VERSION ""

NS_ :

BS_ :

BU_: NMTMaster

BO_ 1919 HBGuard_127: 1 Vector__XXX
 SG_ Toggle : 7|1@1+ (1,0) [0|0] "" Vector__XXX
 SG_ State : 0|7@1+ (1,0) [0|0] "" Vector__XXX

BO_ 1918 HBGuard_126: 1 Vector__XXX
 SG_ Toggle : 7|1@1+ (1,0) [0|0] "" Vector__XXX
 SG_ State : 0|7@1+ (1,0) [0|0] "" Vector__XXX

BO_ 1917 HBGuard_125: 1 Vector__XXX
 SG_ Toggle : 7|1@1+ (1,0) [0|0] "" Vector__XXX
 SG_ State : 0|7@1+ (1,0) [0|0] "" Vector__XXX

BO_ 1916 HBGuard_124: 1 Vector__XXX
 SG_ Toggle : 7|1@1+ (1,0) [0|0] "" Vector__XXX
 SG_ State : 0|7@1+ (1,0) [0|0] "" Vector__XXX

BO_ 1915 HBGuard_123: 1 Vector__XXX
 SG_ Toggle : 7|1@1+ (1,0) [0|0] "" Vector__XXX
 SG_ State : 0|7@1+ (1,0) [0|0] "" Vector__XXX

BO_ 1914 HBGuard_122: 1 Vector__XXX
 SG_ Toggle : 7|1@1+ (1,0) [0|0] "" Vector__XXX
 SG_ State : 0|7@1+ (1,0) [0|0] "" Vector__XXX

BO_ 1913 HBGuard_121: 1 Vector__XXX
 SG_ Toggle : 7|1@1+ (1,0) [0|0] "" Vector__XXX
 SG_ State : 0|7@1+ (1,0) [0|0] "" Vector__XXX

BO_ 1912 HBGuard_120: 1 Vector__XXX
 SG_ Toggle : 7|1@1+ (1,0) [0|0] "" Vector__XXX
 SG_ State : 0|7@1+ (1,0) [0|0] "" Vector__XXX

BO_ 1911 HBGuard_119: 1 Vector__XXX
 SG_ Toggle : 7|1@1+ (1,0) [0|0] "" Vector__XXX
 SG_ State : 0|7@1+ (1,0) [0|0] "" Vector__XXX

BO_ 1910 HBGuard_118: 1 Vector__XXX
 SG_ Toggle : 7|1@1+ (1,0) [0|0] "" Vector__XXX
 SG_ State : 0|7@1+ (1,0) [0|0] "" Vector__XXX

BO_ 1909 HBGuard_117: 1 Vector__XXX
 SG_ Toggle : 7|1@1+ (1,0) [0|0] "" Vector__XXX
 SG_ State : 0|7@1+ (1,0) [0|0] "" Vector__XXX

BO_ 1908 HBGuard_116: 1 Vector__XXX
 SG_ Toggle : 7|1@1+ (1,0) [0|0] "" Vector__XXX
 SG_ State : 0|7@1+ (1,0) [0|0] "" Vector__XXX

BO_ 1907 HBGuard_115: 1 Vector__XXX
 SG_ Toggle : 7|1@1+ (1,0) [0|0] "" Vector__XXX
 SG_ State : 0|7@1+ (1,0) [0|0] "" Vector__XXX

BO_ 1906 HBGuard_114: 1 Vector__XXX
 SG_ Toggle : 7|1@1+ (1,0) [0|0] "" Vector__XXX
 SG_ State : 0|7@1+ (1,0) [0|0] "" Vector__XXX

BO_ 1905 HBGuard_113: 1 Vector__XXX
 SG_ Toggle : 7|1@1+ (1,0) [0|0] "" Vector__XXX
 SG_ State : 0|7@1+ (1,0) [0|0] "" Vector__XXX

BO_ 1904 HBGuard_112: 1 Vector__XXX
 SG_ Toggle : 7|1@1+ (1,0) [0|0] "" Vector__XXX
 SG_ State : 0|7@1+ (1,0) [0|0] "" Vector__XXX

BO_ 1903 HBGuard_111: 1 Vector__XXX
 SG_ Toggle : 7|1@1+ (1,0) [0|0] "" Vector__XXX
 SG_ State : 0|7@1+ (1,0) [0|0] "" Vector__XXX

BO_ 1902 HBGuard_110: 1 Vector__XXX
 SG_ Toggle : 7|1@1+ (1,0) [0|0] "" Vector__XXX
 SG_ State : 0|7@1+ (1,0) [0|0] "" Vector__XXX

BO_ 1901 HBGuard_109: 1 Vector__XXX
 SG_ Toggle : 7|1@1+ (1,0) [0|0] "" Vector__XXX
 SG_ State : 0|7@1+ (1,0) [0|0] "" Vector__XXX

BO_ 1900 HBGuard_108: 1 Vector__XXX
 SG_ Toggle : 7|1@1+ (1,0) [0|0] "" Vector__XXX
 SG_ State : 0|7@1+ (1,0) [0|0] "" Vector__XXX

BO_ 1899 HBGuard_107: 1 Vector__XXX
 SG_ Toggle : 7|1@1+ (1,0) [0|0] "" Vector__XXX
 SG_ State : 0|7@1+ (1,0) [0|0] "" Vector__XXX

BO_ 1898 HBGuard_106: 1 Vector__XXX
 SG_ Toggle : 7|1@1+ (1,0) [0|0] "" Vector__XXX
 SG_ State : 0|7@1+ (1,0) [0|0] "" Vector__XXX

BO_ 1897 HBGuard_105: 1 Vector__XXX
 SG_ Toggle : 7|1@1+ (1,0) [0|0] "" Vector__XXX
 SG_ State : 0|7@1+ (1,0) [0|0] "" Vector__XXX

BO_ 1896 HBGuard_104: 1 Vector__XXX
 SG_ Toggle : 7|1@1+ (1,0) [0|0] "" Vector__XXX
 SG_ State : 0|7@1+ (1,0) [0|0] "" Vector__XXX

BO_ 1895 HBGuard_103: 1 Vector__XXX
 SG_ Toggle : 7|1@1+ (1,0) [0|0] "" Vector__XXX
 SG_ State : 0|7@1+ (1,0) [0|0] "" Vector__XXX

BO_ 1894 HBGuard_102: 1 Vector__XXX
 SG_ Toggle : 7|1@1+ (1,0) [0|0] "" Vector__XXX
 SG_ State : 0|7@1+ (1,0) [0|0] "" Vector__XXX

BO_ 1893 HBGuard_101: 1 Vector__XXX
 SG_ Toggle : 7|1@1+ (1,0) [0|0] "" Vector__XXX
 SG_ State : 0|7@1+ (1,0) [0|0] "" Vector__XXX

BO_ 1892 HBGuard_100: 1 Vector__XXX
 SG_ Toggle : 7|1@1+ (1,0) [0|0] "" Vector__XXX
 SG_ State : 0|7@1+ (1,0) [0|0] "" Vector__XXX

BO_ 1891 HBGuard_099: 1 Vector__XXX
 SG_ Toggle : 7|1@1+ (1,0) [0|0] "" Vector__XXX
 SG_ State : 0|7@1+ (1,0) [0|0] "" Vector__XXX

BO_ 1890 HBGuard_098: 1 Vector__XXX
 SG_ Toggle : 7|1@1+ (1,0) [0|0] "" Vector__XXX
 SG_ State : 0|7@1+ (1,0) [0|0] "" Vector__XXX

BO_ 1889 HBGuard_097: 1 Vector__XXX
 SG_ Toggle : 7|1@1+ (1,0) [0|0] "" Vector__XXX
 SG_ State : 0|7@1+ (1,0) [0|0] "" Vector__XXX

BO_ 1888 HBGuard_096: 1 Vector__XXX
 SG_ Toggle : 7|1@1+ (1,0) [0|0] "" Vector__XXX
 SG_ State : 0|7@1+ (1,0) [0|0] "" Vector__XXX

BO_ 1887 HBGuard_095: 1 Vector__XXX
 SG_ Toggle : 7|1@1+ (1,0) [0|0] "" Vector__XXX
 SG_ State : 0|7@1+ (1,0) [0|0] "" Vector__XXX

BO_ 1886 HBGuard_094: 1 Vector__XXX
 SG_ Toggle : 7|1@1+ (1,0) [0|0] "" Vector__XXX
 SG_ State : 0|7@1+ (1,0) [0|0] "" Vector__XXX

BO_ 1885 HBGuard_093: 1 Vector__XXX
 SG_ Toggle : 7|1@1+ (1,0) [0|0] "" Vector__XXX
 SG_ State : 0|7@1+ (1,0) [0|0] "" Vector__XXX

BO_ 1884 HBGuard_092: 1 Vector__XXX
 SG_ Toggle : 7|1@1+ (1,0) [0|0] "" Vector__XXX
 SG_ State : 0|7@1+ (1,0) [0|0] "" Vector__XXX

BO_ 1883 HBGuard_091: 1 Vector__XXX
 SG_ Toggle : 7|1@1+ (1,0) [0|0] "" Vector__XXX
 SG_ State : 0|7@1+ (1,0) [0|0] "" Vector__XXX

BO_ 1882 HBGuard_090: 1 Vector__XXX
 SG_ Toggle : 7|1@1+ (1,0) [0|0] "" Vector__XXX
 SG_ State : 0|7@1+ (1,0) [0|0] "" Vector__XXX

BO_ 1881 HBGuard_089: 1 Vector__XXX
 SG_ Toggle : 7|1@1+ (1,0) [0|0] "" Vector__XXX
 SG_ State : 0|7@1+ (1,0) [0|0] "" Vector__XXX

BO_ 1880 HBGuard_088: 1 Vector__XXX
 SG_ Toggle : 7|1@1+ (1,0) [0|0] "" Vector__XXX
 SG_ State : 0|7@1+ (1,0) [0|0] "" Vector__XXX

BO_ 1879 HBGuard_087: 1 Vector__XXX
 SG_ Toggle : 7|1@1+ (1,0) [0|0] "" Vector__XXX
 SG_ State : 0|7@1+ (1,0) [0|0] "" Vector__XXX

BO_ 1878 HBGuard_086: 1 Vector__XXX
 SG_ Toggle : 7|1@1+ (1,0) [0|0] "" Vector__XXX
 SG_ State : 0|7@1+ (1,0) [0|0] "" Vector__XXX

BO_ 1877 HBGuard_085: 1 Vector__XXX
 SG_ Toggle : 7|1@1+ (1,0) [0|0] "" Vector__XXX
 SG_ State : 0|7@1+ (1,0) [0|0] "" Vector__XXX

BO_ 1876 HBGuard_084: 1 Vector__XXX
 SG_ Toggle : 7|1@1+ (1,0) [0|0] "" Vector__XXX
 SG_ State : 0|7@1+ (1,0) [0|0] "" Vector__XXX

BO_ 1875 HBGuard_083: 1 Vector__XXX
 SG_ Toggle : 7|1@1+ (1,0) [0|0] "" Vector__XXX
 SG_ State : 0|7@1+ (1,0) [0|0] "" Vector__XXX

BO_ 1874 HBGuard_082: 1 Vector__XXX
 SG_ Toggle : 7|1@1+ (1,0) [0|0] "" Vector__XXX
 SG_ State : 0|7@1+ (1,0) [0|0] "" Vector__XXX

BO_ 1873 HBGuard_081: 1 Vector__XXX
 SG_ Toggle : 7|1@1+ (1,0) [0|0] "" Vector__XXX
 SG_ State : 0|7@1+ (1,0) [0|0] "" Vector__XXX

BO_ 1872 HBGuard_080: 1 Vector__XXX
 SG_ Toggle : 7|1@1+ (1,0) [0|0] "" Vector__XXX
 SG_ State : 0|7@1+ (1,0) [0|0] "" Vector__XXX

BO_ 1871 HBGuard_079: 1 Vector__XXX
 SG_ Toggle : 7|1@1+ (1,0) [0|0] "" Vector__XXX
 SG_ State : 0|7@1+ (1,0) [0|0] "" Vector__XXX

BO_ 1870 HBGuard_078: 1 Vector__XXX
 SG_ Toggle : 7|1@1+ (1,0) [0|0] "" Vector__XXX
 SG_ State : 0|7@1+ (1,0) [0|0] "" Vector__XXX

BO_ 1869 HBGuard_077: 1 Vector__XXX
 SG_ Toggle : 7|1@1+ (1,0) [0|0] "" Vector__XXX
 SG_ State : 0|7@1+ (1,0) [0|0] "" Vector__XXX

BO_ 1868 HBGuard_076: 1 Vector__XXX
 SG_ Toggle : 7|1@1+ (1,0) [0|0] "" Vector__XXX
 SG_ State : 0|7@1+ (1,0) [0|0] "" Vector__XXX

BO_ 1867 HBGuard_075: 1 Vector__XXX
 SG_ Toggle : 7|1@1+ (1,0) [0|0] "" Vector__XXX
 SG_ State : 0|7@1+ (1,0) [0|0] "" Vector__XXX

BO_ 1866 HBGuard_074: 1 Vector__XXX
 SG_ Toggle : 7|1@1+ (1,0) [0|0] "" Vector__XXX
 SG_ State : 0|7@1+ (1,0) [0|0] "" Vector__XXX

BO_ 1865 HBGuard_073: 1 Vector__XXX
 SG_ Toggle : 7|1@1+ (1,0) [0|0] "" Vector__XXX
 SG_ State : 0|7@1+ (1,0) [0|0] "" Vector__XXX

BO_ 1864 HBGuard_072: 1 Vector__XXX
 SG_ Toggle : 7|1@1+ (1,0) [0|0] "" Vector__XXX
 SG_ State : 0|7@1+ (1,0) [0|0] "" Vector__XXX

BO_ 1863 HBGuard_071: 1 Vector__XXX
 SG_ Toggle : 7|1@1+ (1,0) [0|0] "" Vector__XXX
 SG_ State : 0|7@1+ (1,0) [0|0] "" Vector__XXX

BO_ 1862 HBGuard_070: 1 Vector__XXX
 SG_ Toggle : 7|1@1+ (1,0) [0|0] "" Vector__XXX
 SG_ State : 0|7@1+ (1,0) [0|0] "" Vector__XXX

BO_ 1861 HBGuard_069: 1 Vector__XXX
 SG_ Toggle : 7|1@1+ (1,0) [0|0] "" Vector__XXX
 SG_ State : 0|7@1+ (1,0) [0|0] "" Vector__XXX

BO_ 1860 HBGuard_068: 1 Vector__XXX
 SG_ Toggle : 7|1@1+ (1,0) [0|0] "" Vector__XXX
 SG_ State : 0|7@1+ (1,0) [0|0] "" Vector__XXX

BO_ 1859 HBGuard_067: 1 Vector__XXX
 SG_ Toggle : 7|1@1+ (1,0) [0|0] "" Vector__XXX
 SG_ State : 0|7@1+ (1,0) [0|0] "" Vector__XXX

BO_ 1858 HBGuard_066: 1 Vector__XXX
 SG_ Toggle : 7|1@1+ (1,0) [0|0] "" Vector__XXX
 SG_ State : 0|7@1+ (1,0) [0|0] "" Vector__XXX

BO_ 1857 HBGuard_065: 1 Vector__XXX
 SG_ Toggle : 7|1@1+ (1,0) [0|0] "" Vector__XXX
 SG_ State : 0|7@1+ (1,0) [0|0] "" Vector__XXX

BO_ 1856 HBGuard_064: 1 Vector__XXX
 SG_ Toggle : 7|1@1+ (1,0) [0|0] "" Vector__XXX
 SG_ State : 0|7@1+ (1,0) [0|0] "" Vector__XXX

BO_ 1855 HBGuard_063: 1 Vector__XXX
 SG_ Toggle : 7|1@1+ (1,0) [0|0] "" Vector__XXX
 SG_ State : 0|7@1+ (1,0) [0|0] "" Vector__XXX

BO_ 1854 HBGuard_062: 1 Vector__XXX
 SG_ Toggle : 7|1@1+ (1,0) [0|0] "" Vector__XXX
 SG_ State : 0|7@1+ (1,0) [0|0] "" Vector__XXX

BO_ 1853 HBGuard_061: 1 Vector__XXX
 SG_ Toggle : 7|1@1+ (1,0) [0|0] "" Vector__XXX
 SG_ State : 0|7@1+ (1,0) [0|0] "" Vector__XXX

BO_ 1852 HBGuard_060: 1 Vector__XXX
 SG_ Toggle : 7|1@1+ (1,0) [0|0] "" Vector__XXX
 SG_ State : 0|7@1+ (1,0) [0|0] "" Vector__XXX

BO_ 1851 HBGuard_059: 1 Vector__XXX
 SG_ Toggle : 7|1@1+ (1,0) [0|0] "" Vector__XXX
 SG_ State : 0|7@1+ (1,0) [0|0] "" Vector__XXX

BO_ 1850 HBGuard_058: 1 Vector__XXX
 SG_ Toggle : 7|1@1+ (1,0) [0|0] "" Vector__XXX
 SG_ State : 0|7@1+ (1,0) [0|0] "" Vector__XXX

BO_ 1849 HBGuard_057: 1 Vector__XXX
 SG_ Toggle : 7|1@1+ (1,0) [0|0] "" Vector__XXX
 SG_ State : 0|7@1+ (1,0) [0|0] "" Vector__XXX

BO_ 1848 HBGuard_056: 1 Vector__XXX
 SG_ Toggle : 7|1@1+ (1,0) [0|0] "" Vector__XXX
 SG_ State : 0|7@1+ (1,0) [0|0] "" Vector__XXX

BO_ 1847 HBGuard_055: 1 Vector__XXX
 SG_ Toggle : 7|1@1+ (1,0) [0|0] "" Vector__XXX
 SG_ State : 0|7@1+ (1,0) [0|0] "" Vector__XXX

BO_ 1846 HBGuard_054: 1 Vector__XXX
 SG_ Toggle : 7|1@1+ (1,0) [0|0] "" Vector__XXX
 SG_ State : 0|7@1+ (1,0) [0|0] "" Vector__XXX

BO_ 1845 HBGuard_053: 1 Vector__XXX
 SG_ Toggle : 7|1@1+ (1,0) [0|0] "" Vector__XXX
 SG_ State : 0|7@1+ (1,0) [0|0] "" Vector__XXX

BO_ 1844 HBGuard_052: 1 Vector__XXX
 SG_ Toggle : 7|1@1+ (1,0) [0|0] "" Vector__XXX
 SG_ State : 0|7@1+ (1,0) [0|0] "" Vector__XXX

BO_ 1843 HBGuard_051: 1 Vector__XXX
 SG_ Toggle : 7|1@1+ (1,0) [0|0] "" Vector__XXX
 SG_ State : 0|7@1+ (1,0) [0|0] "" Vector__XXX

BO_ 1842 HBGuard_050: 1 Vector__XXX
 SG_ Toggle : 7|1@1+ (1,0) [0|0] "" Vector__XXX
 SG_ State : 0|7@1+ (1,0) [0|0] "" Vector__XXX

BO_ 1841 HBGuard_049: 1 Vector__XXX
 SG_ Toggle : 7|1@1+ (1,0) [0|0] "" Vector__XXX
 SG_ State : 0|7@1+ (1,0) [0|0] "" Vector__XXX

BO_ 1840 HBGuard_048: 1 Vector__XXX
 SG_ Toggle : 7|1@1+ (1,0) [0|0] "" Vector__XXX
 SG_ State : 0|7@1+ (1,0) [0|0] "" Vector__XXX

BO_ 1839 HBGuard_047: 1 Vector__XXX
 SG_ Toggle : 7|1@1+ (1,0) [0|0] "" Vector__XXX
 SG_ State : 0|7@1+ (1,0) [0|0] "" Vector__XXX

BO_ 1838 HBGuard_046: 1 Vector__XXX
 SG_ Toggle : 7|1@1+ (1,0) [0|0] "" Vector__XXX
 SG_ State : 0|7@1+ (1,0) [0|0] "" Vector__XXX

BO_ 1837 HBGuard_045: 1 Vector__XXX
 SG_ Toggle : 7|1@1+ (1,0) [0|0] "" Vector__XXX
 SG_ State : 0|7@1+ (1,0) [0|0] "" Vector__XXX

BO_ 1836 HBGuard_044: 1 Vector__XXX
 SG_ Toggle : 7|1@1+ (1,0) [0|0] "" Vector__XXX
 SG_ State : 0|7@1+ (1,0) [0|0] "" Vector__XXX

BO_ 1835 HBGuard_043: 1 Vector__XXX
 SG_ Toggle : 7|1@1+ (1,0) [0|0] "" Vector__XXX
 SG_ State : 0|7@1+ (1,0) [0|0] "" Vector__XXX

BO_ 1834 HBGuard_042: 1 Vector__XXX
 SG_ Toggle : 7|1@1+ (1,0) [0|0] "" Vector__XXX
 SG_ State : 0|7@1+ (1,0) [0|0] "" Vector__XXX

BO_ 1833 HBGuard_041: 1 Vector__XXX
 SG_ Toggle : 7|1@1+ (1,0) [0|0] "" Vector__XXX
 SG_ State : 0|7@1+ (1,0) [0|0] "" Vector__XXX

BO_ 1832 HBGuard_040: 1 Vector__XXX
 SG_ Toggle : 7|1@1+ (1,0) [0|0] "" Vector__XXX
 SG_ State : 0|7@1+ (1,0) [0|0] "" Vector__XXX

BO_ 1831 HBGuard_039: 1 Vector__XXX
 SG_ Toggle : 7|1@1+ (1,0) [0|0] "" Vector__XXX
 SG_ State : 0|7@1+ (1,0) [0|0] "" Vector__XXX

BO_ 1830 HBGuard_038: 1 Vector__XXX
 SG_ Toggle : 7|1@1+ (1,0) [0|0] "" Vector__XXX
 SG_ State : 0|7@1+ (1,0) [0|0] "" Vector__XXX

BO_ 1829 HBGuard_037: 1 Vector__XXX
 SG_ Toggle : 7|1@1+ (1,0) [0|0] "" Vector__XXX
 SG_ State : 0|7@1+ (1,0) [0|0] "" Vector__XXX

BO_ 1828 HBGuard_036: 1 Vector__XXX
 SG_ Toggle : 7|1@1+ (1,0) [0|0] "" Vector__XXX
 SG_ State : 0|7@1+ (1,0) [0|0] "" Vector__XXX

BO_ 1827 HBGuard_035: 1 Vector__XXX
 SG_ Toggle : 7|1@1+ (1,0) [0|0] "" Vector__XXX
 SG_ State : 0|7@1+ (1,0) [0|0] "" Vector__XXX

BO_ 1826 HBGuard_034: 1 Vector__XXX
 SG_ Toggle : 7|1@1+ (1,0) [0|0] "" Vector__XXX
 SG_ State : 0|7@1+ (1,0) [0|0] "" Vector__XXX

BO_ 1825 HBGuard_033: 1 Vector__XXX
 SG_ Toggle : 7|1@1+ (1,0) [0|0] "" Vector__XXX
 SG_ State : 0|7@1+ (1,0) [0|0] "" Vector__XXX

BO_ 1824 HBGuard_032: 1 Vector__XXX
 SG_ Toggle : 7|1@1+ (1,0) [0|0] "" Vector__XXX
 SG_ State : 0|7@1+ (1,0) [0|0] "" Vector__XXX

BO_ 1823 HBGuard_031: 1 Vector__XXX
 SG_ Toggle : 7|1@1+ (1,0) [0|0] "" Vector__XXX
 SG_ State : 0|7@1+ (1,0) [0|0] "" Vector__XXX

BO_ 1822 HBGuard_030: 1 Vector__XXX
 SG_ Toggle : 7|1@1+ (1,0) [0|0] "" Vector__XXX
 SG_ State : 0|7@1+ (1,0) [0|0] "" Vector__XXX

BO_ 1821 HBGuard_029: 1 Vector__XXX
 SG_ Toggle : 7|1@1+ (1,0) [0|0] "" Vector__XXX
 SG_ State : 0|7@1+ (1,0) [0|0] "" Vector__XXX

BO_ 1820 HBGuard_028: 1 Vector__XXX
 SG_ Toggle : 7|1@1+ (1,0) [0|0] "" Vector__XXX
 SG_ State : 0|7@1+ (1,0) [0|0] "" Vector__XXX

BO_ 1819 HBGuard_027: 1 Vector__XXX
 SG_ Toggle : 7|1@1+ (1,0) [0|0] "" Vector__XXX
 SG_ State : 0|7@1+ (1,0) [0|0] "" Vector__XXX

BO_ 1818 HBGuard_026: 1 Vector__XXX
 SG_ Toggle : 7|1@1+ (1,0) [0|0] "" Vector__XXX
 SG_ State : 0|7@1+ (1,0) [0|0] "" Vector__XXX

BO_ 1817 HBGuard_025: 1 Vector__XXX
 SG_ Toggle : 7|1@1+ (1,0) [0|0] "" Vector__XXX
 SG_ State : 0|7@1+ (1,0) [0|0] "" Vector__XXX

BO_ 1816 HBGuard_024: 1 Vector__XXX
 SG_ Toggle : 7|1@1+ (1,0) [0|0] "" Vector__XXX
 SG_ State : 0|7@1+ (1,0) [0|0] "" Vector__XXX

BO_ 1815 HBGuard_023: 1 Vector__XXX
 SG_ Toggle : 7|1@1+ (1,0) [0|0] "" Vector__XXX
 SG_ State : 0|7@1+ (1,0) [0|0] "" Vector__XXX

BO_ 1814 HBGuard_022: 1 Vector__XXX
 SG_ Toggle : 7|1@1+ (1,0) [0|0] "" Vector__XXX
 SG_ State : 0|7@1+ (1,0) [0|0] "" Vector__XXX

BO_ 1813 HBGuard_021: 1 Vector__XXX
 SG_ Toggle : 7|1@1+ (1,0) [0|0] "" Vector__XXX
 SG_ State : 0|7@1+ (1,0) [0|0] "" Vector__XXX

BO_ 1812 HBGuard_020: 1 Vector__XXX
 SG_ Toggle : 7|1@1+ (1,0) [0|0] "" Vector__XXX
 SG_ State : 0|7@1+ (1,0) [0|0] "" Vector__XXX

BO_ 1811 HBGuard_019: 1 Vector__XXX
 SG_ Toggle : 7|1@1+ (1,0) [0|0] "" Vector__XXX
 SG_ State : 0|7@1+ (1,0) [0|0] "" Vector__XXX

BO_ 1810 HBGuard_018: 1 Vector__XXX
 SG_ Toggle : 7|1@1+ (1,0) [0|0] "" Vector__XXX
 SG_ State : 0|7@1+ (1,0) [0|0] "" Vector__XXX

BO_ 1809 HBGuard_017: 1 Vector__XXX
 SG_ Toggle : 7|1@1+ (1,0) [0|0] "" Vector__XXX
 SG_ State : 0|7@1+ (1,0) [0|0] "" Vector__XXX

BO_ 1808 HBGuard_016: 1 Vector__XXX
 SG_ Toggle : 7|1@1+ (1,0) [0|0] "" Vector__XXX
 SG_ State : 0|7@1+ (1,0) [0|0] "" Vector__XXX

BO_ 1807 HBGuard_015: 1 Vector__XXX
 SG_ Toggle : 7|1@1+ (1,0) [0|0] "" Vector__XXX
 SG_ State : 0|7@1+ (1,0) [0|0] "" Vector__XXX

BO_ 1806 HBGuard_014: 1 Vector__XXX
 SG_ Toggle : 7|1@1+ (1,0) [0|0] "" Vector__XXX
 SG_ State : 0|7@1+ (1,0) [0|0] "" Vector__XXX

BO_ 1805 HBGuard_013: 1 Vector__XXX
 SG_ Toggle : 7|1@1+ (1,0) [0|0] "" Vector__XXX
 SG_ State : 0|7@1+ (1,0) [0|0] "" Vector__XXX

BO_ 1804 HBGuard_012: 1 Vector__XXX
 SG_ Toggle : 7|1@1+ (1,0) [0|0] "" Vector__XXX
 SG_ State : 0|7@1+ (1,0) [0|0] "" Vector__XXX

BO_ 1803 HBGuard_011: 1 Vector__XXX
 SG_ Toggle : 7|1@1+ (1,0) [0|0] "" Vector__XXX
 SG_ State : 0|7@1+ (1,0) [0|0] "" Vector__XXX

BO_ 1802 HBGuard_010: 1 Vector__XXX
 SG_ Toggle : 7|1@1+ (1,0) [0|0] "" Vector__XXX
 SG_ State : 0|7@1+ (1,0) [0|0] "" Vector__XXX

BO_ 1801 HBGuard_009: 1 Vector__XXX
 SG_ Toggle : 7|1@1+ (1,0) [0|0] "" Vector__XXX
 SG_ State : 0|7@1+ (1,0) [0|0] "" Vector__XXX

BO_ 1800 HBGuard_008: 1 Vector__XXX
 SG_ Toggle : 7|1@1+ (1,0) [0|0] "" Vector__XXX
 SG_ State : 0|7@1+ (1,0) [0|0] "" Vector__XXX

BO_ 1799 HBGuard_007: 1 Vector__XXX
 SG_ Toggle : 7|1@1+ (1,0) [0|0] "" Vector__XXX
 SG_ State : 0|7@1+ (1,0) [0|0] "" Vector__XXX

BO_ 1798 HBGuard_006: 1 Vector__XXX
 SG_ Toggle : 7|1@1+ (1,0) [0|0] "" Vector__XXX
 SG_ State : 0|7@1+ (1,0) [0|0] "" Vector__XXX

BO_ 1797 HBGuard_005: 1 Vector__XXX
 SG_ Toggle : 7|1@1+ (1,0) [0|0] "" Vector__XXX
 SG_ State : 0|7@1+ (1,0) [0|0] "" Vector__XXX

BO_ 1796 HBGuard_004: 1 Vector__XXX
 SG_ Toggle : 7|1@1+ (1,0) [0|0] "" Vector__XXX
 SG_ State : 0|7@1+ (1,0) [0|0] "" Vector__XXX

BO_ 1795 HBGuard_003: 1 Vector__XXX
 SG_ Toggle : 7|1@1+ (1,0) [0|0] "" Vector__XXX
 SG_ State : 0|7@1+ (1,0) [0|0] "" Vector__XXX

BO_ 1794 HBGuard_002: 1 Vector__XXX
 SG_ Toggle : 7|1@1+ (1,0) [0|0] "" Vector__XXX
 SG_ State : 0|7@1+ (1,0) [0|0] "" Vector__XXX

BO_ 1793 HBGuard_001: 1 Vector__XXX
 SG_ Toggle : 7|1@1+ (1,0) [0|0] "" Vector__XXX
 SG_ State : 0|7@1+ (1,0) [0|0] "" Vector__XXX

BO_ 1760 DynSDOReq: 0 Vector__XXX

BO_ 2021 LSS_M: 8 Vector__XXX

BO_ 2020 LSS_S: 8 Vector__XXX

BO_ 1535 SSDO_127: 8 Vector__XXX

BO_ 1534 SSDO_126: 8 Vector__XXX

BO_ 1533 SSDO_125: 8 Vector__XXX

BO_ 1532 SSDO_124: 8 Vector__XXX

BO_ 1531 SSDO_123: 8 Vector__XXX

BO_ 1530 SSDO_122: 8 Vector__XXX

BO_ 1529 SSDO_121: 8 Vector__XXX

BO_ 1528 SSDO_120: 8 Vector__XXX

BO_ 1527 SSDO_119: 8 Vector__XXX

BO_ 1526 SSDO_118: 8 Vector__XXX

BO_ 1525 SSDO_117: 8 Vector__XXX

BO_ 1524 SSDO_116: 8 Vector__XXX

BO_ 1523 SSDO_115: 8 Vector__XXX

BO_ 1522 SSDO_114: 8 Vector__XXX

BO_ 1521 SSDO_113: 8 Vector__XXX

BO_ 1520 SSDO_112: 8 Vector__XXX

BO_ 1519 SSDO_111: 8 Vector__XXX

BO_ 1518 SSDO_110: 8 Vector__XXX

BO_ 1517 SSDO_109: 8 Vector__XXX

BO_ 1516 SSDO_108: 8 Vector__XXX

BO_ 1515 SSDO_107: 8 Vector__XXX

BO_ 1514 SSDO_106: 8 Vector__XXX

BO_ 1513 SSDO_105: 8 Vector__XXX

BO_ 1512 SSDO_104: 8 Vector__XXX

BO_ 1511 SSDO_103: 8 Vector__XXX

BO_ 1510 SSDO_102: 8 Vector__XXX

BO_ 1509 SSDO_101: 8 Vector__XXX

BO_ 1508 SSDO_100: 8 Vector__XXX

BO_ 1507 SSDO_099: 8 Vector__XXX

BO_ 1506 SSDO_098: 8 Vector__XXX

BO_ 1505 SSDO_097: 8 Vector__XXX

BO_ 1504 SSDO_096: 8 Vector__XXX

BO_ 1503 SSDO_095: 8 Vector__XXX

BO_ 1502 SSDO_094: 8 Vector__XXX

BO_ 1501 SSDO_093: 8 Vector__XXX

BO_ 1500 SSDO_092: 8 Vector__XXX

BO_ 1499 SSDO_091: 8 Vector__XXX

BO_ 1498 SSDO_090: 8 Vector__XXX

BO_ 1497 SSDO_089: 8 Vector__XXX

BO_ 1496 SSDO_088: 8 Vector__XXX

BO_ 1495 SSDO_087: 8 Vector__XXX

BO_ 1494 SSDO_086: 8 Vector__XXX

BO_ 1493 SSDO_085: 8 Vector__XXX

BO_ 1492 SSDO_084: 8 Vector__XXX

BO_ 1491 SSDO_083: 8 Vector__XXX

BO_ 1490 SSDO_082: 8 Vector__XXX

BO_ 1489 SSDO_081: 8 Vector__XXX

BO_ 1488 SSDO_080: 8 Vector__XXX

BO_ 1487 SSDO_079: 8 Vector__XXX

BO_ 1486 SSDO_078: 8 Vector__XXX

BO_ 1485 SSDO_077: 8 Vector__XXX

BO_ 1484 SSDO_076: 8 Vector__XXX

BO_ 1483 SSDO_075: 8 Vector__XXX

BO_ 1482 SSDO_074: 8 Vector__XXX

BO_ 1481 SSDO_073: 8 Vector__XXX

BO_ 1480 SSDO_072: 8 Vector__XXX

BO_ 1479 SSDO_071: 8 Vector__XXX

BO_ 1478 SSDO_070: 8 Vector__XXX

BO_ 1477 SSDO_069: 8 Vector__XXX

BO_ 1476 SSDO_068: 8 Vector__XXX

BO_ 1475 SSDO_067: 8 Vector__XXX

BO_ 1474 SSDO_066: 8 Vector__XXX

BO_ 1473 SSDO_065: 8 Vector__XXX

BO_ 1472 SSDO_064: 8 Vector__XXX

BO_ 1471 SSDO_063: 8 Vector__XXX

BO_ 1470 SSDO_062: 8 Vector__XXX

BO_ 1469 SSDO_061: 8 Vector__XXX

BO_ 1468 SSDO_060: 8 Vector__XXX

BO_ 1467 SSDO_059: 8 Vector__XXX

BO_ 1466 SSDO_058: 8 Vector__XXX

BO_ 1465 SSDO_057: 8 Vector__XXX

BO_ 1464 SSDO_056: 8 Vector__XXX

BO_ 1463 SSDO_055: 8 Vector__XXX

BO_ 1462 SSDO_054: 8 Vector__XXX

BO_ 1461 SSDO_053: 8 Vector__XXX

BO_ 1460 SSDO_052: 8 Vector__XXX

BO_ 1459 SSDO_051: 8 Vector__XXX

BO_ 1458 SSDO_050: 8 Vector__XXX

BO_ 1457 SSDO_049: 8 Vector__XXX

BO_ 1456 SSDO_048: 8 Vector__XXX

BO_ 1455 SSDO_047: 8 Vector__XXX

BO_ 1454 SSDO_046: 8 Vector__XXX

BO_ 1453 SSDO_045: 8 Vector__XXX

BO_ 1452 SSDO_044: 8 Vector__XXX

BO_ 1451 SSDO_043: 8 Vector__XXX

BO_ 1450 SSDO_042: 8 Vector__XXX

BO_ 1449 SSDO_041: 8 Vector__XXX

BO_ 1448 SSDO_040: 8 Vector__XXX

BO_ 1447 SSDO_039: 8 Vector__XXX

BO_ 1446 SSDO_038: 8 Vector__XXX

BO_ 1445 SSDO_037: 8 Vector__XXX

BO_ 1444 SSDO_036: 8 Vector__XXX

BO_ 1443 SSDO_035: 8 Vector__XXX

BO_ 1442 SSDO_034: 8 Vector__XXX

BO_ 1441 SSDO_033: 8 Vector__XXX

BO_ 1440 SSDO_032: 8 Vector__XXX

BO_ 1439 SSDO_031: 8 Vector__XXX

BO_ 1438 SSDO_030: 8 Vector__XXX

BO_ 1437 SSDO_029: 8 Vector__XXX

BO_ 1436 SSDO_028: 8 Vector__XXX

BO_ 1435 SSDO_027: 8 Vector__XXX

BO_ 1434 SSDO_026: 8 Vector__XXX

BO_ 1433 SSDO_025: 8 Vector__XXX

BO_ 1432 SSDO_024: 8 Vector__XXX

BO_ 1431 SSDO_023: 8 Vector__XXX

BO_ 1430 SSDO_022: 8 Vector__XXX

BO_ 1429 SSDO_021: 8 Vector__XXX

BO_ 1428 SSDO_020: 8 Vector__XXX

BO_ 1427 SSDO_019: 8 Vector__XXX

BO_ 1426 SSDO_018: 8 Vector__XXX

BO_ 1425 SSDO_017: 8 Vector__XXX

BO_ 1424 SSDO_016: 8 Vector__XXX

BO_ 1423 SSDO_015: 8 Vector__XXX

BO_ 1422 SSDO_014: 8 Vector__XXX

BO_ 1421 SSDO_013: 8 Vector__XXX

BO_ 1420 SSDO_012: 8 Vector__XXX

BO_ 1419 SSDO_011: 8 Vector__XXX

BO_ 1418 SSDO_010: 8 Vector__XXX

BO_ 1417 SSDO_009: 8 Vector__XXX

BO_ 1416 SSDO_008: 8 Vector__XXX

BO_ 1415 SSDO_007: 8 Vector__XXX

BO_ 1414 SSDO_006: 8 Vector__XXX

BO_ 1413 SSDO_005: 8 Vector__XXX

BO_ 1412 SSDO_004: 8 Vector__XXX

BO_ 1411 SSDO_003: 8 Vector__XXX

BO_ 1410 SSDO_002: 8 Vector__XXX

BO_ 1409 SSDO_001: 8 Vector__XXX

BO_ 1663 CSDO_127: 8 Vector__XXX

BO_ 1662 CSDO_126: 8 Vector__XXX

BO_ 1661 CSDO_125: 8 Vector__XXX

BO_ 1660 CSDO_124: 8 Vector__XXX

BO_ 1659 CSDO_123: 8 Vector__XXX

BO_ 1658 CSDO_122: 8 Vector__XXX

BO_ 1657 CSDO_121: 8 Vector__XXX

BO_ 1656 CSDO_120: 8 Vector__XXX

BO_ 1655 CSDO_119: 8 Vector__XXX

BO_ 1654 CSDO_118: 8 Vector__XXX

BO_ 1653 CSDO_117: 8 Vector__XXX

BO_ 1652 CSDO_116: 8 Vector__XXX

BO_ 1651 CSDO_115: 8 Vector__XXX

BO_ 1650 CSDO_114: 8 Vector__XXX

BO_ 1649 CSDO_113: 8 Vector__XXX

BO_ 1648 CSDO_112: 8 Vector__XXX

BO_ 1647 CSDO_111: 8 Vector__XXX

BO_ 1646 CSDO_110: 8 Vector__XXX

BO_ 1645 CSDO_109: 8 Vector__XXX

BO_ 1644 CSDO_108: 8 Vector__XXX

BO_ 1643 CSDO_107: 8 Vector__XXX

BO_ 1642 CSDO_106: 8 Vector__XXX

BO_ 1641 CSDO_105: 8 Vector__XXX

BO_ 1640 CSDO_104: 8 Vector__XXX

BO_ 1639 CSDO_103: 8 Vector__XXX

BO_ 1638 CSDO_102: 8 Vector__XXX

BO_ 1637 CSDO_101: 8 Vector__XXX

BO_ 1636 CSDO_100: 8 Vector__XXX

BO_ 1635 CSDO_099: 8 Vector__XXX

BO_ 1634 CSDO_098: 8 Vector__XXX

BO_ 1633 CSDO_097: 8 Vector__XXX

BO_ 1632 CSDO_096: 8 Vector__XXX

BO_ 1631 CSDO_095: 8 Vector__XXX

BO_ 1630 CSDO_094: 8 Vector__XXX

BO_ 1629 CSDO_093: 8 Vector__XXX

BO_ 1628 CSDO_092: 8 Vector__XXX

BO_ 1627 CSDO_091: 8 Vector__XXX

BO_ 1626 CSDO_090: 8 Vector__XXX

BO_ 1625 CSDO_089: 8 Vector__XXX

BO_ 1624 CSDO_088: 8 Vector__XXX

BO_ 1623 CSDO_087: 8 Vector__XXX

BO_ 1622 CSDO_086: 8 Vector__XXX

BO_ 1621 CSDO_085: 8 Vector__XXX

BO_ 1620 CSDO_084: 8 Vector__XXX

BO_ 1619 CSDO_083: 8 Vector__XXX

BO_ 1618 CSDO_082: 8 Vector__XXX

BO_ 1617 CSDO_081: 8 Vector__XXX

BO_ 1616 CSDO_080: 8 Vector__XXX

BO_ 1615 CSDO_079: 8 Vector__XXX

BO_ 1614 CSDO_078: 8 Vector__XXX

BO_ 1613 CSDO_077: 8 Vector__XXX

BO_ 1612 CSDO_076: 8 Vector__XXX

BO_ 1611 CSDO_075: 8 Vector__XXX

BO_ 1610 CSDO_074: 8 Vector__XXX

BO_ 1609 CSDO_073: 8 Vector__XXX

BO_ 1608 CSDO_072: 8 Vector__XXX

BO_ 1607 CSDO_071: 8 Vector__XXX

BO_ 1606 CSDO_070: 8 Vector__XXX

BO_ 1605 CSDO_069: 8 Vector__XXX

BO_ 1604 CSDO_068: 8 Vector__XXX

BO_ 1603 CSDO_067: 8 Vector__XXX

BO_ 1602 CSDO_066: 8 Vector__XXX

BO_ 1601 CSDO_065: 8 Vector__XXX

BO_ 1600 CSDO_064: 8 Vector__XXX

BO_ 1599 CSDO_063: 8 Vector__XXX

BO_ 1598 CSDO_062: 8 Vector__XXX

BO_ 1597 CSDO_061: 8 Vector__XXX

BO_ 1596 CSDO_060: 8 Vector__XXX

BO_ 1595 CSDO_059: 8 Vector__XXX

BO_ 1594 CSDO_058: 8 Vector__XXX

BO_ 1593 CSDO_057: 8 Vector__XXX

BO_ 1592 CSDO_056: 8 Vector__XXX

BO_ 1591 CSDO_055: 8 Vector__XXX

BO_ 1590 CSDO_054: 8 Vector__XXX

BO_ 1589 CSDO_053: 8 Vector__XXX

BO_ 1588 CSDO_052: 8 Vector__XXX

BO_ 1587 CSDO_051: 8 Vector__XXX

BO_ 1586 CSDO_050: 8 Vector__XXX

BO_ 1585 CSDO_049: 8 Vector__XXX

BO_ 1584 CSDO_048: 8 Vector__XXX

BO_ 1583 CSDO_047: 8 Vector__XXX

BO_ 1582 CSDO_046: 8 Vector__XXX

BO_ 1581 CSDO_045: 8 Vector__XXX

BO_ 1580 CSDO_044: 8 Vector__XXX

BO_ 1579 CSDO_043: 8 Vector__XXX

BO_ 1578 CSDO_042: 8 Vector__XXX

BO_ 1577 CSDO_041: 8 Vector__XXX

BO_ 1576 CSDO_040: 8 Vector__XXX

BO_ 1575 CSDO_039: 8 Vector__XXX

BO_ 1574 CSDO_038: 8 Vector__XXX

BO_ 1573 CSDO_037: 8 Vector__XXX

BO_ 1572 CSDO_036: 8 Vector__XXX

BO_ 1571 CSDO_035: 8 Vector__XXX

BO_ 1570 CSDO_034: 8 Vector__XXX

BO_ 1569 CSDO_033: 8 Vector__XXX

BO_ 1568 CSDO_032: 8 Vector__XXX

BO_ 1567 CSDO_031: 8 Vector__XXX

BO_ 1566 CSDO_030: 8 Vector__XXX

BO_ 1565 CSDO_029: 8 Vector__XXX

BO_ 1564 CSDO_028: 8 Vector__XXX

BO_ 1563 CSDO_027: 8 Vector__XXX

BO_ 1562 CSDO_026: 8 Vector__XXX

BO_ 1561 CSDO_025: 8 Vector__XXX

BO_ 1560 CSDO_024: 8 Vector__XXX

BO_ 1559 CSDO_023: 8 Vector__XXX

BO_ 1558 CSDO_022: 8 Vector__XXX

BO_ 1557 CSDO_021: 8 Vector__XXX

BO_ 1556 CSDO_020: 8 Vector__XXX

BO_ 1555 CSDO_019: 8 Vector__XXX

BO_ 1554 CSDO_018: 8 Vector__XXX

BO_ 1553 CSDO_017: 8 Vector__XXX

BO_ 1552 CSDO_016: 8 Vector__XXX

BO_ 1551 CSDO_015: 8 Vector__XXX

BO_ 1550 CSDO_014: 8 Vector__XXX

BO_ 1549 CSDO_013: 8 Vector__XXX

BO_ 1548 CSDO_012: 8 Vector__XXX

BO_ 1547 CSDO_011: 8 Vector__XXX

BO_ 1546 CSDO_010: 8 Vector__XXX

BO_ 1545 CSDO_009: 8 Vector__XXX

BO_ 1544 CSDO_008: 8 Vector__XXX

BO_ 1543 CSDO_007: 8 Vector__XXX

BO_ 1542 CSDO_006: 8 Vector__XXX

BO_ 1541 CSDO_005: 8 Vector__XXX

BO_ 1540 CSDO_004: 8 Vector__XXX

BO_ 1539 CSDO_003: 8 Vector__XXX

BO_ 1538 CSDO_002: 8 Vector__XXX

BO_ 1537 CSDO_001: 8 Vector__XXX

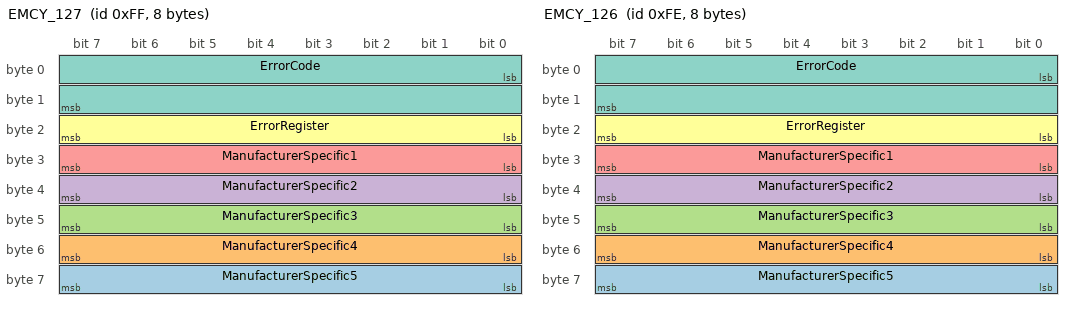
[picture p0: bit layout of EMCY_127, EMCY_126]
BO_ 255 EMCY_127: 8 Vector__XXX
 SG_ ManufacturerSpecific5 : 56|8@1+ (1,0) [0|0] "" Vector__XXX
 SG_ ManufacturerSpecific4 : 48|8@1+ (1,0) [0|0] "" Vector__XXX
 SG_ ManufacturerSpecific3 : 40|8@1+ (1,0) [0|0] "" Vector__XXX
 SG_ ManufacturerSpecific2 : 32|8@1+ (1,0) [0|0] "" Vector__XXX
 SG_ ManufacturerSpecific1 : 24|8@1+ (1,0) [0|0] "" Vector__XXX
 SG_ ErrorRegister : 16|8@1+ (1,0) [0|0] "" Vector__XXX
 SG_ ErrorCode : 0|16@1+ (1,0) [0|0] "" Vector__XXX

BO_ 254 EMCY_126: 8 Vector__XXX
 SG_ ManufacturerSpecific5 : 56|8@1+ (1,0) [0|0] "" Vector__XXX
 SG_ ManufacturerSpecific4 : 48|8@1+ (1,0) [0|0] "" Vector__XXX
 SG_ ManufacturerSpecific3 : 40|8@1+ (1,0) [0|0] "" Vector__XXX
 SG_ ManufacturerSpecific2 : 32|8@1+ (1,0) [0|0] "" Vector__XXX
 SG_ ManufacturerSpecific1 : 24|8@1+ (1,0) [0|0] "" Vector__XXX
 SG_ ErrorRegister : 16|8@1+ (1,0) [0|0] "" Vector__XXX
 SG_ ErrorCode : 0|16@1+ (1,0) [0|0] "" Vector__XXX

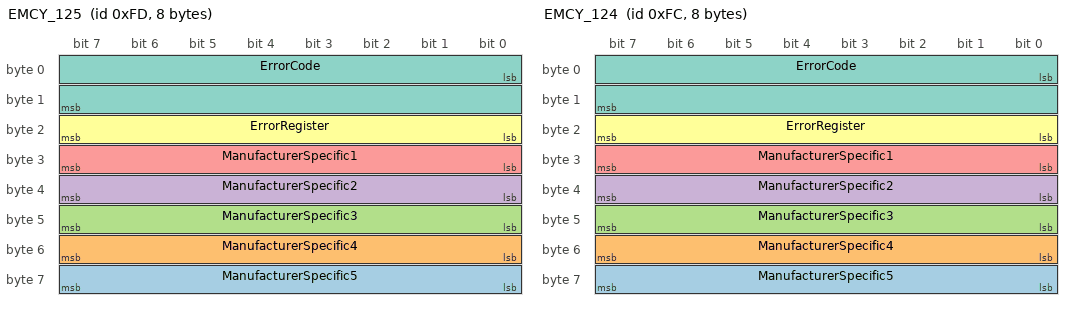
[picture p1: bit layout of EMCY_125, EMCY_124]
BO_ 253 EMCY_125: 8 Vector__XXX
 SG_ ManufacturerSpecific5 : 56|8@1+ (1,0) [0|0] "" Vector__XXX
 SG_ ManufacturerSpecific4 : 48|8@1+ (1,0) [0|0] "" Vector__XXX
 SG_ ManufacturerSpecific3 : 40|8@1+ (1,0) [0|0] "" Vector__XXX
 SG_ ManufacturerSpecific2 : 32|8@1+ (1,0) [0|0] "" Vector__XXX
 SG_ ManufacturerSpecific1 : 24|8@1+ (1,0) [0|0] "" Vector__XXX
 SG_ ErrorRegister : 16|8@1+ (1,0) [0|0] "" Vector__XXX
 SG_ ErrorCode : 0|16@1+ (1,0) [0|0] "" Vector__XXX

BO_ 252 EMCY_124: 8 Vector__XXX
 SG_ ManufacturerSpecific5 : 56|8@1+ (1,0) [0|0] "" Vector__XXX
 SG_ ManufacturerSpecific4 : 48|8@1+ (1,0) [0|0] "" Vector__XXX
 SG_ ManufacturerSpecific3 : 40|8@1+ (1,0) [0|0] "" Vector__XXX
 SG_ ManufacturerSpecific2 : 32|8@1+ (1,0) [0|0] "" Vector__XXX
 SG_ ManufacturerSpecific1 : 24|8@1+ (1,0) [0|0] "" Vector__XXX
 SG_ ErrorRegister : 16|8@1+ (1,0) [0|0] "" Vector__XXX
 SG_ ErrorCode : 0|16@1+ (1,0) [0|0] "" Vector__XXX

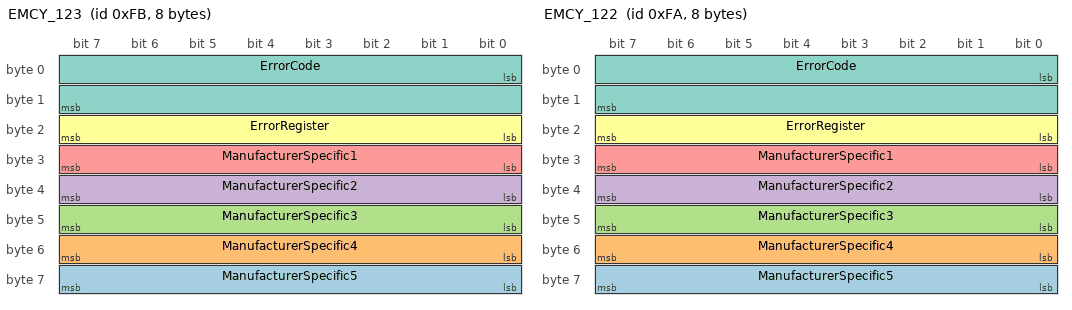
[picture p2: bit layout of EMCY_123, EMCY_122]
BO_ 251 EMCY_123: 8 Vector__XXX
 SG_ ManufacturerSpecific5 : 56|8@1+ (1,0) [0|0] "" Vector__XXX
 SG_ ManufacturerSpecific4 : 48|8@1+ (1,0) [0|0] "" Vector__XXX
 SG_ ManufacturerSpecific3 : 40|8@1+ (1,0) [0|0] "" Vector__XXX
 SG_ ManufacturerSpecific2 : 32|8@1+ (1,0) [0|0] "" Vector__XXX
 SG_ ManufacturerSpecific1 : 24|8@1+ (1,0) [0|0] "" Vector__XXX
 SG_ ErrorRegister : 16|8@1+ (1,0) [0|0] "" Vector__XXX
 SG_ ErrorCode : 0|16@1+ (1,0) [0|0] "" Vector__XXX

BO_ 250 EMCY_122: 8 Vector__XXX
 SG_ ManufacturerSpecific5 : 56|8@1+ (1,0) [0|0] "" Vector__XXX
 SG_ ManufacturerSpecific4 : 48|8@1+ (1,0) [0|0] "" Vector__XXX
 SG_ ManufacturerSpecific3 : 40|8@1+ (1,0) [0|0] "" Vector__XXX
 SG_ ManufacturerSpecific2 : 32|8@1+ (1,0) [0|0] "" Vector__XXX
 SG_ ManufacturerSpecific1 : 24|8@1+ (1,0) [0|0] "" Vector__XXX
 SG_ ErrorRegister : 16|8@1+ (1,0) [0|0] "" Vector__XXX
 SG_ ErrorCode : 0|16@1+ (1,0) [0|0] "" Vector__XXX

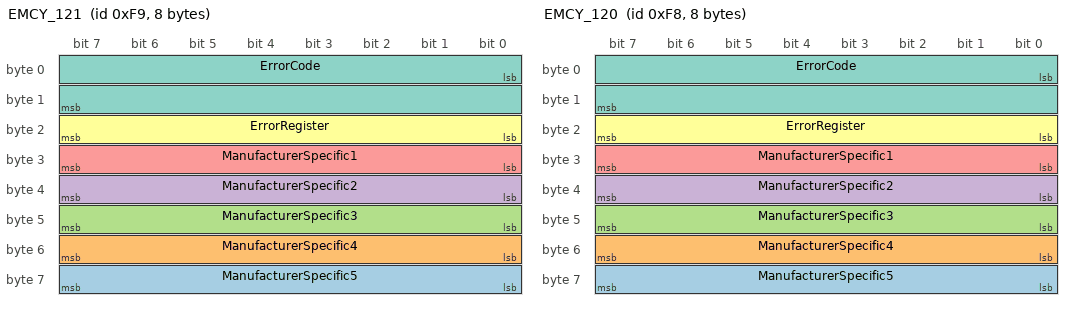
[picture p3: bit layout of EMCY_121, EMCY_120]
BO_ 249 EMCY_121: 8 Vector__XXX
 SG_ ManufacturerSpecific5 : 56|8@1+ (1,0) [0|0] "" Vector__XXX
 SG_ ManufacturerSpecific4 : 48|8@1+ (1,0) [0|0] "" Vector__XXX
 SG_ ManufacturerSpecific3 : 40|8@1+ (1,0) [0|0] "" Vector__XXX
 SG_ ManufacturerSpecific2 : 32|8@1+ (1,0) [0|0] "" Vector__XXX
 SG_ ManufacturerSpecific1 : 24|8@1+ (1,0) [0|0] "" Vector__XXX
 SG_ ErrorRegister : 16|8@1+ (1,0) [0|0] "" Vector__XXX
 SG_ ErrorCode : 0|16@1+ (1,0) [0|0] "" Vector__XXX

BO_ 248 EMCY_120: 8 Vector__XXX
 SG_ ManufacturerSpecific5 : 56|8@1+ (1,0) [0|0] "" Vector__XXX
 SG_ ManufacturerSpecific4 : 48|8@1+ (1,0) [0|0] "" Vector__XXX
 SG_ ManufacturerSpecific3 : 40|8@1+ (1,0) [0|0] "" Vector__XXX
 SG_ ManufacturerSpecific2 : 32|8@1+ (1,0) [0|0] "" Vector__XXX
 SG_ ManufacturerSpecific1 : 24|8@1+ (1,0) [0|0] "" Vector__XXX
 SG_ ErrorRegister : 16|8@1+ (1,0) [0|0] "" Vector__XXX
 SG_ ErrorCode : 0|16@1+ (1,0) [0|0] "" Vector__XXX

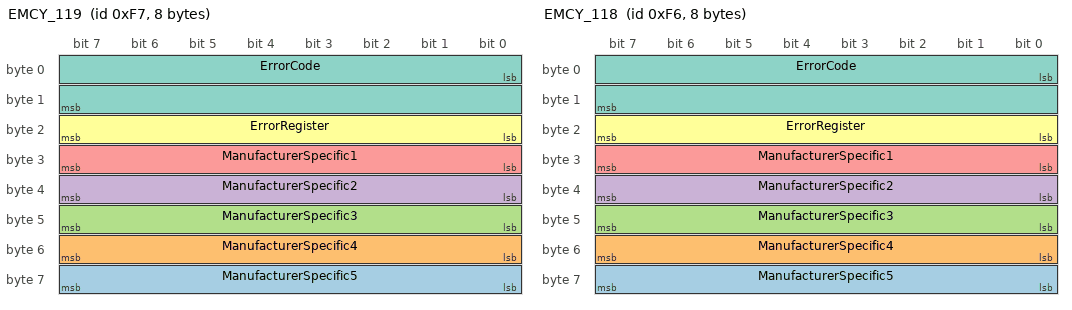
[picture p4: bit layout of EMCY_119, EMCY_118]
BO_ 247 EMCY_119: 8 Vector__XXX
 SG_ ManufacturerSpecific5 : 56|8@1+ (1,0) [0|0] "" Vector__XXX
 SG_ ManufacturerSpecific4 : 48|8@1+ (1,0) [0|0] "" Vector__XXX
 SG_ ManufacturerSpecific3 : 40|8@1+ (1,0) [0|0] "" Vector__XXX
 SG_ ManufacturerSpecific2 : 32|8@1+ (1,0) [0|0] "" Vector__XXX
 SG_ ManufacturerSpecific1 : 24|8@1+ (1,0) [0|0] "" Vector__XXX
 SG_ ErrorRegister : 16|8@1+ (1,0) [0|0] "" Vector__XXX
 SG_ ErrorCode : 0|16@1+ (1,0) [0|0] "" Vector__XXX

BO_ 246 EMCY_118: 8 Vector__XXX
 SG_ ManufacturerSpecific5 : 56|8@1+ (1,0) [0|0] "" Vector__XXX
 SG_ ManufacturerSpecific4 : 48|8@1+ (1,0) [0|0] "" Vector__XXX
 SG_ ManufacturerSpecific3 : 40|8@1+ (1,0) [0|0] "" Vector__XXX
 SG_ ManufacturerSpecific2 : 32|8@1+ (1,0) [0|0] "" Vector__XXX
 SG_ ManufacturerSpecific1 : 24|8@1+ (1,0) [0|0] "" Vector__XXX
 SG_ ErrorRegister : 16|8@1+ (1,0) [0|0] "" Vector__XXX
 SG_ ErrorCode : 0|16@1+ (1,0) [0|0] "" Vector__XXX

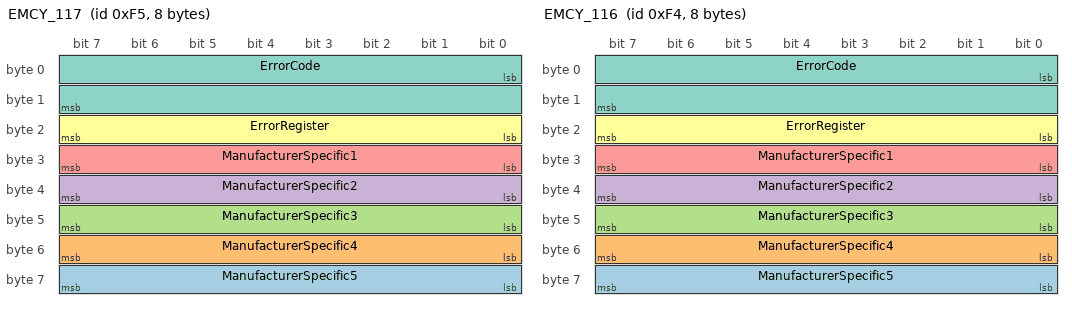
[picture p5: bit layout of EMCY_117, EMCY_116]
BO_ 245 EMCY_117: 8 Vector__XXX
 SG_ ManufacturerSpecific5 : 56|8@1+ (1,0) [0|0] "" Vector__XXX
 SG_ ManufacturerSpecific4 : 48|8@1+ (1,0) [0|0] "" Vector__XXX
 SG_ ManufacturerSpecific3 : 40|8@1+ (1,0) [0|0] "" Vector__XXX
 SG_ ManufacturerSpecific2 : 32|8@1+ (1,0) [0|0] "" Vector__XXX
 SG_ ManufacturerSpecific1 : 24|8@1+ (1,0) [0|0] "" Vector__XXX
 SG_ ErrorRegister : 16|8@1+ (1,0) [0|0] "" Vector__XXX
 SG_ ErrorCode : 0|16@1+ (1,0) [0|0] "" Vector__XXX

BO_ 244 EMCY_116: 8 Vector__XXX
 SG_ ManufacturerSpecific5 : 56|8@1+ (1,0) [0|0] "" Vector__XXX
 SG_ ManufacturerSpecific4 : 48|8@1+ (1,0) [0|0] "" Vector__XXX
 SG_ ManufacturerSpecific3 : 40|8@1+ (1,0) [0|0] "" Vector__XXX
 SG_ ManufacturerSpecific2 : 32|8@1+ (1,0) [0|0] "" Vector__XXX
 SG_ ManufacturerSpecific1 : 24|8@1+ (1,0) [0|0] "" Vector__XXX
 SG_ ErrorRegister : 16|8@1+ (1,0) [0|0] "" Vector__XXX
 SG_ ErrorCode : 0|16@1+ (1,0) [0|0] "" Vector__XXX

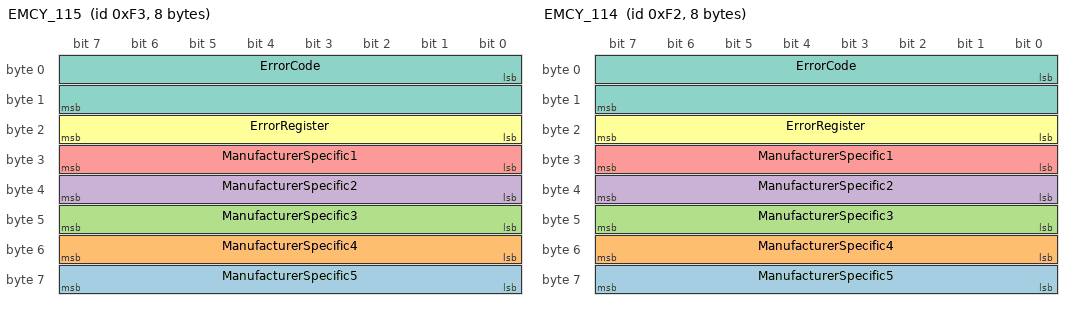
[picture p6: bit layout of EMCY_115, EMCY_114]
BO_ 243 EMCY_115: 8 Vector__XXX
 SG_ ManufacturerSpecific5 : 56|8@1+ (1,0) [0|0] "" Vector__XXX
 SG_ ManufacturerSpecific4 : 48|8@1+ (1,0) [0|0] "" Vector__XXX
 SG_ ManufacturerSpecific3 : 40|8@1+ (1,0) [0|0] "" Vector__XXX
 SG_ ManufacturerSpecific2 : 32|8@1+ (1,0) [0|0] "" Vector__XXX
 SG_ ManufacturerSpecific1 : 24|8@1+ (1,0) [0|0] "" Vector__XXX
 SG_ ErrorRegister : 16|8@1+ (1,0) [0|0] "" Vector__XXX
 SG_ ErrorCode : 0|16@1+ (1,0) [0|0] "" Vector__XXX

BO_ 242 EMCY_114: 8 Vector__XXX
 SG_ ManufacturerSpecific5 : 56|8@1+ (1,0) [0|0] "" Vector__XXX
 SG_ ManufacturerSpecific4 : 48|8@1+ (1,0) [0|0] "" Vector__XXX
 SG_ ManufacturerSpecific3 : 40|8@1+ (1,0) [0|0] "" Vector__XXX
 SG_ ManufacturerSpecific2 : 32|8@1+ (1,0) [0|0] "" Vector__XXX
 SG_ ManufacturerSpecific1 : 24|8@1+ (1,0) [0|0] "" Vector__XXX
 SG_ ErrorRegister : 16|8@1+ (1,0) [0|0] "" Vector__XXX
 SG_ ErrorCode : 0|16@1+ (1,0) [0|0] "" Vector__XXX

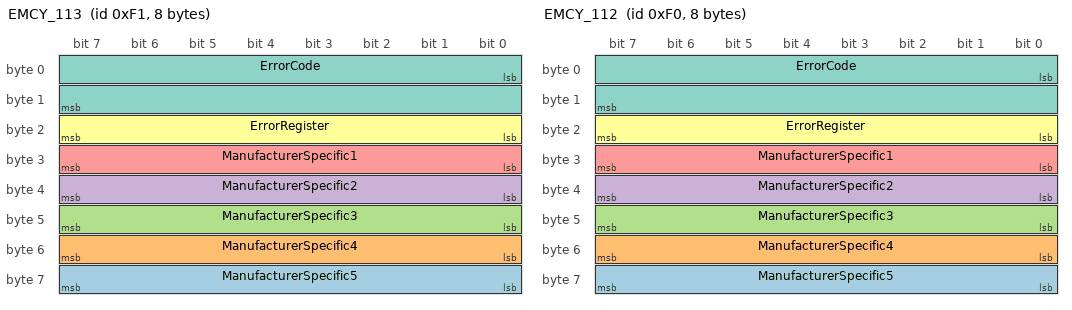
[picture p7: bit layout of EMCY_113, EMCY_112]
BO_ 241 EMCY_113: 8 Vector__XXX
 SG_ ManufacturerSpecific5 : 56|8@1+ (1,0) [0|0] "" Vector__XXX
 SG_ ManufacturerSpecific4 : 48|8@1+ (1,0) [0|0] "" Vector__XXX
 SG_ ManufacturerSpecific3 : 40|8@1+ (1,0) [0|0] "" Vector__XXX
 SG_ ManufacturerSpecific2 : 32|8@1+ (1,0) [0|0] "" Vector__XXX
 SG_ ManufacturerSpecific1 : 24|8@1+ (1,0) [0|0] "" Vector__XXX
 SG_ ErrorRegister : 16|8@1+ (1,0) [0|0] "" Vector__XXX
 SG_ ErrorCode : 0|16@1+ (1,0) [0|0] "" Vector__XXX

BO_ 240 EMCY_112: 8 Vector__XXX
 SG_ ManufacturerSpecific5 : 56|8@1+ (1,0) [0|0] "" Vector__XXX
 SG_ ManufacturerSpecific4 : 48|8@1+ (1,0) [0|0] "" Vector__XXX
 SG_ ManufacturerSpecific3 : 40|8@1+ (1,0) [0|0] "" Vector__XXX
 SG_ ManufacturerSpecific2 : 32|8@1+ (1,0) [0|0] "" Vector__XXX
 SG_ ManufacturerSpecific1 : 24|8@1+ (1,0) [0|0] "" Vector__XXX
 SG_ ErrorRegister : 16|8@1+ (1,0) [0|0] "" Vector__XXX
 SG_ ErrorCode : 0|16@1+ (1,0) [0|0] "" Vector__XXX

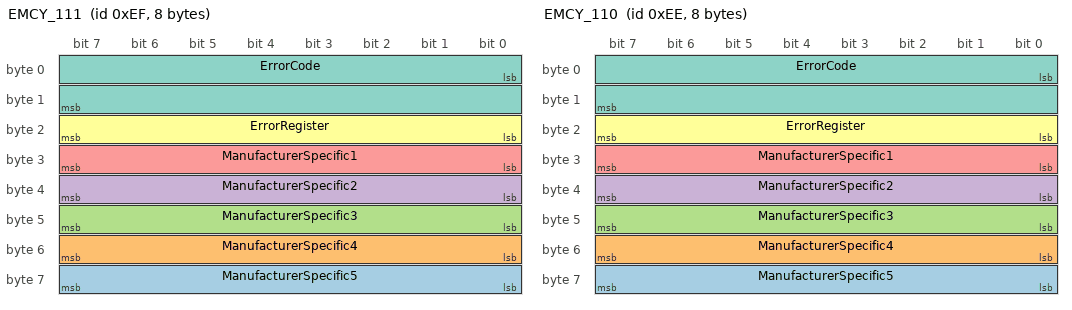
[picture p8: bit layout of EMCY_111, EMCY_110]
BO_ 239 EMCY_111: 8 Vector__XXX
 SG_ ManufacturerSpecific5 : 56|8@1+ (1,0) [0|0] "" Vector__XXX
 SG_ ManufacturerSpecific4 : 48|8@1+ (1,0) [0|0] "" Vector__XXX
 SG_ ManufacturerSpecific3 : 40|8@1+ (1,0) [0|0] "" Vector__XXX
 SG_ ManufacturerSpecific2 : 32|8@1+ (1,0) [0|0] "" Vector__XXX
 SG_ ManufacturerSpecific1 : 24|8@1+ (1,0) [0|0] "" Vector__XXX
 SG_ ErrorRegister : 16|8@1+ (1,0) [0|0] "" Vector__XXX
 SG_ ErrorCode : 0|16@1+ (1,0) [0|0] "" Vector__XXX

BO_ 238 EMCY_110: 8 Vector__XXX
 SG_ ManufacturerSpecific5 : 56|8@1+ (1,0) [0|0] "" Vector__XXX
 SG_ ManufacturerSpecific4 : 48|8@1+ (1,0) [0|0] "" Vector__XXX
 SG_ ManufacturerSpecific3 : 40|8@1+ (1,0) [0|0] "" Vector__XXX
 SG_ ManufacturerSpecific2 : 32|8@1+ (1,0) [0|0] "" Vector__XXX
 SG_ ManufacturerSpecific1 : 24|8@1+ (1,0) [0|0] "" Vector__XXX
 SG_ ErrorRegister : 16|8@1+ (1,0) [0|0] "" Vector__XXX
 SG_ ErrorCode : 0|16@1+ (1,0) [0|0] "" Vector__XXX

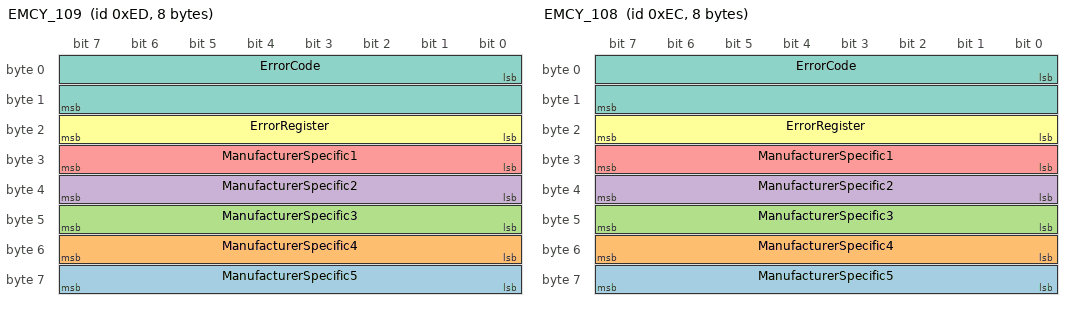
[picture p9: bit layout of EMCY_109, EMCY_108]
BO_ 237 EMCY_109: 8 Vector__XXX
 SG_ ManufacturerSpecific5 : 56|8@1+ (1,0) [0|0] "" Vector__XXX
 SG_ ManufacturerSpecific4 : 48|8@1+ (1,0) [0|0] "" Vector__XXX
 SG_ ManufacturerSpecific3 : 40|8@1+ (1,0) [0|0] "" Vector__XXX
 SG_ ManufacturerSpecific2 : 32|8@1+ (1,0) [0|0] "" Vector__XXX
 SG_ ManufacturerSpecific1 : 24|8@1+ (1,0) [0|0] "" Vector__XXX
 SG_ ErrorRegister : 16|8@1+ (1,0) [0|0] "" Vector__XXX
 SG_ ErrorCode : 0|16@1+ (1,0) [0|0] "" Vector__XXX

BO_ 236 EMCY_108: 8 Vector__XXX
 SG_ ManufacturerSpecific5 : 56|8@1+ (1,0) [0|0] "" Vector__XXX
 SG_ ManufacturerSpecific4 : 48|8@1+ (1,0) [0|0] "" Vector__XXX
 SG_ ManufacturerSpecific3 : 40|8@1+ (1,0) [0|0] "" Vector__XXX
 SG_ ManufacturerSpecific2 : 32|8@1+ (1,0) [0|0] "" Vector__XXX
 SG_ ManufacturerSpecific1 : 24|8@1+ (1,0) [0|0] "" Vector__XXX
 SG_ ErrorRegister : 16|8@1+ (1,0) [0|0] "" Vector__XXX
 SG_ ErrorCode : 0|16@1+ (1,0) [0|0] "" Vector__XXX

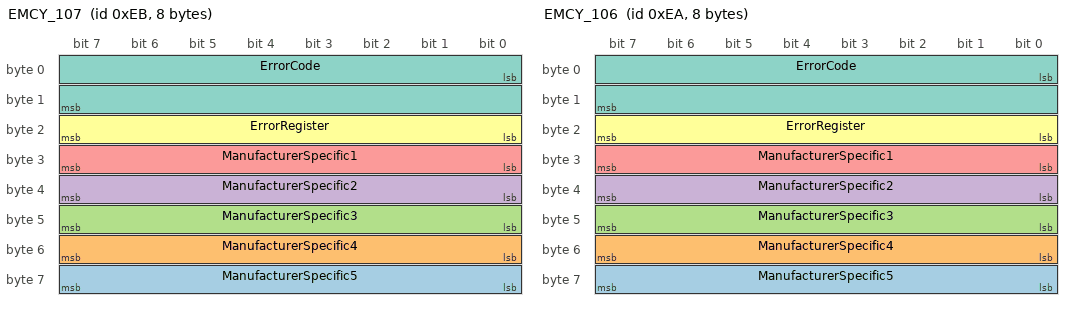
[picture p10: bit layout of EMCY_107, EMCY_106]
BO_ 235 EMCY_107: 8 Vector__XXX
 SG_ ManufacturerSpecific5 : 56|8@1+ (1,0) [0|0] "" Vector__XXX
 SG_ ManufacturerSpecific4 : 48|8@1+ (1,0) [0|0] "" Vector__XXX
 SG_ ManufacturerSpecific3 : 40|8@1+ (1,0) [0|0] "" Vector__XXX
 SG_ ManufacturerSpecific2 : 32|8@1+ (1,0) [0|0] "" Vector__XXX
 SG_ ManufacturerSpecific1 : 24|8@1+ (1,0) [0|0] "" Vector__XXX
 SG_ ErrorRegister : 16|8@1+ (1,0) [0|0] "" Vector__XXX
 SG_ ErrorCode : 0|16@1+ (1,0) [0|0] "" Vector__XXX

BO_ 234 EMCY_106: 8 Vector__XXX
 SG_ ManufacturerSpecific5 : 56|8@1+ (1,0) [0|0] "" Vector__XXX
 SG_ ManufacturerSpecific4 : 48|8@1+ (1,0) [0|0] "" Vector__XXX
 SG_ ManufacturerSpecific3 : 40|8@1+ (1,0) [0|0] "" Vector__XXX
 SG_ ManufacturerSpecific2 : 32|8@1+ (1,0) [0|0] "" Vector__XXX
 SG_ ManufacturerSpecific1 : 24|8@1+ (1,0) [0|0] "" Vector__XXX
 SG_ ErrorRegister : 16|8@1+ (1,0) [0|0] "" Vector__XXX
 SG_ ErrorCode : 0|16@1+ (1,0) [0|0] "" Vector__XXX

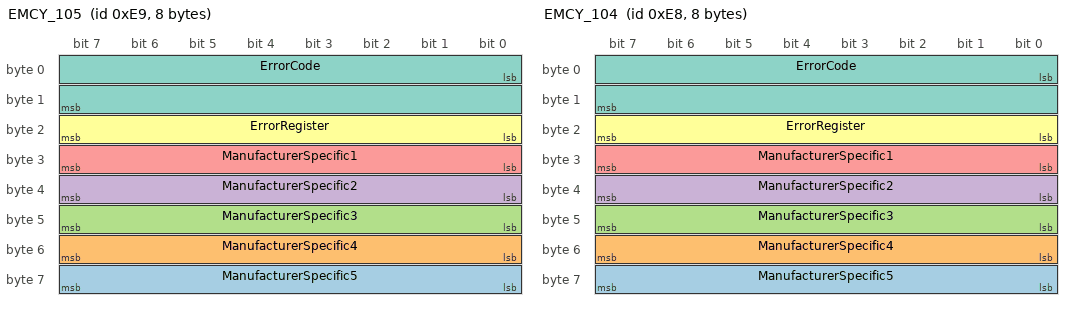
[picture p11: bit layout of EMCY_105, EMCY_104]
BO_ 233 EMCY_105: 8 Vector__XXX
 SG_ ManufacturerSpecific5 : 56|8@1+ (1,0) [0|0] "" Vector__XXX
 SG_ ManufacturerSpecific4 : 48|8@1+ (1,0) [0|0] "" Vector__XXX
 SG_ ManufacturerSpecific3 : 40|8@1+ (1,0) [0|0] "" Vector__XXX
 SG_ ManufacturerSpecific2 : 32|8@1+ (1,0) [0|0] "" Vector__XXX
 SG_ ManufacturerSpecific1 : 24|8@1+ (1,0) [0|0] "" Vector__XXX
 SG_ ErrorRegister : 16|8@1+ (1,0) [0|0] "" Vector__XXX
 SG_ ErrorCode : 0|16@1+ (1,0) [0|0] "" Vector__XXX

BO_ 232 EMCY_104: 8 Vector__XXX
 SG_ ManufacturerSpecific5 : 56|8@1+ (1,0) [0|0] "" Vector__XXX
 SG_ ManufacturerSpecific4 : 48|8@1+ (1,0) [0|0] "" Vector__XXX
 SG_ ManufacturerSpecific3 : 40|8@1+ (1,0) [0|0] "" Vector__XXX
 SG_ ManufacturerSpecific2 : 32|8@1+ (1,0) [0|0] "" Vector__XXX
 SG_ ManufacturerSpecific1 : 24|8@1+ (1,0) [0|0] "" Vector__XXX
 SG_ ErrorRegister : 16|8@1+ (1,0) [0|0] "" Vector__XXX
 SG_ ErrorCode : 0|16@1+ (1,0) [0|0] "" Vector__XXX

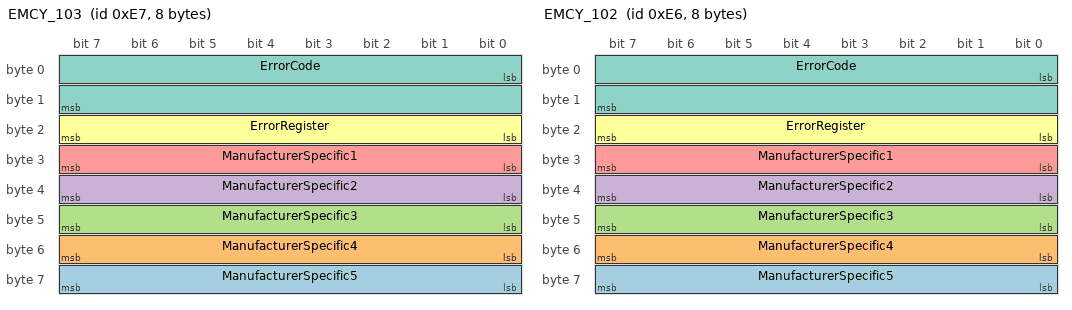
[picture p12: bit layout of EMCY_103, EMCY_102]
BO_ 231 EMCY_103: 8 Vector__XXX
 SG_ ManufacturerSpecific5 : 56|8@1+ (1,0) [0|0] "" Vector__XXX
 SG_ ManufacturerSpecific4 : 48|8@1+ (1,0) [0|0] "" Vector__XXX
 SG_ ManufacturerSpecific3 : 40|8@1+ (1,0) [0|0] "" Vector__XXX
 SG_ ManufacturerSpecific2 : 32|8@1+ (1,0) [0|0] "" Vector__XXX
 SG_ ManufacturerSpecific1 : 24|8@1+ (1,0) [0|0] "" Vector__XXX
 SG_ ErrorRegister : 16|8@1+ (1,0) [0|0] "" Vector__XXX
 SG_ ErrorCode : 0|16@1+ (1,0) [0|0] "" Vector__XXX

BO_ 230 EMCY_102: 8 Vector__XXX
 SG_ ManufacturerSpecific5 : 56|8@1+ (1,0) [0|0] "" Vector__XXX
 SG_ ManufacturerSpecific4 : 48|8@1+ (1,0) [0|0] "" Vector__XXX
 SG_ ManufacturerSpecific3 : 40|8@1+ (1,0) [0|0] "" Vector__XXX
 SG_ ManufacturerSpecific2 : 32|8@1+ (1,0) [0|0] "" Vector__XXX
 SG_ ManufacturerSpecific1 : 24|8@1+ (1,0) [0|0] "" Vector__XXX
 SG_ ErrorRegister : 16|8@1+ (1,0) [0|0] "" Vector__XXX
 SG_ ErrorCode : 0|16@1+ (1,0) [0|0] "" Vector__XXX

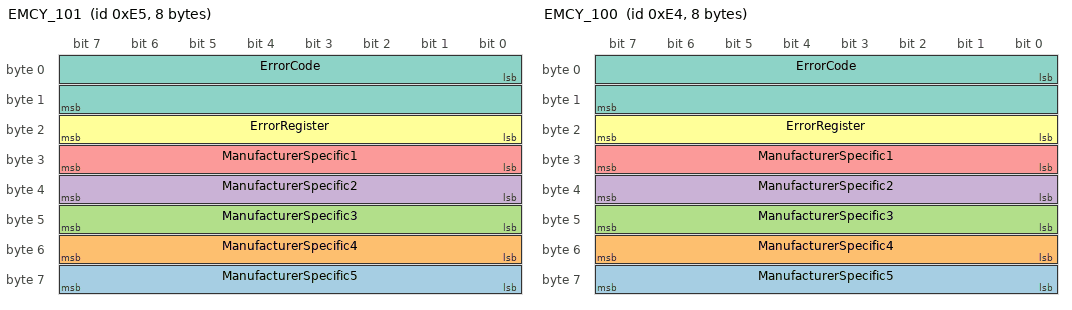
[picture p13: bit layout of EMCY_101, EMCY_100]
BO_ 229 EMCY_101: 8 Vector__XXX
 SG_ ManufacturerSpecific5 : 56|8@1+ (1,0) [0|0] "" Vector__XXX
 SG_ ManufacturerSpecific4 : 48|8@1+ (1,0) [0|0] "" Vector__XXX
 SG_ ManufacturerSpecific3 : 40|8@1+ (1,0) [0|0] "" Vector__XXX
 SG_ ManufacturerSpecific2 : 32|8@1+ (1,0) [0|0] "" Vector__XXX
 SG_ ManufacturerSpecific1 : 24|8@1+ (1,0) [0|0] "" Vector__XXX
 SG_ ErrorRegister : 16|8@1+ (1,0) [0|0] "" Vector__XXX
 SG_ ErrorCode : 0|16@1+ (1,0) [0|0] "" Vector__XXX

BO_ 228 EMCY_100: 8 Vector__XXX
 SG_ ManufacturerSpecific5 : 56|8@1+ (1,0) [0|0] "" Vector__XXX
 SG_ ManufacturerSpecific4 : 48|8@1+ (1,0) [0|0] "" Vector__XXX
 SG_ ManufacturerSpecific3 : 40|8@1+ (1,0) [0|0] "" Vector__XXX
 SG_ ManufacturerSpecific2 : 32|8@1+ (1,0) [0|0] "" Vector__XXX
 SG_ ManufacturerSpecific1 : 24|8@1+ (1,0) [0|0] "" Vector__XXX
 SG_ ErrorRegister : 16|8@1+ (1,0) [0|0] "" Vector__XXX
 SG_ ErrorCode : 0|16@1+ (1,0) [0|0] "" Vector__XXX

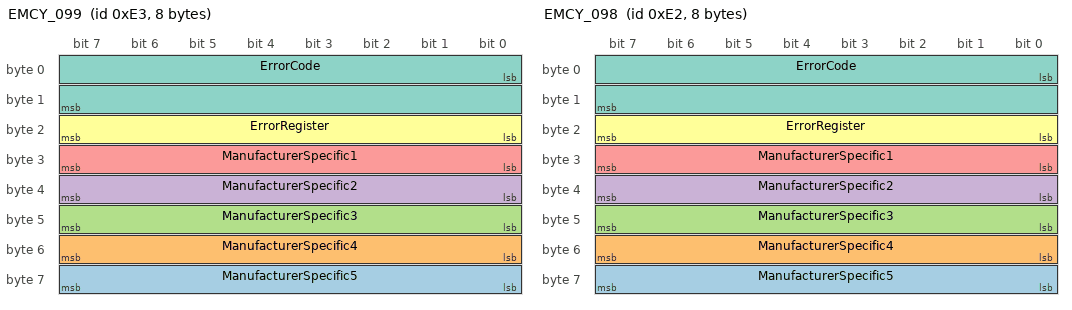
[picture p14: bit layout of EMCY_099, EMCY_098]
BO_ 227 EMCY_099: 8 Vector__XXX
 SG_ ManufacturerSpecific5 : 56|8@1+ (1,0) [0|0] "" Vector__XXX
 SG_ ManufacturerSpecific4 : 48|8@1+ (1,0) [0|0] "" Vector__XXX
 SG_ ManufacturerSpecific3 : 40|8@1+ (1,0) [0|0] "" Vector__XXX
 SG_ ManufacturerSpecific2 : 32|8@1+ (1,0) [0|0] "" Vector__XXX
 SG_ ManufacturerSpecific1 : 24|8@1+ (1,0) [0|0] "" Vector__XXX
 SG_ ErrorRegister : 16|8@1+ (1,0) [0|0] "" Vector__XXX
 SG_ ErrorCode : 0|16@1+ (1,0) [0|0] "" Vector__XXX

BO_ 226 EMCY_098: 8 Vector__XXX
 SG_ ManufacturerSpecific5 : 56|8@1+ (1,0) [0|0] "" Vector__XXX
 SG_ ManufacturerSpecific4 : 48|8@1+ (1,0) [0|0] "" Vector__XXX
 SG_ ManufacturerSpecific3 : 40|8@1+ (1,0) [0|0] "" Vector__XXX
 SG_ ManufacturerSpecific2 : 32|8@1+ (1,0) [0|0] "" Vector__XXX
 SG_ ManufacturerSpecific1 : 24|8@1+ (1,0) [0|0] "" Vector__XXX
 SG_ ErrorRegister : 16|8@1+ (1,0) [0|0] "" Vector__XXX
 SG_ ErrorCode : 0|16@1+ (1,0) [0|0] "" Vector__XXX

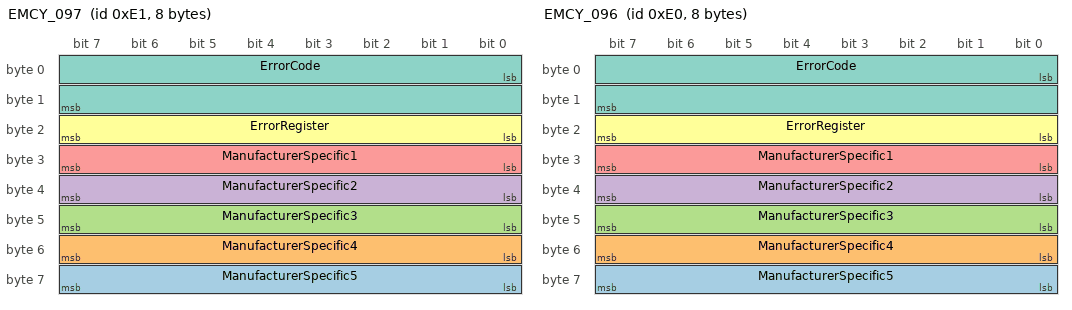
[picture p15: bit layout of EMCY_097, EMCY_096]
BO_ 225 EMCY_097: 8 Vector__XXX
 SG_ ManufacturerSpecific5 : 56|8@1+ (1,0) [0|0] "" Vector__XXX
 SG_ ManufacturerSpecific4 : 48|8@1+ (1,0) [0|0] "" Vector__XXX
 SG_ ManufacturerSpecific3 : 40|8@1+ (1,0) [0|0] "" Vector__XXX
 SG_ ManufacturerSpecific2 : 32|8@1+ (1,0) [0|0] "" Vector__XXX
 SG_ ManufacturerSpecific1 : 24|8@1+ (1,0) [0|0] "" Vector__XXX
 SG_ ErrorRegister : 16|8@1+ (1,0) [0|0] "" Vector__XXX
 SG_ ErrorCode : 0|16@1+ (1,0) [0|0] "" Vector__XXX

BO_ 224 EMCY_096: 8 Vector__XXX
 SG_ ManufacturerSpecific5 : 56|8@1+ (1,0) [0|0] "" Vector__XXX
 SG_ ManufacturerSpecific4 : 48|8@1+ (1,0) [0|0] "" Vector__XXX
 SG_ ManufacturerSpecific3 : 40|8@1+ (1,0) [0|0] "" Vector__XXX
 SG_ ManufacturerSpecific2 : 32|8@1+ (1,0) [0|0] "" Vector__XXX
 SG_ ManufacturerSpecific1 : 24|8@1+ (1,0) [0|0] "" Vector__XXX
 SG_ ErrorRegister : 16|8@1+ (1,0) [0|0] "" Vector__XXX
 SG_ ErrorCode : 0|16@1+ (1,0) [0|0] "" Vector__XXX

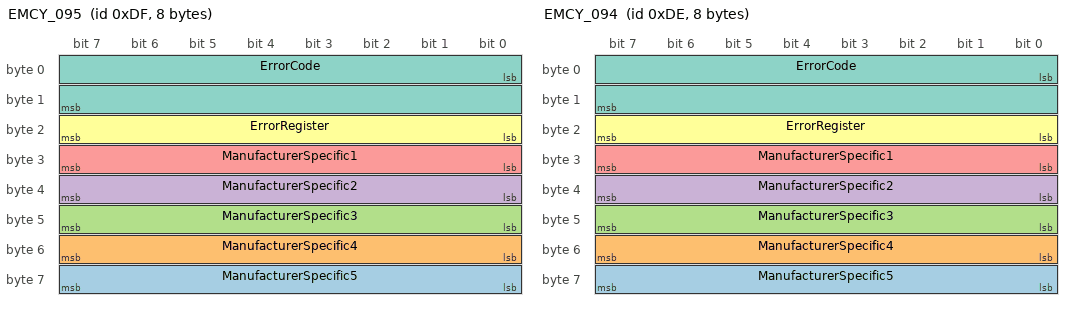
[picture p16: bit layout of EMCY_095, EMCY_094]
BO_ 223 EMCY_095: 8 Vector__XXX
 SG_ ManufacturerSpecific5 : 56|8@1+ (1,0) [0|0] "" Vector__XXX
 SG_ ManufacturerSpecific4 : 48|8@1+ (1,0) [0|0] "" Vector__XXX
 SG_ ManufacturerSpecific3 : 40|8@1+ (1,0) [0|0] "" Vector__XXX
 SG_ ManufacturerSpecific2 : 32|8@1+ (1,0) [0|0] "" Vector__XXX
 SG_ ManufacturerSpecific1 : 24|8@1+ (1,0) [0|0] "" Vector__XXX
 SG_ ErrorRegister : 16|8@1+ (1,0) [0|0] "" Vector__XXX
 SG_ ErrorCode : 0|16@1+ (1,0) [0|0] "" Vector__XXX

BO_ 222 EMCY_094: 8 Vector__XXX
 SG_ ManufacturerSpecific5 : 56|8@1+ (1,0) [0|0] "" Vector__XXX
 SG_ ManufacturerSpecific4 : 48|8@1+ (1,0) [0|0] "" Vector__XXX
 SG_ ManufacturerSpecific3 : 40|8@1+ (1,0) [0|0] "" Vector__XXX
 SG_ ManufacturerSpecific2 : 32|8@1+ (1,0) [0|0] "" Vector__XXX
 SG_ ManufacturerSpecific1 : 24|8@1+ (1,0) [0|0] "" Vector__XXX
 SG_ ErrorRegister : 16|8@1+ (1,0) [0|0] "" Vector__XXX
 SG_ ErrorCode : 0|16@1+ (1,0) [0|0] "" Vector__XXX

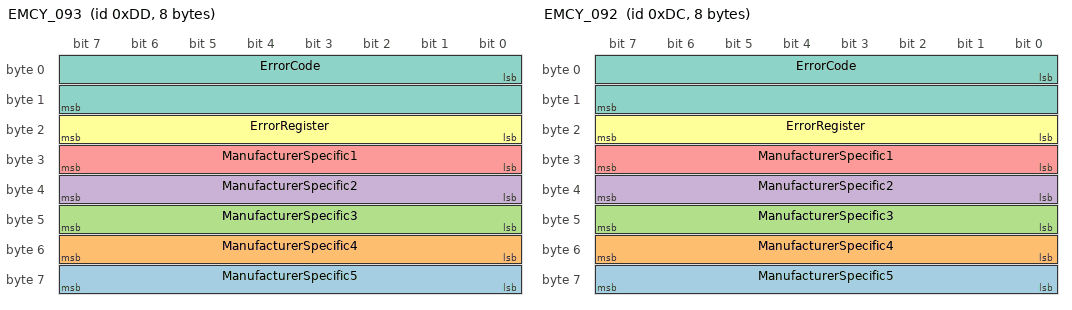
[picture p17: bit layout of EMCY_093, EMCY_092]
BO_ 221 EMCY_093: 8 Vector__XXX
 SG_ ManufacturerSpecific5 : 56|8@1+ (1,0) [0|0] "" Vector__XXX
 SG_ ManufacturerSpecific4 : 48|8@1+ (1,0) [0|0] "" Vector__XXX
 SG_ ManufacturerSpecific3 : 40|8@1+ (1,0) [0|0] "" Vector__XXX
 SG_ ManufacturerSpecific2 : 32|8@1+ (1,0) [0|0] "" Vector__XXX
 SG_ ManufacturerSpecific1 : 24|8@1+ (1,0) [0|0] "" Vector__XXX
 SG_ ErrorRegister : 16|8@1+ (1,0) [0|0] "" Vector__XXX
 SG_ ErrorCode : 0|16@1+ (1,0) [0|0] "" Vector__XXX

BO_ 220 EMCY_092: 8 Vector__XXX
 SG_ ManufacturerSpecific5 : 56|8@1+ (1,0) [0|0] "" Vector__XXX
 SG_ ManufacturerSpecific4 : 48|8@1+ (1,0) [0|0] "" Vector__XXX
 SG_ ManufacturerSpecific3 : 40|8@1+ (1,0) [0|0] "" Vector__XXX
 SG_ ManufacturerSpecific2 : 32|8@1+ (1,0) [0|0] "" Vector__XXX
 SG_ ManufacturerSpecific1 : 24|8@1+ (1,0) [0|0] "" Vector__XXX
 SG_ ErrorRegister : 16|8@1+ (1,0) [0|0] "" Vector__XXX
 SG_ ErrorCode : 0|16@1+ (1,0) [0|0] "" Vector__XXX

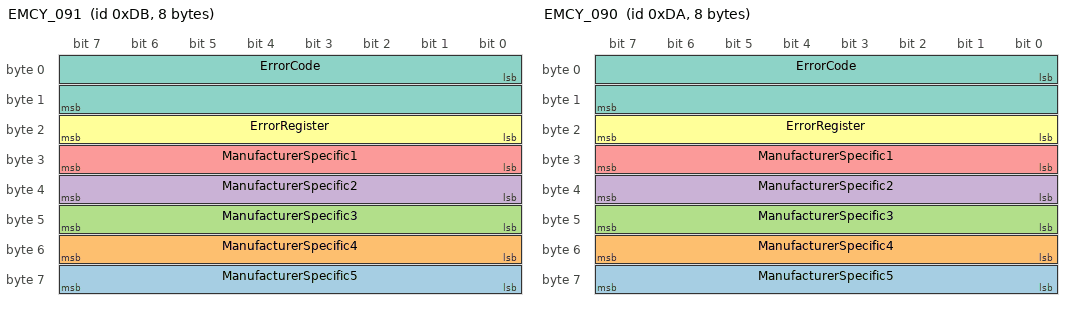
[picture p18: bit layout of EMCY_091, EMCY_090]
BO_ 219 EMCY_091: 8 Vector__XXX
 SG_ ManufacturerSpecific5 : 56|8@1+ (1,0) [0|0] "" Vector__XXX
 SG_ ManufacturerSpecific4 : 48|8@1+ (1,0) [0|0] "" Vector__XXX
 SG_ ManufacturerSpecific3 : 40|8@1+ (1,0) [0|0] "" Vector__XXX
 SG_ ManufacturerSpecific2 : 32|8@1+ (1,0) [0|0] "" Vector__XXX
 SG_ ManufacturerSpecific1 : 24|8@1+ (1,0) [0|0] "" Vector__XXX
 SG_ ErrorRegister : 16|8@1+ (1,0) [0|0] "" Vector__XXX
 SG_ ErrorCode : 0|16@1+ (1,0) [0|0] "" Vector__XXX

BO_ 218 EMCY_090: 8 Vector__XXX
 SG_ ManufacturerSpecific5 : 56|8@1+ (1,0) [0|0] "" Vector__XXX
 SG_ ManufacturerSpecific4 : 48|8@1+ (1,0) [0|0] "" Vector__XXX
 SG_ ManufacturerSpecific3 : 40|8@1+ (1,0) [0|0] "" Vector__XXX
 SG_ ManufacturerSpecific2 : 32|8@1+ (1,0) [0|0] "" Vector__XXX
 SG_ ManufacturerSpecific1 : 24|8@1+ (1,0) [0|0] "" Vector__XXX
 SG_ ErrorRegister : 16|8@1+ (1,0) [0|0] "" Vector__XXX
 SG_ ErrorCode : 0|16@1+ (1,0) [0|0] "" Vector__XXX

BO_ 217 EMCY_089: 8 Vector__XXX
 SG_ ManufacturerSpecific5 : 56|8@1+ (1,0) [0|0] "" Vector__XXX
 SG_ ManufacturerSpecific4 : 48|8@1+ (1,0) [0|0] "" Vector__XXX
 SG_ ManufacturerSpecific3 : 40|8@1+ (1,0) [0|0] "" Vector__XXX
 SG_ ManufacturerSpecific2 : 32|8@1+ (1,0) [0|0] "" Vector__XXX
 SG_ ManufacturerSpecific1 : 24|8@1+ (1,0) [0|0] "" Vector__XXX
 SG_ ErrorRegister : 16|8@1+ (1,0) [0|0] "" Vector__XXX
 SG_ ErrorCode : 0|16@1+ (1,0) [0|0] "" Vector__XXX

BO_ 216 EMCY_088: 8 Vector__XXX
 SG_ ManufacturerSpecific5 : 56|8@1+ (1,0) [0|0] "" Vector__XXX
 SG_ ManufacturerSpecific4 : 48|8@1+ (1,0) [0|0] "" Vector__XXX
 SG_ ManufacturerSpecific3 : 40|8@1+ (1,0) [0|0] "" Vector__XXX
 SG_ ManufacturerSpecific2 : 32|8@1+ (1,0) [0|0] "" Vector__XXX
 SG_ ManufacturerSpecific1 : 24|8@1+ (1,0) [0|0] "" Vector__XXX
 SG_ ErrorRegister : 16|8@1+ (1,0) [0|0] "" Vector__XXX
 SG_ ErrorCode : 0|16@1+ (1,0) [0|0] "" Vector__XXX

BO_ 215 EMCY_087: 8 Vector__XXX
 SG_ ManufacturerSpecific5 : 56|8@1+ (1,0) [0|0] "" Vector__XXX
 SG_ ManufacturerSpecific4 : 48|8@1+ (1,0) [0|0] "" Vector__XXX
 SG_ ManufacturerSpecific3 : 40|8@1+ (1,0) [0|0] "" Vector__XXX
 SG_ ManufacturerSpecific2 : 32|8@1+ (1,0) [0|0] "" Vector__XXX
 SG_ ManufacturerSpecific1 : 24|8@1+ (1,0) [0|0] "" Vector__XXX
 SG_ ErrorRegister : 16|8@1+ (1,0) [0|0] "" Vector__XXX
 SG_ ErrorCode : 0|16@1+ (1,0) [0|0] "" Vector__XXX

BO_ 214 EMCY_086: 8 Vector__XXX
 SG_ ManufacturerSpecific5 : 56|8@1+ (1,0) [0|0] "" Vector__XXX
 SG_ ManufacturerSpecific4 : 48|8@1+ (1,0) [0|0] "" Vector__XXX
 SG_ ManufacturerSpecific3 : 40|8@1+ (1,0) [0|0] "" Vector__XXX
 SG_ ManufacturerSpecific2 : 32|8@1+ (1,0) [0|0] "" Vector__XXX
 SG_ ManufacturerSpecific1 : 24|8@1+ (1,0) [0|0] "" Vector__XXX
 SG_ ErrorRegister : 16|8@1+ (1,0) [0|0] "" Vector__XXX
 SG_ ErrorCode : 0|16@1+ (1,0) [0|0] "" Vector__XXX

BO_ 213 EMCY_085: 8 Vector__XXX
 SG_ ManufacturerSpecific5 : 56|8@1+ (1,0) [0|0] "" Vector__XXX
 SG_ ManufacturerSpecific4 : 48|8@1+ (1,0) [0|0] "" Vector__XXX
 SG_ ManufacturerSpecific3 : 40|8@1+ (1,0) [0|0] "" Vector__XXX
 SG_ ManufacturerSpecific2 : 32|8@1+ (1,0) [0|0] "" Vector__XXX
 SG_ ManufacturerSpecific1 : 24|8@1+ (1,0) [0|0] "" Vector__XXX
 SG_ ErrorRegister : 16|8@1+ (1,0) [0|0] "" Vector__XXX
 SG_ ErrorCode : 0|16@1+ (1,0) [0|0] "" Vector__XXX

BO_ 212 EMCY_084: 8 Vector__XXX
 SG_ ManufacturerSpecific5 : 56|8@1+ (1,0) [0|0] "" Vector__XXX
 SG_ ManufacturerSpecific4 : 48|8@1+ (1,0) [0|0] "" Vector__XXX
 SG_ ManufacturerSpecific3 : 40|8@1+ (1,0) [0|0] "" Vector__XXX
 SG_ ManufacturerSpecific2 : 32|8@1+ (1,0) [0|0] "" Vector__XXX
 SG_ ManufacturerSpecific1 : 24|8@1+ (1,0) [0|0] "" Vector__XXX
 SG_ ErrorRegister : 16|8@1+ (1,0) [0|0] "" Vector__XXX
 SG_ ErrorCode : 0|16@1+ (1,0) [0|0] "" Vector__XXX

BO_ 211 EMCY_083: 8 Vector__XXX
 SG_ ManufacturerSpecific5 : 56|8@1+ (1,0) [0|0] "" Vector__XXX
 SG_ ManufacturerSpecific4 : 48|8@1+ (1,0) [0|0] "" Vector__XXX
 SG_ ManufacturerSpecific3 : 40|8@1+ (1,0) [0|0] "" Vector__XXX
 SG_ ManufacturerSpecific2 : 32|8@1+ (1,0) [0|0] "" Vector__XXX
 SG_ ManufacturerSpecific1 : 24|8@1+ (1,0) [0|0] "" Vector__XXX
 SG_ ErrorRegister : 16|8@1+ (1,0) [0|0] "" Vector__XXX
 SG_ ErrorCode : 0|16@1+ (1,0) [0|0] "" Vector__XXX

BO_ 210 EMCY_082: 8 Vector__XXX
 SG_ ManufacturerSpecific5 : 56|8@1+ (1,0) [0|0] "" Vector__XXX
 SG_ ManufacturerSpecific4 : 48|8@1+ (1,0) [0|0] "" Vector__XXX
 SG_ ManufacturerSpecific3 : 40|8@1+ (1,0) [0|0] "" Vector__XXX
 SG_ ManufacturerSpecific2 : 32|8@1+ (1,0) [0|0] "" Vector__XXX
 SG_ ManufacturerSpecific1 : 24|8@1+ (1,0) [0|0] "" Vector__XXX
 SG_ ErrorRegister : 16|8@1+ (1,0) [0|0] "" Vector__XXX
 SG_ ErrorCode : 0|16@1+ (1,0) [0|0] "" Vector__XXX

BO_ 209 EMCY_081: 8 Vector__XXX
 SG_ ManufacturerSpecific5 : 56|8@1+ (1,0) [0|0] "" Vector__XXX
 SG_ ManufacturerSpecific4 : 48|8@1+ (1,0) [0|0] "" Vector__XXX
 SG_ ManufacturerSpecific3 : 40|8@1+ (1,0) [0|0] "" Vector__XXX
 SG_ ManufacturerSpecific2 : 32|8@1+ (1,0) [0|0] "" Vector__XXX
 SG_ ManufacturerSpecific1 : 24|8@1+ (1,0) [0|0] "" Vector__XXX
 SG_ ErrorRegister : 16|8@1+ (1,0) [0|0] "" Vector__XXX
 SG_ ErrorCode : 0|16@1+ (1,0) [0|0] "" Vector__XXX

BO_ 208 EMCY_080: 8 Vector__XXX
 SG_ ManufacturerSpecific5 : 56|8@1+ (1,0) [0|0] "" Vector__XXX
 SG_ ManufacturerSpecific4 : 48|8@1+ (1,0) [0|0] "" Vector__XXX
 SG_ ManufacturerSpecific3 : 40|8@1+ (1,0) [0|0] "" Vector__XXX
 SG_ ManufacturerSpecific2 : 32|8@1+ (1,0) [0|0] "" Vector__XXX
 SG_ ManufacturerSpecific1 : 24|8@1+ (1,0) [0|0] "" Vector__XXX
 SG_ ErrorRegister : 16|8@1+ (1,0) [0|0] "" Vector__XXX
 SG_ ErrorCode : 0|16@1+ (1,0) [0|0] "" Vector__XXX

BO_ 207 EMCY_079: 8 Vector__XXX
 SG_ ManufacturerSpecific5 : 56|8@1+ (1,0) [0|0] "" Vector__XXX
 SG_ ManufacturerSpecific4 : 48|8@1+ (1,0) [0|0] "" Vector__XXX
 SG_ ManufacturerSpecific3 : 40|8@1+ (1,0) [0|0] "" Vector__XXX
 SG_ ManufacturerSpecific2 : 32|8@1+ (1,0) [0|0] "" Vector__XXX
 SG_ ManufacturerSpecific1 : 24|8@1+ (1,0) [0|0] "" Vector__XXX
 SG_ ErrorRegister : 16|8@1+ (1,0) [0|0] "" Vector__XXX
 SG_ ErrorCode : 0|16@1+ (1,0) [0|0] "" Vector__XXX

BO_ 206 EMCY_078: 8 Vector__XXX
 SG_ ManufacturerSpecific5 : 56|8@1+ (1,0) [0|0] "" Vector__XXX
 SG_ ManufacturerSpecific4 : 48|8@1+ (1,0) [0|0] "" Vector__XXX
 SG_ ManufacturerSpecific3 : 40|8@1+ (1,0) [0|0] "" Vector__XXX
 SG_ ManufacturerSpecific2 : 32|8@1+ (1,0) [0|0] "" Vector__XXX
 SG_ ManufacturerSpecific1 : 24|8@1+ (1,0) [0|0] "" Vector__XXX
 SG_ ErrorRegister : 16|8@1+ (1,0) [0|0] "" Vector__XXX
 SG_ ErrorCode : 0|16@1+ (1,0) [0|0] "" Vector__XXX

BO_ 205 EMCY_077: 8 Vector__XXX
 SG_ ManufacturerSpecific5 : 56|8@1+ (1,0) [0|0] "" Vector__XXX
 SG_ ManufacturerSpecific4 : 48|8@1+ (1,0) [0|0] "" Vector__XXX
 SG_ ManufacturerSpecific3 : 40|8@1+ (1,0) [0|0] "" Vector__XXX
 SG_ ManufacturerSpecific2 : 32|8@1+ (1,0) [0|0] "" Vector__XXX
 SG_ ManufacturerSpecific1 : 24|8@1+ (1,0) [0|0] "" Vector__XXX
 SG_ ErrorRegister : 16|8@1+ (1,0) [0|0] "" Vector__XXX
 SG_ ErrorCode : 0|16@1+ (1,0) [0|0] "" Vector__XXX

BO_ 204 EMCY_076: 8 Vector__XXX
 SG_ ManufacturerSpecific5 : 56|8@1+ (1,0) [0|0] "" Vector__XXX
 SG_ ManufacturerSpecific4 : 48|8@1+ (1,0) [0|0] "" Vector__XXX
 SG_ ManufacturerSpecific3 : 40|8@1+ (1,0) [0|0] "" Vector__XXX
 SG_ ManufacturerSpecific2 : 32|8@1+ (1,0) [0|0] "" Vector__XXX
 SG_ ManufacturerSpecific1 : 24|8@1+ (1,0) [0|0] "" Vector__XXX
 SG_ ErrorRegister : 16|8@1+ (1,0) [0|0] "" Vector__XXX
 SG_ ErrorCode : 0|16@1+ (1,0) [0|0] "" Vector__XXX

BO_ 203 EMCY_075: 8 Vector__XXX
 SG_ ManufacturerSpecific5 : 56|8@1+ (1,0) [0|0] "" Vector__XXX
 SG_ ManufacturerSpecific4 : 48|8@1+ (1,0) [0|0] "" Vector__XXX
 SG_ ManufacturerSpecific3 : 40|8@1+ (1,0) [0|0] "" Vector__XXX
 SG_ ManufacturerSpecific2 : 32|8@1+ (1,0) [0|0] "" Vector__XXX
 SG_ ManufacturerSpecific1 : 24|8@1+ (1,0) [0|0] "" Vector__XXX
 SG_ ErrorRegister : 16|8@1+ (1,0) [0|0] "" Vector__XXX
 SG_ ErrorCode : 0|16@1+ (1,0) [0|0] "" Vector__XXX

BO_ 202 EMCY_074: 8 Vector__XXX
 SG_ ManufacturerSpecific5 : 56|8@1+ (1,0) [0|0] "" Vector__XXX
 SG_ ManufacturerSpecific4 : 48|8@1+ (1,0) [0|0] "" Vector__XXX
 SG_ ManufacturerSpecific3 : 40|8@1+ (1,0) [0|0] "" Vector__XXX
 SG_ ManufacturerSpecific2 : 32|8@1+ (1,0) [0|0] "" Vector__XXX
 SG_ ManufacturerSpecific1 : 24|8@1+ (1,0) [0|0] "" Vector__XXX
 SG_ ErrorRegister : 16|8@1+ (1,0) [0|0] "" Vector__XXX
 SG_ ErrorCode : 0|16@1+ (1,0) [0|0] "" Vector__XXX

BO_ 201 EMCY_073: 8 Vector__XXX
 SG_ ManufacturerSpecific5 : 56|8@1+ (1,0) [0|0] "" Vector__XXX
 SG_ ManufacturerSpecific4 : 48|8@1+ (1,0) [0|0] "" Vector__XXX
 SG_ ManufacturerSpecific3 : 40|8@1+ (1,0) [0|0] "" Vector__XXX
 SG_ ManufacturerSpecific2 : 32|8@1+ (1,0) [0|0] "" Vector__XXX
 SG_ ManufacturerSpecific1 : 24|8@1+ (1,0) [0|0] "" Vector__XXX
 SG_ ErrorRegister : 16|8@1+ (1,0) [0|0] "" Vector__XXX
 SG_ ErrorCode : 0|16@1+ (1,0) [0|0] "" Vector__XXX

BO_ 200 EMCY_072: 8 Vector__XXX
 SG_ ManufacturerSpecific5 : 56|8@1+ (1,0) [0|0] "" Vector__XXX
 SG_ ManufacturerSpecific4 : 48|8@1+ (1,0) [0|0] "" Vector__XXX
 SG_ ManufacturerSpecific3 : 40|8@1+ (1,0) [0|0] "" Vector__XXX
 SG_ ManufacturerSpecific2 : 32|8@1+ (1,0) [0|0] "" Vector__XXX
 SG_ ManufacturerSpecific1 : 24|8@1+ (1,0) [0|0] "" Vector__XXX
 SG_ ErrorRegister : 16|8@1+ (1,0) [0|0] "" Vector__XXX
 SG_ ErrorCode : 0|16@1+ (1,0) [0|0] "" Vector__XXX

BO_ 199 EMCY_071: 8 Vector__XXX
 SG_ ManufacturerSpecific5 : 56|8@1+ (1,0) [0|0] "" Vector__XXX
 SG_ ManufacturerSpecific4 : 48|8@1+ (1,0) [0|0] "" Vector__XXX
 SG_ ManufacturerSpecific3 : 40|8@1+ (1,0) [0|0] "" Vector__XXX
 SG_ ManufacturerSpecific2 : 32|8@1+ (1,0) [0|0] "" Vector__XXX
 SG_ ManufacturerSpecific1 : 24|8@1+ (1,0) [0|0] "" Vector__XXX
 SG_ ErrorRegister : 16|8@1+ (1,0) [0|0] "" Vector__XXX
 SG_ ErrorCode : 0|16@1+ (1,0) [0|0] "" Vector__XXX

BO_ 198 EMCY_070: 8 Vector__XXX
 SG_ ManufacturerSpecific5 : 56|8@1+ (1,0) [0|0] "" Vector__XXX
 SG_ ManufacturerSpecific4 : 48|8@1+ (1,0) [0|0] "" Vector__XXX
 SG_ ManufacturerSpecific3 : 40|8@1+ (1,0) [0|0] "" Vector__XXX
 SG_ ManufacturerSpecific2 : 32|8@1+ (1,0) [0|0] "" Vector__XXX
 SG_ ManufacturerSpecific1 : 24|8@1+ (1,0) [0|0] "" Vector__XXX
 SG_ ErrorRegister : 16|8@1+ (1,0) [0|0] "" Vector__XXX
 SG_ ErrorCode : 0|16@1+ (1,0) [0|0] "" Vector__XXX

BO_ 197 EMCY_069: 8 Vector__XXX
 SG_ ManufacturerSpecific5 : 56|8@1+ (1,0) [0|0] "" Vector__XXX
 SG_ ManufacturerSpecific4 : 48|8@1+ (1,0) [0|0] "" Vector__XXX
 SG_ ManufacturerSpecific3 : 40|8@1+ (1,0) [0|0] "" Vector__XXX
 SG_ ManufacturerSpecific2 : 32|8@1+ (1,0) [0|0] "" Vector__XXX
 SG_ ManufacturerSpecific1 : 24|8@1+ (1,0) [0|0] "" Vector__XXX
 SG_ ErrorRegister : 16|8@1+ (1,0) [0|0] "" Vector__XXX
 SG_ ErrorCode : 0|16@1+ (1,0) [0|0] "" Vector__XXX

BO_ 196 EMCY_068: 8 Vector__XXX
 SG_ ManufacturerSpecific5 : 56|8@1+ (1,0) [0|0] "" Vector__XXX
 SG_ ManufacturerSpecific4 : 48|8@1+ (1,0) [0|0] "" Vector__XXX
 SG_ ManufacturerSpecific3 : 40|8@1+ (1,0) [0|0] "" Vector__XXX
 SG_ ManufacturerSpecific2 : 32|8@1+ (1,0) [0|0] "" Vector__XXX
 SG_ ManufacturerSpecific1 : 24|8@1+ (1,0) [0|0] "" Vector__XXX
 SG_ ErrorRegister : 16|8@1+ (1,0) [0|0] "" Vector__XXX
 SG_ ErrorCode : 0|16@1+ (1,0) [0|0] "" Vector__XXX

BO_ 195 EMCY_067: 8 Vector__XXX
 SG_ ManufacturerSpecific5 : 56|8@1+ (1,0) [0|0] "" Vector__XXX
 SG_ ManufacturerSpecific4 : 48|8@1+ (1,0) [0|0] "" Vector__XXX
 SG_ ManufacturerSpecific3 : 40|8@1+ (1,0) [0|0] "" Vector__XXX
 SG_ ManufacturerSpecific2 : 32|8@1+ (1,0) [0|0] "" Vector__XXX
 SG_ ManufacturerSpecific1 : 24|8@1+ (1,0) [0|0] "" Vector__XXX
 SG_ ErrorRegister : 16|8@1+ (1,0) [0|0] "" Vector__XXX
 SG_ ErrorCode : 0|16@1+ (1,0) [0|0] "" Vector__XXX

BO_ 194 EMCY_066: 8 Vector__XXX
 SG_ ManufacturerSpecific5 : 56|8@1+ (1,0) [0|0] "" Vector__XXX
 SG_ ManufacturerSpecific4 : 48|8@1+ (1,0) [0|0] "" Vector__XXX
 SG_ ManufacturerSpecific3 : 40|8@1+ (1,0) [0|0] "" Vector__XXX
 SG_ ManufacturerSpecific2 : 32|8@1+ (1,0) [0|0] "" Vector__XXX
 SG_ ManufacturerSpecific1 : 24|8@1+ (1,0) [0|0] "" Vector__XXX
 SG_ ErrorRegister : 16|8@1+ (1,0) [0|0] "" Vector__XXX
 SG_ ErrorCode : 0|16@1+ (1,0) [0|0] "" Vector__XXX

BO_ 193 EMCY_065: 8 Vector__XXX
 SG_ ManufacturerSpecific5 : 56|8@1+ (1,0) [0|0] "" Vector__XXX
 SG_ ManufacturerSpecific4 : 48|8@1+ (1,0) [0|0] "" Vector__XXX
 SG_ ManufacturerSpecific3 : 40|8@1+ (1,0) [0|0] "" Vector__XXX
 SG_ ManufacturerSpecific2 : 32|8@1+ (1,0) [0|0] "" Vector__XXX
 SG_ ManufacturerSpecific1 : 24|8@1+ (1,0) [0|0] "" Vector__XXX
 SG_ ErrorRegister : 16|8@1+ (1,0) [0|0] "" Vector__XXX
 SG_ ErrorCode : 0|16@1+ (1,0) [0|0] "" Vector__XXX

BO_ 192 EMCY_064: 8 Vector__XXX
 SG_ ManufacturerSpecific5 : 56|8@1+ (1,0) [0|0] "" Vector__XXX
 SG_ ManufacturerSpecific4 : 48|8@1+ (1,0) [0|0] "" Vector__XXX
 SG_ ManufacturerSpecific3 : 40|8@1+ (1,0) [0|0] "" Vector__XXX
 SG_ ManufacturerSpecific2 : 32|8@1+ (1,0) [0|0] "" Vector__XXX
 SG_ ManufacturerSpecific1 : 24|8@1+ (1,0) [0|0] "" Vector__XXX
 SG_ ErrorRegister : 16|8@1+ (1,0) [0|0] "" Vector__XXX
 SG_ ErrorCode : 0|16@1+ (1,0) [0|0] "" Vector__XXX

BO_ 191 EMCY_063: 8 Vector__XXX
 SG_ ManufacturerSpecific5 : 56|8@1+ (1,0) [0|0] "" Vector__XXX
 SG_ ManufacturerSpecific4 : 48|8@1+ (1,0) [0|0] "" Vector__XXX
 SG_ ManufacturerSpecific3 : 40|8@1+ (1,0) [0|0] "" Vector__XXX
 SG_ ManufacturerSpecific2 : 32|8@1+ (1,0) [0|0] "" Vector__XXX
 SG_ ManufacturerSpecific1 : 24|8@1+ (1,0) [0|0] "" Vector__XXX
 SG_ ErrorRegister : 16|8@1+ (1,0) [0|0] "" Vector__XXX
 SG_ ErrorCode : 0|16@1+ (1,0) [0|0] "" Vector__XXX

BO_ 190 EMCY_062: 8 Vector__XXX
 SG_ ManufacturerSpecific5 : 56|8@1+ (1,0) [0|0] "" Vector__XXX
 SG_ ManufacturerSpecific4 : 48|8@1+ (1,0) [0|0] "" Vector__XXX
 SG_ ManufacturerSpecific3 : 40|8@1+ (1,0) [0|0] "" Vector__XXX
 SG_ ManufacturerSpecific2 : 32|8@1+ (1,0) [0|0] "" Vector__XXX
 SG_ ManufacturerSpecific1 : 24|8@1+ (1,0) [0|0] "" Vector__XXX
 SG_ ErrorRegister : 16|8@1+ (1,0) [0|0] "" Vector__XXX
 SG_ ErrorCode : 0|16@1+ (1,0) [0|0] "" Vector__XXX

BO_ 189 EMCY_061: 8 Vector__XXX
 SG_ ManufacturerSpecific5 : 56|8@1+ (1,0) [0|0] "" Vector__XXX
 SG_ ManufacturerSpecific4 : 48|8@1+ (1,0) [0|0] "" Vector__XXX
 SG_ ManufacturerSpecific3 : 40|8@1+ (1,0) [0|0] "" Vector__XXX
 SG_ ManufacturerSpecific2 : 32|8@1+ (1,0) [0|0] "" Vector__XXX
 SG_ ManufacturerSpecific1 : 24|8@1+ (1,0) [0|0] "" Vector__XXX
 SG_ ErrorRegister : 16|8@1+ (1,0) [0|0] "" Vector__XXX
 SG_ ErrorCode : 0|16@1+ (1,0) [0|0] "" Vector__XXX

BO_ 188 EMCY_060: 8 Vector__XXX
 SG_ ManufacturerSpecific5 : 56|8@1+ (1,0) [0|0] "" Vector__XXX
 SG_ ManufacturerSpecific4 : 48|8@1+ (1,0) [0|0] "" Vector__XXX
 SG_ ManufacturerSpecific3 : 40|8@1+ (1,0) [0|0] "" Vector__XXX
 SG_ ManufacturerSpecific2 : 32|8@1+ (1,0) [0|0] "" Vector__XXX
 SG_ ManufacturerSpecific1 : 24|8@1+ (1,0) [0|0] "" Vector__XXX
 SG_ ErrorRegister : 16|8@1+ (1,0) [0|0] "" Vector__XXX
 SG_ ErrorCode : 0|16@1+ (1,0) [0|0] "" Vector__XXX

BO_ 187 EMCY_059: 8 Vector__XXX
 SG_ ManufacturerSpecific5 : 56|8@1+ (1,0) [0|0] "" Vector__XXX
 SG_ ManufacturerSpecific4 : 48|8@1+ (1,0) [0|0] "" Vector__XXX
 SG_ ManufacturerSpecific3 : 40|8@1+ (1,0) [0|0] "" Vector__XXX
 SG_ ManufacturerSpecific2 : 32|8@1+ (1,0) [0|0] "" Vector__XXX
 SG_ ManufacturerSpecific1 : 24|8@1+ (1,0) [0|0] "" Vector__XXX
 SG_ ErrorRegister : 16|8@1+ (1,0) [0|0] "" Vector__XXX
 SG_ ErrorCode : 0|16@1+ (1,0) [0|0] "" Vector__XXX

BO_ 186 EMCY_058: 8 Vector__XXX
 SG_ ManufacturerSpecific5 : 56|8@1+ (1,0) [0|0] "" Vector__XXX
 SG_ ManufacturerSpecific4 : 48|8@1+ (1,0) [0|0] "" Vector__XXX
 SG_ ManufacturerSpecific3 : 40|8@1+ (1,0) [0|0] "" Vector__XXX
 SG_ ManufacturerSpecific2 : 32|8@1+ (1,0) [0|0] "" Vector__XXX
 SG_ ManufacturerSpecific1 : 24|8@1+ (1,0) [0|0] "" Vector__XXX
 SG_ ErrorRegister : 16|8@1+ (1,0) [0|0] "" Vector__XXX
 SG_ ErrorCode : 0|16@1+ (1,0) [0|0] "" Vector__XXX

BO_ 185 EMCY_057: 8 Vector__XXX
 SG_ ManufacturerSpecific5 : 56|8@1+ (1,0) [0|0] "" Vector__XXX
 SG_ ManufacturerSpecific4 : 48|8@1+ (1,0) [0|0] "" Vector__XXX
 SG_ ManufacturerSpecific3 : 40|8@1+ (1,0) [0|0] "" Vector__XXX
 SG_ ManufacturerSpecific2 : 32|8@1+ (1,0) [0|0] "" Vector__XXX
 SG_ ManufacturerSpecific1 : 24|8@1+ (1,0) [0|0] "" Vector__XXX
 SG_ ErrorRegister : 16|8@1+ (1,0) [0|0] "" Vector__XXX
 SG_ ErrorCode : 0|16@1+ (1,0) [0|0] "" Vector__XXX

BO_ 184 EMCY_056: 8 Vector__XXX
 SG_ ManufacturerSpecific5 : 56|8@1+ (1,0) [0|0] "" Vector__XXX
 SG_ ManufacturerSpecific4 : 48|8@1+ (1,0) [0|0] "" Vector__XXX
 SG_ ManufacturerSpecific3 : 40|8@1+ (1,0) [0|0] "" Vector__XXX
 SG_ ManufacturerSpecific2 : 32|8@1+ (1,0) [0|0] "" Vector__XXX
 SG_ ManufacturerSpecific1 : 24|8@1+ (1,0) [0|0] "" Vector__XXX
 SG_ ErrorRegister : 16|8@1+ (1,0) [0|0] "" Vector__XXX
 SG_ ErrorCode : 0|16@1+ (1,0) [0|0] "" Vector__XXX

BO_ 183 EMCY_055: 8 Vector__XXX
 SG_ ManufacturerSpecific5 : 56|8@1+ (1,0) [0|0] "" Vector__XXX
 SG_ ManufacturerSpecific4 : 48|8@1+ (1,0) [0|0] "" Vector__XXX
 SG_ ManufacturerSpecific3 : 40|8@1+ (1,0) [0|0] "" Vector__XXX
 SG_ ManufacturerSpecific2 : 32|8@1+ (1,0) [0|0] "" Vector__XXX
 SG_ ManufacturerSpecific1 : 24|8@1+ (1,0) [0|0] "" Vector__XXX
 SG_ ErrorRegister : 16|8@1+ (1,0) [0|0] "" Vector__XXX
 SG_ ErrorCode : 0|16@1+ (1,0) [0|0] "" Vector__XXX

BO_ 182 EMCY_054: 8 Vector__XXX
 SG_ ManufacturerSpecific5 : 56|8@1+ (1,0) [0|0] "" Vector__XXX
 SG_ ManufacturerSpecific4 : 48|8@1+ (1,0) [0|0] "" Vector__XXX
 SG_ ManufacturerSpecific3 : 40|8@1+ (1,0) [0|0] "" Vector__XXX
 SG_ ManufacturerSpecific2 : 32|8@1+ (1,0) [0|0] "" Vector__XXX
 SG_ ManufacturerSpecific1 : 24|8@1+ (1,0) [0|0] "" Vector__XXX
 SG_ ErrorRegister : 16|8@1+ (1,0) [0|0] "" Vector__XXX
 SG_ ErrorCode : 0|16@1+ (1,0) [0|0] "" Vector__XXX

BO_ 181 EMCY_053: 8 Vector__XXX
 SG_ ManufacturerSpecific5 : 56|8@1+ (1,0) [0|0] "" Vector__XXX
 SG_ ManufacturerSpecific4 : 48|8@1+ (1,0) [0|0] "" Vector__XXX
 SG_ ManufacturerSpecific3 : 40|8@1+ (1,0) [0|0] "" Vector__XXX
 SG_ ManufacturerSpecific2 : 32|8@1+ (1,0) [0|0] "" Vector__XXX
 SG_ ManufacturerSpecific1 : 24|8@1+ (1,0) [0|0] "" Vector__XXX
 SG_ ErrorRegister : 16|8@1+ (1,0) [0|0] "" Vector__XXX
 SG_ ErrorCode : 0|16@1+ (1,0) [0|0] "" Vector__XXX

BO_ 180 EMCY_052: 8 Vector__XXX
 SG_ ManufacturerSpecific5 : 56|8@1+ (1,0) [0|0] "" Vector__XXX
 SG_ ManufacturerSpecific4 : 48|8@1+ (1,0) [0|0] "" Vector__XXX
 SG_ ManufacturerSpecific3 : 40|8@1+ (1,0) [0|0] "" Vector__XXX
 SG_ ManufacturerSpecific2 : 32|8@1+ (1,0) [0|0] "" Vector__XXX
 SG_ ManufacturerSpecific1 : 24|8@1+ (1,0) [0|0] "" Vector__XXX
 SG_ ErrorRegister : 16|8@1+ (1,0) [0|0] "" Vector__XXX
 SG_ ErrorCode : 0|16@1+ (1,0) [0|0] "" Vector__XXX

BO_ 179 EMCY_051: 8 Vector__XXX
 SG_ ManufacturerSpecific5 : 56|8@1+ (1,0) [0|0] "" Vector__XXX
 SG_ ManufacturerSpecific4 : 48|8@1+ (1,0) [0|0] "" Vector__XXX
 SG_ ManufacturerSpecific3 : 40|8@1+ (1,0) [0|0] "" Vector__XXX
 SG_ ManufacturerSpecific2 : 32|8@1+ (1,0) [0|0] "" Vector__XXX
 SG_ ManufacturerSpecific1 : 24|8@1+ (1,0) [0|0] "" Vector__XXX
 SG_ ErrorRegister : 16|8@1+ (1,0) [0|0] "" Vector__XXX
 SG_ ErrorCode : 0|16@1+ (1,0) [0|0] "" Vector__XXX

BO_ 178 EMCY_050: 8 Vector__XXX
 SG_ ManufacturerSpecific5 : 56|8@1+ (1,0) [0|0] "" Vector__XXX
 SG_ ManufacturerSpecific4 : 48|8@1+ (1,0) [0|0] "" Vector__XXX
 SG_ ManufacturerSpecific3 : 40|8@1+ (1,0) [0|0] "" Vector__XXX
 SG_ ManufacturerSpecific2 : 32|8@1+ (1,0) [0|0] "" Vector__XXX
 SG_ ManufacturerSpecific1 : 24|8@1+ (1,0) [0|0] "" Vector__XXX
 SG_ ErrorRegister : 16|8@1+ (1,0) [0|0] "" Vector__XXX
 SG_ ErrorCode : 0|16@1+ (1,0) [0|0] "" Vector__XXX

BO_ 177 EMCY_049: 8 Vector__XXX
 SG_ ManufacturerSpecific5 : 56|8@1+ (1,0) [0|0] "" Vector__XXX
 SG_ ManufacturerSpecific4 : 48|8@1+ (1,0) [0|0] "" Vector__XXX
 SG_ ManufacturerSpecific3 : 40|8@1+ (1,0) [0|0] "" Vector__XXX
 SG_ ManufacturerSpecific2 : 32|8@1+ (1,0) [0|0] "" Vector__XXX
 SG_ ManufacturerSpecific1 : 24|8@1+ (1,0) [0|0] "" Vector__XXX
 SG_ ErrorRegister : 16|8@1+ (1,0) [0|0] "" Vector__XXX
 SG_ ErrorCode : 0|16@1+ (1,0) [0|0] "" Vector__XXX

BO_ 176 EMCY_048: 8 Vector__XXX
 SG_ ManufacturerSpecific5 : 56|8@1+ (1,0) [0|0] "" Vector__XXX
 SG_ ManufacturerSpecific4 : 48|8@1+ (1,0) [0|0] "" Vector__XXX
 SG_ ManufacturerSpecific3 : 40|8@1+ (1,0) [0|0] "" Vector__XXX
 SG_ ManufacturerSpecific2 : 32|8@1+ (1,0) [0|0] "" Vector__XXX
 SG_ ManufacturerSpecific1 : 24|8@1+ (1,0) [0|0] "" Vector__XXX
 SG_ ErrorRegister : 16|8@1+ (1,0) [0|0] "" Vector__XXX
 SG_ ErrorCode : 0|16@1+ (1,0) [0|0] "" Vector__XXX

BO_ 175 EMCY_047: 8 Vector__XXX
 SG_ ManufacturerSpecific5 : 56|8@1+ (1,0) [0|0] "" Vector__XXX
 SG_ ManufacturerSpecific4 : 48|8@1+ (1,0) [0|0] "" Vector__XXX
 SG_ ManufacturerSpecific3 : 40|8@1+ (1,0) [0|0] "" Vector__XXX
 SG_ ManufacturerSpecific2 : 32|8@1+ (1,0) [0|0] "" Vector__XXX
 SG_ ManufacturerSpecific1 : 24|8@1+ (1,0) [0|0] "" Vector__XXX
 SG_ ErrorRegister : 16|8@1+ (1,0) [0|0] "" Vector__XXX
 SG_ ErrorCode : 0|16@1+ (1,0) [0|0] "" Vector__XXX

BO_ 174 EMCY_046: 8 Vector__XXX
 SG_ ManufacturerSpecific5 : 56|8@1+ (1,0) [0|0] "" Vector__XXX
 SG_ ManufacturerSpecific4 : 48|8@1+ (1,0) [0|0] "" Vector__XXX
 SG_ ManufacturerSpecific3 : 40|8@1+ (1,0) [0|0] "" Vector__XXX
 SG_ ManufacturerSpecific2 : 32|8@1+ (1,0) [0|0] "" Vector__XXX
 SG_ ManufacturerSpecific1 : 24|8@1+ (1,0) [0|0] "" Vector__XXX
 SG_ ErrorRegister : 16|8@1+ (1,0) [0|0] "" Vector__XXX
 SG_ ErrorCode : 0|16@1+ (1,0) [0|0] "" Vector__XXX

BO_ 173 EMCY_045: 8 Vector__XXX
 SG_ ManufacturerSpecific5 : 56|8@1+ (1,0) [0|0] "" Vector__XXX
 SG_ ManufacturerSpecific4 : 48|8@1+ (1,0) [0|0] "" Vector__XXX
 SG_ ManufacturerSpecific3 : 40|8@1+ (1,0) [0|0] "" Vector__XXX
 SG_ ManufacturerSpecific2 : 32|8@1+ (1,0) [0|0] "" Vector__XXX
 SG_ ManufacturerSpecific1 : 24|8@1+ (1,0) [0|0] "" Vector__XXX
 SG_ ErrorRegister : 16|8@1+ (1,0) [0|0] "" Vector__XXX
 SG_ ErrorCode : 0|16@1+ (1,0) [0|0] "" Vector__XXX

BO_ 172 EMCY_044: 8 Vector__XXX
 SG_ ManufacturerSpecific5 : 56|8@1+ (1,0) [0|0] "" Vector__XXX
 SG_ ManufacturerSpecific4 : 48|8@1+ (1,0) [0|0] "" Vector__XXX
 SG_ ManufacturerSpecific3 : 40|8@1+ (1,0) [0|0] "" Vector__XXX
 SG_ ManufacturerSpecific2 : 32|8@1+ (1,0) [0|0] "" Vector__XXX
 SG_ ManufacturerSpecific1 : 24|8@1+ (1,0) [0|0] "" Vector__XXX
 SG_ ErrorRegister : 16|8@1+ (1,0) [0|0] "" Vector__XXX
 SG_ ErrorCode : 0|16@1+ (1,0) [0|0] "" Vector__XXX

BO_ 171 EMCY_043: 8 Vector__XXX
 SG_ ManufacturerSpecific5 : 56|8@1+ (1,0) [0|0] "" Vector__XXX
 SG_ ManufacturerSpecific4 : 48|8@1+ (1,0) [0|0] "" Vector__XXX
 SG_ ManufacturerSpecific3 : 40|8@1+ (1,0) [0|0] "" Vector__XXX
 SG_ ManufacturerSpecific2 : 32|8@1+ (1,0) [0|0] "" Vector__XXX
 SG_ ManufacturerSpecific1 : 24|8@1+ (1,0) [0|0] "" Vector__XXX
 SG_ ErrorRegister : 16|8@1+ (1,0) [0|0] "" Vector__XXX
 SG_ ErrorCode : 0|16@1+ (1,0) [0|0] "" Vector__XXX

BO_ 170 EMCY_042: 8 Vector__XXX
 SG_ ManufacturerSpecific5 : 56|8@1+ (1,0) [0|0] "" Vector__XXX
 SG_ ManufacturerSpecific4 : 48|8@1+ (1,0) [0|0] "" Vector__XXX
 SG_ ManufacturerSpecific3 : 40|8@1+ (1,0) [0|0] "" Vector__XXX
 SG_ ManufacturerSpecific2 : 32|8@1+ (1,0) [0|0] "" Vector__XXX
 SG_ ManufacturerSpecific1 : 24|8@1+ (1,0) [0|0] "" Vector__XXX
 SG_ ErrorRegister : 16|8@1+ (1,0) [0|0] "" Vector__XXX
 SG_ ErrorCode : 0|16@1+ (1,0) [0|0] "" Vector__XXX

BO_ 169 EMCY_041: 8 Vector__XXX
 SG_ ManufacturerSpecific5 : 56|8@1+ (1,0) [0|0] "" Vector__XXX
 SG_ ManufacturerSpecific4 : 48|8@1+ (1,0) [0|0] "" Vector__XXX
 SG_ ManufacturerSpecific3 : 40|8@1+ (1,0) [0|0] "" Vector__XXX
 SG_ ManufacturerSpecific2 : 32|8@1+ (1,0) [0|0] "" Vector__XXX
 SG_ ManufacturerSpecific1 : 24|8@1+ (1,0) [0|0] "" Vector__XXX
 SG_ ErrorRegister : 16|8@1+ (1,0) [0|0] "" Vector__XXX
 SG_ ErrorCode : 0|16@1+ (1,0) [0|0] "" Vector__XXX

BO_ 168 EMCY_040: 8 Vector__XXX
 SG_ ManufacturerSpecific5 : 56|8@1+ (1,0) [0|0] "" Vector__XXX
 SG_ ManufacturerSpecific4 : 48|8@1+ (1,0) [0|0] "" Vector__XXX
 SG_ ManufacturerSpecific3 : 40|8@1+ (1,0) [0|0] "" Vector__XXX
 SG_ ManufacturerSpecific2 : 32|8@1+ (1,0) [0|0] "" Vector__XXX
 SG_ ManufacturerSpecific1 : 24|8@1+ (1,0) [0|0] "" Vector__XXX
 SG_ ErrorRegister : 16|8@1+ (1,0) [0|0] "" Vector__XXX
 SG_ ErrorCode : 0|16@1+ (1,0) [0|0] "" Vector__XXX

BO_ 167 EMCY_039: 8 Vector__XXX
 SG_ ManufacturerSpecific5 : 56|8@1+ (1,0) [0|0] "" Vector__XXX
 SG_ ManufacturerSpecific4 : 48|8@1+ (1,0) [0|0] "" Vector__XXX
 SG_ ManufacturerSpecific3 : 40|8@1+ (1,0) [0|0] "" Vector__XXX
 SG_ ManufacturerSpecific2 : 32|8@1+ (1,0) [0|0] "" Vector__XXX
 SG_ ManufacturerSpecific1 : 24|8@1+ (1,0) [0|0] "" Vector__XXX
 SG_ ErrorRegister : 16|8@1+ (1,0) [0|0] "" Vector__XXX
 SG_ ErrorCode : 0|16@1+ (1,0) [0|0] "" Vector__XXX

BO_ 166 EMCY_038: 8 Vector__XXX
 SG_ ManufacturerSpecific5 : 56|8@1+ (1,0) [0|0] "" Vector__XXX
 SG_ ManufacturerSpecific4 : 48|8@1+ (1,0) [0|0] "" Vector__XXX
 SG_ ManufacturerSpecific3 : 40|8@1+ (1,0) [0|0] "" Vector__XXX
 SG_ ManufacturerSpecific2 : 32|8@1+ (1,0) [0|0] "" Vector__XXX
 SG_ ManufacturerSpecific1 : 24|8@1+ (1,0) [0|0] "" Vector__XXX
 SG_ ErrorRegister : 16|8@1+ (1,0) [0|0] "" Vector__XXX
 SG_ ErrorCode : 0|16@1+ (1,0) [0|0] "" Vector__XXX

BO_ 165 EMCY_037: 8 Vector__XXX
 SG_ ManufacturerSpecific5 : 56|8@1+ (1,0) [0|0] "" Vector__XXX
 SG_ ManufacturerSpecific4 : 48|8@1+ (1,0) [0|0] "" Vector__XXX
 SG_ ManufacturerSpecific3 : 40|8@1+ (1,0) [0|0] "" Vector__XXX
 SG_ ManufacturerSpecific2 : 32|8@1+ (1,0) [0|0] "" Vector__XXX
 SG_ ManufacturerSpecific1 : 24|8@1+ (1,0) [0|0] "" Vector__XXX
 SG_ ErrorRegister : 16|8@1+ (1,0) [0|0] "" Vector__XXX
 SG_ ErrorCode : 0|16@1+ (1,0) [0|0] "" Vector__XXX

BO_ 164 EMCY_036: 8 Vector__XXX
 SG_ ManufacturerSpecific5 : 56|8@1+ (1,0) [0|0] "" Vector__XXX
 SG_ ManufacturerSpecific4 : 48|8@1+ (1,0) [0|0] "" Vector__XXX
 SG_ ManufacturerSpecific3 : 40|8@1+ (1,0) [0|0] "" Vector__XXX
 SG_ ManufacturerSpecific2 : 32|8@1+ (1,0) [0|0] "" Vector__XXX
 SG_ ManufacturerSpecific1 : 24|8@1+ (1,0) [0|0] "" Vector__XXX
 SG_ ErrorRegister : 16|8@1+ (1,0) [0|0] "" Vector__XXX
 SG_ ErrorCode : 0|16@1+ (1,0) [0|0] "" Vector__XXX

BO_ 163 EMCY_035: 8 Vector__XXX
 SG_ ManufacturerSpecific5 : 56|8@1+ (1,0) [0|0] "" Vector__XXX
 SG_ ManufacturerSpecific4 : 48|8@1+ (1,0) [0|0] "" Vector__XXX
 SG_ ManufacturerSpecific3 : 40|8@1+ (1,0) [0|0] "" Vector__XXX
 SG_ ManufacturerSpecific2 : 32|8@1+ (1,0) [0|0] "" Vector__XXX
 SG_ ManufacturerSpecific1 : 24|8@1+ (1,0) [0|0] "" Vector__XXX
 SG_ ErrorRegister : 16|8@1+ (1,0) [0|0] "" Vector__XXX
 SG_ ErrorCode : 0|16@1+ (1,0) [0|0] "" Vector__XXX

BO_ 162 EMCY_034: 8 Vector__XXX
 SG_ ManufacturerSpecific5 : 56|8@1+ (1,0) [0|0] "" Vector__XXX
 SG_ ManufacturerSpecific4 : 48|8@1+ (1,0) [0|0] "" Vector__XXX
 SG_ ManufacturerSpecific3 : 40|8@1+ (1,0) [0|0] "" Vector__XXX
 SG_ ManufacturerSpecific2 : 32|8@1+ (1,0) [0|0] "" Vector__XXX
 SG_ ManufacturerSpecific1 : 24|8@1+ (1,0) [0|0] "" Vector__XXX
 SG_ ErrorRegister : 16|8@1+ (1,0) [0|0] "" Vector__XXX
 SG_ ErrorCode : 0|16@1+ (1,0) [0|0] "" Vector__XXX

BO_ 161 EMCY_033: 8 Vector__XXX
 SG_ ManufacturerSpecific5 : 56|8@1+ (1,0) [0|0] "" Vector__XXX
 SG_ ManufacturerSpecific4 : 48|8@1+ (1,0) [0|0] "" Vector__XXX
 SG_ ManufacturerSpecific3 : 40|8@1+ (1,0) [0|0] "" Vector__XXX
 SG_ ManufacturerSpecific2 : 32|8@1+ (1,0) [0|0] "" Vector__XXX
 SG_ ManufacturerSpecific1 : 24|8@1+ (1,0) [0|0] "" Vector__XXX
 SG_ ErrorRegister : 16|8@1+ (1,0) [0|0] "" Vector__XXX
 SG_ ErrorCode : 0|16@1+ (1,0) [0|0] "" Vector__XXX

BO_ 160 EMCY_032: 8 Vector__XXX
 SG_ ManufacturerSpecific5 : 56|8@1+ (1,0) [0|0] "" Vector__XXX
 SG_ ManufacturerSpecific4 : 48|8@1+ (1,0) [0|0] "" Vector__XXX
 SG_ ManufacturerSpecific3 : 40|8@1+ (1,0) [0|0] "" Vector__XXX
 SG_ ManufacturerSpecific2 : 32|8@1+ (1,0) [0|0] "" Vector__XXX
 SG_ ManufacturerSpecific1 : 24|8@1+ (1,0) [0|0] "" Vector__XXX
 SG_ ErrorRegister : 16|8@1+ (1,0) [0|0] "" Vector__XXX
 SG_ ErrorCode : 0|16@1+ (1,0) [0|0] "" Vector__XXX

BO_ 159 EMCY_031: 8 Vector__XXX
 SG_ ManufacturerSpecific5 : 56|8@1+ (1,0) [0|0] "" Vector__XXX
 SG_ ManufacturerSpecific4 : 48|8@1+ (1,0) [0|0] "" Vector__XXX
 SG_ ManufacturerSpecific3 : 40|8@1+ (1,0) [0|0] "" Vector__XXX
 SG_ ManufacturerSpecific2 : 32|8@1+ (1,0) [0|0] "" Vector__XXX
 SG_ ManufacturerSpecific1 : 24|8@1+ (1,0) [0|0] "" Vector__XXX
 SG_ ErrorRegister : 16|8@1+ (1,0) [0|0] "" Vector__XXX
 SG_ ErrorCode : 0|16@1+ (1,0) [0|0] "" Vector__XXX

BO_ 158 EMCY_030: 8 Vector__XXX
 SG_ ManufacturerSpecific5 : 56|8@1+ (1,0) [0|0] "" Vector__XXX
 SG_ ManufacturerSpecific4 : 48|8@1+ (1,0) [0|0] "" Vector__XXX
 SG_ ManufacturerSpecific3 : 40|8@1+ (1,0) [0|0] "" Vector__XXX
 SG_ ManufacturerSpecific2 : 32|8@1+ (1,0) [0|0] "" Vector__XXX
 SG_ ManufacturerSpecific1 : 24|8@1+ (1,0) [0|0] "" Vector__XXX
 SG_ ErrorRegister : 16|8@1+ (1,0) [0|0] "" Vector__XXX
 SG_ ErrorCode : 0|16@1+ (1,0) [0|0] "" Vector__XXX

BO_ 157 EMCY_029: 8 Vector__XXX
 SG_ ManufacturerSpecific5 : 56|8@1+ (1,0) [0|0] "" Vector__XXX
 SG_ ManufacturerSpecific4 : 48|8@1+ (1,0) [0|0] "" Vector__XXX
 SG_ ManufacturerSpecific3 : 40|8@1+ (1,0) [0|0] "" Vector__XXX
 SG_ ManufacturerSpecific2 : 32|8@1+ (1,0) [0|0] "" Vector__XXX
 SG_ ManufacturerSpecific1 : 24|8@1+ (1,0) [0|0] "" Vector__XXX
 SG_ ErrorRegister : 16|8@1+ (1,0) [0|0] "" Vector__XXX
 SG_ ErrorCode : 0|16@1+ (1,0) [0|0] "" Vector__XXX

BO_ 156 EMCY_028: 8 Vector__XXX
 SG_ ManufacturerSpecific5 : 56|8@1+ (1,0) [0|0] "" Vector__XXX
 SG_ ManufacturerSpecific4 : 48|8@1+ (1,0) [0|0] "" Vector__XXX
 SG_ ManufacturerSpecific3 : 40|8@1+ (1,0) [0|0] "" Vector__XXX
 SG_ ManufacturerSpecific2 : 32|8@1+ (1,0) [0|0] "" Vector__XXX
 SG_ ManufacturerSpecific1 : 24|8@1+ (1,0) [0|0] "" Vector__XXX
 SG_ ErrorRegister : 16|8@1+ (1,0) [0|0] "" Vector__XXX
 SG_ ErrorCode : 0|16@1+ (1,0) [0|0] "" Vector__XXX

BO_ 155 EMCY_027: 8 Vector__XXX
 SG_ ManufacturerSpecific5 : 56|8@1+ (1,0) [0|0] "" Vector__XXX
 SG_ ManufacturerSpecific4 : 48|8@1+ (1,0) [0|0] "" Vector__XXX
 SG_ ManufacturerSpecific3 : 40|8@1+ (1,0) [0|0] "" Vector__XXX
 SG_ ManufacturerSpecific2 : 32|8@1+ (1,0) [0|0] "" Vector__XXX
 SG_ ManufacturerSpecific1 : 24|8@1+ (1,0) [0|0] "" Vector__XXX
 SG_ ErrorRegister : 16|8@1+ (1,0) [0|0] "" Vector__XXX
 SG_ ErrorCode : 0|16@1+ (1,0) [0|0] "" Vector__XXX

BO_ 154 EMCY_026: 8 Vector__XXX
 SG_ ManufacturerSpecific5 : 56|8@1+ (1,0) [0|0] "" Vector__XXX
 SG_ ManufacturerSpecific4 : 48|8@1+ (1,0) [0|0] "" Vector__XXX
 SG_ ManufacturerSpecific3 : 40|8@1+ (1,0) [0|0] "" Vector__XXX
 SG_ ManufacturerSpecific2 : 32|8@1+ (1,0) [0|0] "" Vector__XXX
 SG_ ManufacturerSpecific1 : 24|8@1+ (1,0) [0|0] "" Vector__XXX
 SG_ ErrorRegister : 16|8@1+ (1,0) [0|0] "" Vector__XXX
 SG_ ErrorCode : 0|16@1+ (1,0) [0|0] "" Vector__XXX

BO_ 153 EMCY_025: 8 Vector__XXX
 SG_ ManufacturerSpecific5 : 56|8@1+ (1,0) [0|0] "" Vector__XXX
 SG_ ManufacturerSpecific4 : 48|8@1+ (1,0) [0|0] "" Vector__XXX
 SG_ ManufacturerSpecific3 : 40|8@1+ (1,0) [0|0] "" Vector__XXX
 SG_ ManufacturerSpecific2 : 32|8@1+ (1,0) [0|0] "" Vector__XXX
 SG_ ManufacturerSpecific1 : 24|8@1+ (1,0) [0|0] "" Vector__XXX
 SG_ ErrorRegister : 16|8@1+ (1,0) [0|0] "" Vector__XXX
 SG_ ErrorCode : 0|16@1+ (1,0) [0|0] "" Vector__XXX

BO_ 152 EMCY_024: 8 Vector__XXX
 SG_ ManufacturerSpecific5 : 56|8@1+ (1,0) [0|0] "" Vector__XXX
 SG_ ManufacturerSpecific4 : 48|8@1+ (1,0) [0|0] "" Vector__XXX
 SG_ ManufacturerSpecific3 : 40|8@1+ (1,0) [0|0] "" Vector__XXX
 SG_ ManufacturerSpecific2 : 32|8@1+ (1,0) [0|0] "" Vector__XXX
 SG_ ManufacturerSpecific1 : 24|8@1+ (1,0) [0|0] "" Vector__XXX
 SG_ ErrorRegister : 16|8@1+ (1,0) [0|0] "" Vector__XXX
 SG_ ErrorCode : 0|16@1+ (1,0) [0|0] "" Vector__XXX

BO_ 151 EMCY_023: 8 Vector__XXX
 SG_ ManufacturerSpecific5 : 56|8@1+ (1,0) [0|0] "" Vector__XXX
 SG_ ManufacturerSpecific4 : 48|8@1+ (1,0) [0|0] "" Vector__XXX
 SG_ ManufacturerSpecific3 : 40|8@1+ (1,0) [0|0] "" Vector__XXX
 SG_ ManufacturerSpecific2 : 32|8@1+ (1,0) [0|0] "" Vector__XXX
 SG_ ManufacturerSpecific1 : 24|8@1+ (1,0) [0|0] "" Vector__XXX
 SG_ ErrorRegister : 16|8@1+ (1,0) [0|0] "" Vector__XXX
 SG_ ErrorCode : 0|16@1+ (1,0) [0|0] "" Vector__XXX

BO_ 150 EMCY_022: 8 Vector__XXX
 SG_ ManufacturerSpecific5 : 56|8@1+ (1,0) [0|0] "" Vector__XXX
 SG_ ManufacturerSpecific4 : 48|8@1+ (1,0) [0|0] "" Vector__XXX
 SG_ ManufacturerSpecific3 : 40|8@1+ (1,0) [0|0] "" Vector__XXX
 SG_ ManufacturerSpecific2 : 32|8@1+ (1,0) [0|0] "" Vector__XXX
 SG_ ManufacturerSpecific1 : 24|8@1+ (1,0) [0|0] "" Vector__XXX
 SG_ ErrorRegister : 16|8@1+ (1,0) [0|0] "" Vector__XXX
 SG_ ErrorCode : 0|16@1+ (1,0) [0|0] "" Vector__XXX

BO_ 149 EMCY_021: 8 Vector__XXX
 SG_ ManufacturerSpecific5 : 56|8@1+ (1,0) [0|0] "" Vector__XXX
 SG_ ManufacturerSpecific4 : 48|8@1+ (1,0) [0|0] "" Vector__XXX
 SG_ ManufacturerSpecific3 : 40|8@1+ (1,0) [0|0] "" Vector__XXX
 SG_ ManufacturerSpecific2 : 32|8@1+ (1,0) [0|0] "" Vector__XXX
 SG_ ManufacturerSpecific1 : 24|8@1+ (1,0) [0|0] "" Vector__XXX
 SG_ ErrorRegister : 16|8@1+ (1,0) [0|0] "" Vector__XXX
 SG_ ErrorCode : 0|16@1+ (1,0) [0|0] "" Vector__XXX

BO_ 148 EMCY_020: 8 Vector__XXX
 SG_ ManufacturerSpecific5 : 56|8@1+ (1,0) [0|0] "" Vector__XXX
 SG_ ManufacturerSpecific4 : 48|8@1+ (1,0) [0|0] "" Vector__XXX
 SG_ ManufacturerSpecific3 : 40|8@1+ (1,0) [0|0] "" Vector__XXX
 SG_ ManufacturerSpecific2 : 32|8@1+ (1,0) [0|0] "" Vector__XXX
 SG_ ManufacturerSpecific1 : 24|8@1+ (1,0) [0|0] "" Vector__XXX
 SG_ ErrorRegister : 16|8@1+ (1,0) [0|0] "" Vector__XXX
 SG_ ErrorCode : 0|16@1+ (1,0) [0|0] "" Vector__XXX

BO_ 147 EMCY_019: 8 Vector__XXX
 SG_ ManufacturerSpecific5 : 56|8@1+ (1,0) [0|0] "" Vector__XXX
 SG_ ManufacturerSpecific4 : 48|8@1+ (1,0) [0|0] "" Vector__XXX
 SG_ ManufacturerSpecific3 : 40|8@1+ (1,0) [0|0] "" Vector__XXX
 SG_ ManufacturerSpecific2 : 32|8@1+ (1,0) [0|0] "" Vector__XXX
 SG_ ManufacturerSpecific1 : 24|8@1+ (1,0) [0|0] "" Vector__XXX
 SG_ ErrorRegister : 16|8@1+ (1,0) [0|0] "" Vector__XXX
 SG_ ErrorCode : 0|16@1+ (1,0) [0|0] "" Vector__XXX

BO_ 146 EMCY_018: 8 Vector__XXX
 SG_ ManufacturerSpecific5 : 56|8@1+ (1,0) [0|0] "" Vector__XXX
 SG_ ManufacturerSpecific4 : 48|8@1+ (1,0) [0|0] "" Vector__XXX
 SG_ ManufacturerSpecific3 : 40|8@1+ (1,0) [0|0] "" Vector__XXX
 SG_ ManufacturerSpecific2 : 32|8@1+ (1,0) [0|0] "" Vector__XXX
 SG_ ManufacturerSpecific1 : 24|8@1+ (1,0) [0|0] "" Vector__XXX
 SG_ ErrorRegister : 16|8@1+ (1,0) [0|0] "" Vector__XXX
 SG_ ErrorCode : 0|16@1+ (1,0) [0|0] "" Vector__XXX

BO_ 145 EMCY_017: 8 Vector__XXX
 SG_ ManufacturerSpecific5 : 56|8@1+ (1,0) [0|0] "" Vector__XXX
 SG_ ManufacturerSpecific4 : 48|8@1+ (1,0) [0|0] "" Vector__XXX
 SG_ ManufacturerSpecific3 : 40|8@1+ (1,0) [0|0] "" Vector__XXX
 SG_ ManufacturerSpecific2 : 32|8@1+ (1,0) [0|0] "" Vector__XXX
 SG_ ManufacturerSpecific1 : 24|8@1+ (1,0) [0|0] "" Vector__XXX
 SG_ ErrorRegister : 16|8@1+ (1,0) [0|0] "" Vector__XXX
 SG_ ErrorCode : 0|16@1+ (1,0) [0|0] "" Vector__XXX

BO_ 144 EMCY_016: 8 Vector__XXX
 SG_ ManufacturerSpecific5 : 56|8@1+ (1,0) [0|0] "" Vector__XXX
 SG_ ManufacturerSpecific4 : 48|8@1+ (1,0) [0|0] "" Vector__XXX
 SG_ ManufacturerSpecific3 : 40|8@1+ (1,0) [0|0] "" Vector__XXX
 SG_ ManufacturerSpecific2 : 32|8@1+ (1,0) [0|0] "" Vector__XXX
 SG_ ManufacturerSpecific1 : 24|8@1+ (1,0) [0|0] "" Vector__XXX
 SG_ ErrorRegister : 16|8@1+ (1,0) [0|0] "" Vector__XXX
 SG_ ErrorCode : 0|16@1+ (1,0) [0|0] "" Vector__XXX

BO_ 143 EMCY_015: 8 Vector__XXX
 SG_ ManufacturerSpecific5 : 56|8@1+ (1,0) [0|0] "" Vector__XXX
 SG_ ManufacturerSpecific4 : 48|8@1+ (1,0) [0|0] "" Vector__XXX
 SG_ ManufacturerSpecific3 : 40|8@1+ (1,0) [0|0] "" Vector__XXX
 SG_ ManufacturerSpecific2 : 32|8@1+ (1,0) [0|0] "" Vector__XXX
 SG_ ManufacturerSpecific1 : 24|8@1+ (1,0) [0|0] "" Vector__XXX
 SG_ ErrorRegister : 16|8@1+ (1,0) [0|0] "" Vector__XXX
 SG_ ErrorCode : 0|16@1+ (1,0) [0|0] "" Vector__XXX

BO_ 142 EMCY_014: 8 Vector__XXX
 SG_ ManufacturerSpecific5 : 56|8@1+ (1,0) [0|0] "" Vector__XXX
 SG_ ManufacturerSpecific4 : 48|8@1+ (1,0) [0|0] "" Vector__XXX
 SG_ ManufacturerSpecific3 : 40|8@1+ (1,0) [0|0] "" Vector__XXX
 SG_ ManufacturerSpecific2 : 32|8@1+ (1,0) [0|0] "" Vector__XXX
 SG_ ManufacturerSpecific1 : 24|8@1+ (1,0) [0|0] "" Vector__XXX
 SG_ ErrorRegister : 16|8@1+ (1,0) [0|0] "" Vector__XXX
 SG_ ErrorCode : 0|16@1+ (1,0) [0|0] "" Vector__XXX

BO_ 141 EMCY_013: 8 Vector__XXX
 SG_ ManufacturerSpecific5 : 56|8@1+ (1,0) [0|0] "" Vector__XXX
 SG_ ManufacturerSpecific4 : 48|8@1+ (1,0) [0|0] "" Vector__XXX
 SG_ ManufacturerSpecific3 : 40|8@1+ (1,0) [0|0] "" Vector__XXX
 SG_ ManufacturerSpecific2 : 32|8@1+ (1,0) [0|0] "" Vector__XXX
 SG_ ManufacturerSpecific1 : 24|8@1+ (1,0) [0|0] "" Vector__XXX
 SG_ ErrorRegister : 16|8@1+ (1,0) [0|0] "" Vector__XXX
 SG_ ErrorCode : 0|16@1+ (1,0) [0|0] "" Vector__XXX

BO_ 140 EMCY_012: 8 Vector__XXX
 SG_ ManufacturerSpecific5 : 56|8@1+ (1,0) [0|0] "" Vector__XXX
 SG_ ManufacturerSpecific4 : 48|8@1+ (1,0) [0|0] "" Vector__XXX
 SG_ ManufacturerSpecific3 : 40|8@1+ (1,0) [0|0] "" Vector__XXX
 SG_ ManufacturerSpecific2 : 32|8@1+ (1,0) [0|0] "" Vector__XXX
 SG_ ManufacturerSpecific1 : 24|8@1+ (1,0) [0|0] "" Vector__XXX
 SG_ ErrorRegister : 16|8@1+ (1,0) [0|0] "" Vector__XXX
 SG_ ErrorCode : 0|16@1+ (1,0) [0|0] "" Vector__XXX

BO_ 139 EMCY_011: 8 Vector__XXX
 SG_ ManufacturerSpecific5 : 56|8@1+ (1,0) [0|0] "" Vector__XXX
 SG_ ManufacturerSpecific4 : 48|8@1+ (1,0) [0|0] "" Vector__XXX
 SG_ ManufacturerSpecific3 : 40|8@1+ (1,0) [0|0] "" Vector__XXX
 SG_ ManufacturerSpecific2 : 32|8@1+ (1,0) [0|0] "" Vector__XXX
 SG_ ManufacturerSpecific1 : 24|8@1+ (1,0) [0|0] "" Vector__XXX
 SG_ ErrorRegister : 16|8@1+ (1,0) [0|0] "" Vector__XXX
 SG_ ErrorCode : 0|16@1+ (1,0) [0|0] "" Vector__XXX

BO_ 138 EMCY_010: 8 Vector__XXX
 SG_ ManufacturerSpecific5 : 56|8@1+ (1,0) [0|0] "" Vector__XXX
 SG_ ManufacturerSpecific4 : 48|8@1+ (1,0) [0|0] "" Vector__XXX
 SG_ ManufacturerSpecific3 : 40|8@1+ (1,0) [0|0] "" Vector__XXX
 SG_ ManufacturerSpecific2 : 32|8@1+ (1,0) [0|0] "" Vector__XXX
 SG_ ManufacturerSpecific1 : 24|8@1+ (1,0) [0|0] "" Vector__XXX
 SG_ ErrorRegister : 16|8@1+ (1,0) [0|0] "" Vector__XXX
 SG_ ErrorCode : 0|16@1+ (1,0) [0|0] "" Vector__XXX

BO_ 137 EMCY_009: 8 Vector__XXX
 SG_ ManufacturerSpecific5 : 56|8@1+ (1,0) [0|0] "" Vector__XXX
 SG_ ManufacturerSpecific4 : 48|8@1+ (1,0) [0|0] "" Vector__XXX
 SG_ ManufacturerSpecific3 : 40|8@1+ (1,0) [0|0] "" Vector__XXX
 SG_ ManufacturerSpecific2 : 32|8@1+ (1,0) [0|0] "" Vector__XXX
 SG_ ManufacturerSpecific1 : 24|8@1+ (1,0) [0|0] "" Vector__XXX
 SG_ ErrorRegister : 16|8@1+ (1,0) [0|0] "" Vector__XXX
 SG_ ErrorCode : 0|16@1+ (1,0) [0|0] "" Vector__XXX

BO_ 136 EMCY_008: 8 Vector__XXX
 SG_ ManufacturerSpecific5 : 56|8@1+ (1,0) [0|0] "" Vector__XXX
 SG_ ManufacturerSpecific4 : 48|8@1+ (1,0) [0|0] "" Vector__XXX
 SG_ ManufacturerSpecific3 : 40|8@1+ (1,0) [0|0] "" Vector__XXX
 SG_ ManufacturerSpecific2 : 32|8@1+ (1,0) [0|0] "" Vector__XXX
 SG_ ManufacturerSpecific1 : 24|8@1+ (1,0) [0|0] "" Vector__XXX
 SG_ ErrorRegister : 16|8@1+ (1,0) [0|0] "" Vector__XXX
 SG_ ErrorCode : 0|16@1+ (1,0) [0|0] "" Vector__XXX

BO_ 135 EMCY_007: 8 Vector__XXX
 SG_ ManufacturerSpecific5 : 56|8@1+ (1,0) [0|0] "" Vector__XXX
 SG_ ManufacturerSpecific4 : 48|8@1+ (1,0) [0|0] "" Vector__XXX
 SG_ ManufacturerSpecific3 : 40|8@1+ (1,0) [0|0] "" Vector__XXX
 SG_ ManufacturerSpecific2 : 32|8@1+ (1,0) [0|0] "" Vector__XXX
 SG_ ManufacturerSpecific1 : 24|8@1+ (1,0) [0|0] "" Vector__XXX
 SG_ ErrorRegister : 16|8@1+ (1,0) [0|0] "" Vector__XXX
 SG_ ErrorCode : 0|16@1+ (1,0) [0|0] "" Vector__XXX

BO_ 134 EMCY_006: 8 Vector__XXX
 SG_ ManufacturerSpecific5 : 56|8@1+ (1,0) [0|0] "" Vector__XXX
 SG_ ManufacturerSpecific4 : 48|8@1+ (1,0) [0|0] "" Vector__XXX
 SG_ ManufacturerSpecific3 : 40|8@1+ (1,0) [0|0] "" Vector__XXX
 SG_ ManufacturerSpecific2 : 32|8@1+ (1,0) [0|0] "" Vector__XXX
 SG_ ManufacturerSpecific1 : 24|8@1+ (1,0) [0|0] "" Vector__XXX
 SG_ ErrorRegister : 16|8@1+ (1,0) [0|0] "" Vector__XXX
 SG_ ErrorCode : 0|16@1+ (1,0) [0|0] "" Vector__XXX

BO_ 133 EMCY_005: 8 Vector__XXX
 SG_ ManufacturerSpecific5 : 56|8@1+ (1,0) [0|0] "" Vector__XXX
 SG_ ManufacturerSpecific4 : 48|8@1+ (1,0) [0|0] "" Vector__XXX
 SG_ ManufacturerSpecific3 : 40|8@1+ (1,0) [0|0] "" Vector__XXX
 SG_ ManufacturerSpecific2 : 32|8@1+ (1,0) [0|0] "" Vector__XXX
 SG_ ManufacturerSpecific1 : 24|8@1+ (1,0) [0|0] "" Vector__XXX
 SG_ ErrorRegister : 16|8@1+ (1,0) [0|0] "" Vector__XXX
 SG_ ErrorCode : 0|16@1+ (1,0) [0|0] "" Vector__XXX

BO_ 132 EMCY_004: 8 Vector__XXX
 SG_ ManufacturerSpecific5 : 56|8@1+ (1,0) [0|0] "" Vector__XXX
 SG_ ManufacturerSpecific4 : 48|8@1+ (1,0) [0|0] "" Vector__XXX
 SG_ ManufacturerSpecific3 : 40|8@1+ (1,0) [0|0] "" Vector__XXX
 SG_ ManufacturerSpecific2 : 32|8@1+ (1,0) [0|0] "" Vector__XXX
 SG_ ManufacturerSpecific1 : 24|8@1+ (1,0) [0|0] "" Vector__XXX
 SG_ ErrorRegister : 16|8@1+ (1,0) [0|0] "" Vector__XXX
 SG_ ErrorCode : 0|16@1+ (1,0) [0|0] "" Vector__XXX

BO_ 131 EMCY_003: 8 Vector__XXX
 SG_ ManufacturerSpecific5 : 56|8@1+ (1,0) [0|0] "" Vector__XXX
 SG_ ManufacturerSpecific4 : 48|8@1+ (1,0) [0|0] "" Vector__XXX
 SG_ ManufacturerSpecific3 : 40|8@1+ (1,0) [0|0] "" Vector__XXX
 SG_ ManufacturerSpecific2 : 32|8@1+ (1,0) [0|0] "" Vector__XXX
 SG_ ManufacturerSpecific1 : 24|8@1+ (1,0) [0|0] "" Vector__XXX
 SG_ ErrorRegister : 16|8@1+ (1,0) [0|0] "" Vector__XXX
 SG_ ErrorCode : 0|16@1+ (1,0) [0|0] "" Vector__XXX

BO_ 130 EMCY_002: 8 Vector__XXX
 SG_ ManufacturerSpecific5 : 56|8@1+ (1,0) [0|0] "" Vector__XXX
 SG_ ManufacturerSpecific4 : 48|8@1+ (1,0) [0|0] "" Vector__XXX
 SG_ ManufacturerSpecific3 : 40|8@1+ (1,0) [0|0] "" Vector__XXX
 SG_ ManufacturerSpecific2 : 32|8@1+ (1,0) [0|0] "" Vector__XXX
 SG_ ManufacturerSpecific1 : 24|8@1+ (1,0) [0|0] "" Vector__XXX
 SG_ ErrorRegister : 16|8@1+ (1,0) [0|0] "" Vector__XXX
 SG_ ErrorCode : 0|16@1+ (1,0) [0|0] "" Vector__XXX

BO_ 129 EMCY_001: 8 Vector__XXX
 SG_ ManufacturerSpecific5 : 56|8@1+ (1,0) [0|0] "" Vector__XXX
 SG_ ManufacturerSpecific4 : 48|8@1+ (1,0) [0|0] "" Vector__XXX
 SG_ ManufacturerSpecific3 : 40|8@1+ (1,0) [0|0] "" Vector__XXX
 SG_ ManufacturerSpecific2 : 32|8@1+ (1,0) [0|0] "" Vector__XXX
 SG_ ManufacturerSpecific1 : 24|8@1+ (1,0) [0|0] "" Vector__XXX
 SG_ ErrorRegister : 16|8@1+ (1,0) [0|0] "" Vector__XXX
 SG_ ErrorCode : 0|16@1+ (1,0) [0|0] "" Vector__XXX

BO_ 128 SYNC: 0 Vector__XXX

BO_ 0 NMTZeroMsg: 2 NMTMaster
 SG_ Node_ID : 8|8@1+ (1,0) [0|0] "" Vector__XXX
 SG_ CS : 0|8@1+ (1,0) [0|0] "" Vector__XXX

BO_ 2632711934 TPDT: 8 Vector__XXX
 SG_ nrSeq : 0|8@1+ (1,0) [1|255] "" Vector__XXX
 SG_ dataPktizdByt : 8|56@1+ (1,0) [1|1.15292150460684E+18] "" Vector__XXX

BO_ 2632777470 TPCM: 8 Vector__XXX
 SG_ stCtrlByt : 0|8@1+ (1,0) [0|255] "" Vector__XXX
 SG_ nrTotMsgSize : 8|16@1+ (1,0) [9|1785] "" Vector__XXX
 SG_ nrTotPkts : 24|8@1+ (1,0) [2|255] "" Vector__XXX
 SG_ nrPgn : 40|24@1+ (1,0) [0|16777200] "" Vector__XXX

BO_ 2566839038 SOFT: 8 Vector__XXX
 SG_ nrSwIdnFields : 0|8@1+ (1,0) [0|250] "steps" Vector__XXX
 SG_ dataSwIdn : 8|8@1+ (1,0) [0|255] "per byte" Vector__XXX

BO_ 2565537534 RQST: 3 Vector__XXX
 SG_ nrPgn : 0|24@1+ (1,0) [0|16777215] "" Vector__XXX

BO_ 2565868035 RngChkPrm: 32 Vector__XXX
 SG_ stErrDetnRngChkPrm0 : 0|32@1+ (1,0) [0|4294967295] "" Vector__XXX
 SG_ stErrDetnRngChkPrm1 : 32|32@1+ (1,0) [0|4294967295] "" Vector__XXX
 SG_ stErrDetnRngChkPrm2 : 64|32@1+ (1,0) [0|4294967295] "" Vector__XXX
 SG_ stErrDetnRngChkPrm3 : 96|32@1+ (1,0) [0|4294967295] "" Vector__XXX
 SG_ stErrDetnRngChkPrm4 : 128|32@1+ (1,0) [0|4294967295] "" Vector__XXX
 SG_ stErrDetnRngChkPrm5 : 160|32@1+ (1,0) [0|4294967295] "" Vector__XXX
 SG_ stErrDetnRngChkPrm6 : 192|32@1+ (1,0) [0|4294967295] "" Vector__XXX
 SG_ stErrDetnRngChkPrm7 : 224|32@1+ (1,0) [0|4294967295] "" Vector__XXX

BO_ 2565868291 RngChkInp: 32 Vector__XXX
 SG_ stErrDetnRngChkInpSig0 : 0|32@1+ (1,0) [0|4294967295] "" Vector__XXX
 SG_ stErrDetnRngChkInpSig1 : 32|32@1+ (1,0) [0|4294967295] "" Vector__XXX
 SG_ stErrDetnRngChkInpSig2 : 64|32@1+ (1,0) [0|4294967295] "" Vector__XXX
 SG_ stErrDetnRngChkInpSig3 : 96|32@1+ (1,0) [0|4294967295] "" Vector__XXX
 SG_ stErrDetnRngChkInpSig4 : 128|32@1+ (1,0) [0|4294967295] "" Vector__XXX
 SG_ stErrDetnRngChkInpSig5 : 160|32@1+ (1,0) [0|4294967295] "" Vector__XXX
 SG_ stErrDetnRngChkInpSig6 : 192|32@1+ (1,0) [0|4294967295] "" Vector__XXX
 SG_ stErrDetnRngChkInpSig7 : 224|32@1+ (1,0) [0|4294967295] "" Vector__XXX

BO_ 2559835902 NM: 8 Vector__XXX
 SG_ stChecksErrCod : 0|8@1+ (1,0) [0|5] "" Vector__XXX
 SG_ flgMnfcCodQlfr : 8|1@1+ (1,0) [0|1] "" Vector__XXX
 SG_ flgEcuInstQlfr : 9|1@1+ (1,0) [0|1] "" Vector__XXX
 SG_ flgFctInstQlfr : 10|1@1+ (1,0) [0|1] "" Vector__XXX
 SG_ flgFctQlfr : 11|1@1+ (1,0) [0|1] "" Vector__XXX
 SG_ flgVehSysQlfr : 12|1@1+ (1,0) [0|1] "" Vector__XXX
 SG_ flgVehSysInstQlfr : 13|1@1+ (1,0) [0|1] "" Vector__XXX
 SG_ flgIndtryGroupQlfr : 14|1@1+ (1,0) [0|1] "" Vector__XXX
 SG_ flgArbitraryAdrCapableQlfr : 15|1@1+ (1,0) [0|1] "" Vector__XXX
 SG_ stNameMngtCtrlModIndcr : 16|4@1+ (1,0) [0|15] "" Vector__XXX
 SG_ dataCmddMnfcCod : 21|11@1+ (1,0) [0|2047] "" Vector__XXX
 SG_ dataCmddEcuInst : 32|3@1+ (1,0) [0|7] "" Vector__XXX
 SG_ dataCmddFctInst : 35|5@1+ (1,0) [0|31] "" Vector__XXX
 SG_ dataCmddFct : 40|8@1+ (1,0) [0|255] "" Vector__XXX
 SG_ dataCmddVehSys : 49|7@1+ (1,0) [0|127] "" Vector__XXX
 SG_ dataCmddVehSysInst : 56|4@1+ (1,0) [0|15] "" Vector__XXX
 SG_ dataCmddIndtryGroup : 60|3@1+ (1,0) [0|7] "" Vector__XXX
 SG_ flgCmddArbitraryAdrCapable : 63|1@1+ (1,0) [0|1] "" Vector__XXX

BO_ 2630352638 ETPDT: 8 Vector__XXX
 SG_ nrSeq : 0|8@1+ (1,0) [1|255] "" Vector__XXX
 SG_ dataPktizdByt : 8|56@1+ (1,0) [1|1.15292150460684E+18] "" Vector__XXX

BO_ 2630418174 ETPCM: 8 Vector__XXX
 SG_ stCtrlByt : 0|8@1+ (1,0) [0|255] "" Vector__XXX
 SG_ nrTotMsgSize : 8|24@1+ (1,0) [1786|117440505] "" Vector__XXX
 SG_ nrPgn : 40|24@1+ (1,0) [0|16777200] "" Vector__XXX

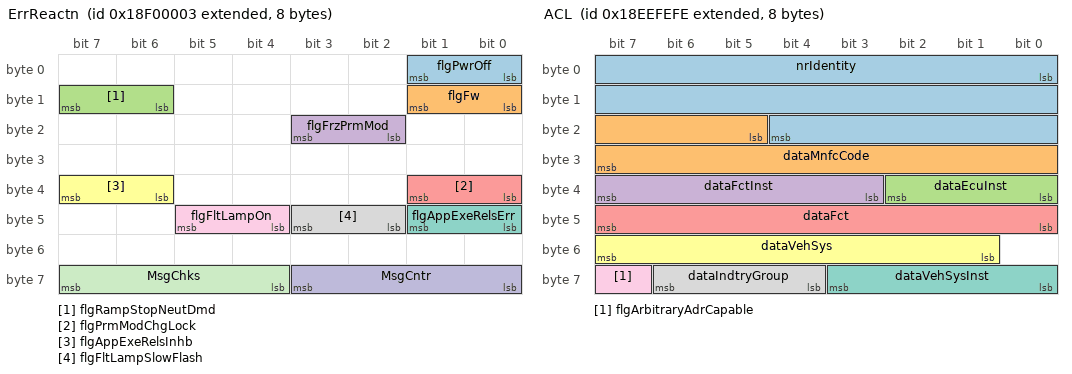
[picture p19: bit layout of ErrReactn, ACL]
BO_ 2565865475 ErrReactn: 8 Vector__XXX
 SG_ flgPwrOff : 0|2@1+ (1,0) [0|1] "" Vector__XXX
 SG_ flgFw : 8|2@1+ (1,0) [0|1] "" Vector__XXX
 SG_ flgRampStopNeutDmd : 14|2@1+ (1,0) [0|1] "" Vector__XXX
 SG_ flgFrzPrmMod : 18|2@1+ (1,0) [0|1] "" Vector__XXX
 SG_ flgPrmModChgLock : 32|2@1+ (1,0) [0|1] "" Vector__XXX
 SG_ flgAppExeRelsInhb : 38|2@1+ (1,0) [0|1] "" Vector__XXX
 SG_ flgAppExeRelsErr : 40|2@1+ (1,0) [0|1] "" Vector__XXX
 SG_ flgFltLampSlowFlash : 42|2@1+ (1,0) [0|1] "" Vector__XXX
 SG_ flgFltLampOn : 44|2@1+ (1,0) [0|1] "" Vector__XXX
 SG_ MsgCntr : 56|4@1+ (1,0) [0|15] "" Vector__XXX
 SG_ MsgChks : 60|4@1+ (1,0) [0|15] "" Vector__XXX

BO_ 2566768126 ECUID: 8 Vector__XXX
 SG_ nrEcuPart : 0|8@1+ (1,0) [0|255] "per byte" Vector__XXX
 SG_ nrEcuSerl : 8|8@1+ (1,0) [0|255] "per byte" Vector__XXX
 SG_ dataEcuLocn : 16|8@1+ (1,0) [0|255] "per byte" Vector__XXX
 SG_ stEcuTyp : 24|8@1+ (1,0) [0|255] "per byte" Vector__XXX

BO_ 2566835198 DM2: 22 Vector__XXX
 SG_ stProtLamp : 0|2@1+ (1,0) [0|3] "" Vector__XXX
 SG_ stAmberWarnLamp : 2|2@1+ (1,0) [0|3] "" Vector__XXX
 SG_ stRedStopLamp : 4|2@1+ (1,0) [0|3] "" Vector__XXX
 SG_ stMalfctIndcrLamp : 6|2@1+ (1,0) [0|3] "" Vector__XXX
 SG_ stFlashProtLamp : 8|2@1+ (1,0) [0|3] "" Vector__XXX
 SG_ stFlashAmberWarnLamp : 10|2@1+ (1,0) [0|3] "" Vector__XXX
 SG_ stFlashRedStopLamp : 12|2@1+ (1,0) [0|3] "" Vector__XXX
 SG_ stFlashMalfcIndcrLamp : 14|2@1+ (1,0) [0|3] "" Vector__XXX
 SG_ DTC1 : 16|32@1+ (1,0) [0|4294967295] "" Vector__XXX
 SG_ DTC2 : 48|32@1+ (1,0) [0|4294967295] "" Vector__XXX
 SG_ DTC3 : 80|32@1+ (1,0) [0|4294967295] "" Vector__XXX
 SG_ DTC4 : 112|32@1+ (1,0) [0|4294967295] "" Vector__XXX
 SG_ DTC5 : 144|32@1+ (1,0) [0|4294967295] "" Vector__XXX

BO_ 2564816638 DM13: 8 Vector__XXX
 SG_ stStopStrtCurDataLnk : 6|2@1+ (1,0) [0|3] "" Vector__XXX
 SG_ stHldSig : 28|4@1+ (1,0) [0|15] "" Vector__XXX

BO_ 2566834942 DM1: 22 Vector__XXX
 SG_ stProtLamp : 0|2@1+ (1,0) [0|3] "" Vector__XXX
 SG_ stAmberWarnLamp : 2|2@1+ (1,0) [0|3] "" Vector__XXX
 SG_ stRedStopLamp : 4|2@1+ (1,0) [0|3] "" Vector__XXX
 SG_ stMalfctIndcrLamp : 6|2@1+ (1,0) [0|3] "" Vector__XXX
 SG_ stFlashProtLamp : 8|2@1+ (1,0) [0|3] "" Vector__XXX
 SG_ stFlashAmberWarnLamp : 10|2@1+ (1,0) [0|3] "" Vector__XXX
 SG_ stFlashRedStopLamp : 12|2@1+ (1,0) [0|3] "" Vector__XXX
 SG_ stFlashMalfcIndcrLamp : 14|2@1+ (1,0) [0|3] "" Vector__XXX
 SG_ DTC1 : 16|32@1+ (1,0) [0|4294967295] "" Vector__XXX
 SG_ DTC2 : 48|32@1+ (1,0) [0|4294967295] "" Vector__XXX
 SG_ DTC3 : 80|32@1+ (1,0) [0|4294967295] "" Vector__XXX
 SG_ DTC4 : 112|32@1+ (1,0) [0|4294967295] "" Vector__XXX
 SG_ DTC5 : 144|32@1+ (1,0) [0|4294967295] "" Vector__XXX

BO_ 2566838526 CA: 9 Vector__XXX
 SG_ nrIdentity : 0|21@1+ (1,0) [0|2097151] "" Vector__XXX
 SG_ dataMnfcCode : 21|11@1+ (1,0) [0|2047] "" Vector__XXX
 SG_ dataEcuInst : 32|3@1+ (1,0) [0|7] "" Vector__XXX
 SG_ dataFctInst : 35|5@1+ (1,0) [0|31] "" Vector__XXX
 SG_ dataFct : 40|8@1+ (1,0) [0|255] "" Vector__XXX
 SG_ dataVehSys : 49|7@1+ (1,0) [0|127] "" Vector__XXX
 SG_ dataVehSysInst : 56|4@1+ (1,0) [0|15] "" Vector__XXX
 SG_ dataIndtryGroup : 60|3@1+ (1,0) [0|7] "" Vector__XXX
 SG_ flgArbitraryAdrCapable : 63|1@1+ (1,0) [0|1] "" Vector__XXX
 SG_ adrSrcNew : 64|8@1+ (1,0) [0|253] "" Vector__XXX

BO_ 2565799678 ACL: 8 Vector__XXX
 SG_ nrIdentity : 0|21@1+ (1,0) [0|2097151] "" Vector__XXX
 SG_ dataMnfcCode : 21|11@1+ (1,0) [0|2047] "" Vector__XXX
 SG_ dataEcuInst : 32|3@1+ (1,0) [0|7] "" Vector__XXX
 SG_ dataFctInst : 35|5@1+ (1,0) [0|31] "" Vector__XXX
 SG_ dataFct : 40|8@1+ (1,0) [0|255] "" Vector__XXX
 SG_ dataVehSys : 49|7@1+ (1,0) [0|127] "" Vector__XXX
 SG_ dataVehSysInst : 56|4@1+ (1,0) [0|15] "" Vector__XXX
 SG_ dataIndtryGroup : 60|3@1+ (1,0) [0|7] "" Vector__XXX
 SG_ flgArbitraryAdrCapable : 63|1@1+ (1,0) [0|1] "" Vector__XXX

BO_ 2565406462 ACKM: 8 Vector__XXX
 SG_ stCtrlByt : 0|8@1+ (1,0) [0|3] "" Vector__XXX
 SG_ stGroupFctVal : 8|8@1+ (1,0) [0|250] "" Vector__XXX
 SG_ adrAckd : 32|8@1+ (1,0) [0|255] "" Vector__XXX
 SG_ nrPgn : 40|24@1+ (1,0) [0|16777200] "" Vector__XXX

CM_ SG_ 2632711934 dataPktizdByt "Packetized Data (7 bytes).";
CM_ SG_ 2632777470 stCtrlByt "Control Byte specifiying kind of connection management message. See SAE J1939-21.";
CM_ SG_ 2632777470 nrTotMsgSize "Number of bytes to be transmitted. See SAE J1939-21.";
CM_ SG_ 2632777470 nrTotPkts "Total Number of Packets. See SAE J1939-21.";
CM_ SG_ 2632777470 nrPgn "Parameter Group Number of the packeted message. See SAE J1939-21.";
CM_ SG_ 2566839038 nrSwIdnFields "Number of software identification designators represented in the software identification parameter group";
CM_ SG_ 2566839038 dataSwIdn "Software identification of an electronic module. As an example, this parameter may be represented with ASCII characters MMDDYYaa where MM is the month, DD is the day, YY is the year, and aa is the revision number.";
CM_ SG_ 2565537534 nrPgn "Parameter Group Number of the packeted message. See SAE J1939-21.";
CM_ SG_ 2565868035 stErrDetnRngChkPrm0 "Parameter range check bits of all used functions components (Array 0)";
CM_ SG_ 2565868035 stErrDetnRngChkPrm1 "Parameter range check bits of all used functions components (Array 1)";
CM_ SG_ 2565868035 stErrDetnRngChkPrm2 "Parameter range check bits of all used functions components (Array 2)";
CM_ SG_ 2565868035 stErrDetnRngChkPrm3 "Parameter range check bits of all used functions components (Array 3)";
CM_ SG_ 2565868035 stErrDetnRngChkPrm4 "Parameter range check bits of all used functions components (Array 4)";
CM_ SG_ 2565868035 stErrDetnRngChkPrm5 "Parameter range check bits of all used functions components (Array 5)";
CM_ SG_ 2565868035 stErrDetnRngChkPrm6 "Parameter range check bits of all used functions components (Array 6)";
CM_ SG_ 2565868035 stErrDetnRngChkPrm7 "Parameter range check bits of all used functions components (Array 7)";
CM_ SG_ 2565868291 stErrDetnRngChkInpSig0 "Input range check bits of all used functions components (Array 0)";
CM_ SG_ 2565868291 stErrDetnRngChkInpSig1 "Input range check bits of all used functions components (Array 1)";
CM_ SG_ 2565868291 stErrDetnRngChkInpSig2 "Input range check bits of all used functions components (Array 2)";
CM_ SG_ 2565868291 stErrDetnRngChkInpSig3 "Input range check bits of all used functions components (Array 3)";
CM_ SG_ 2565868291 stErrDetnRngChkInpSig4 "Input range check bits of all used functions components (Array 4)";
CM_ SG_ 2565868291 stErrDetnRngChkInpSig5 "Input range check bits of all used functions components (Array 5)";
CM_ SG_ 2565868291 stErrDetnRngChkInpSig6 "Input range check bits of all used functions components (Array 6)";
CM_ SG_ 2565868291 stErrDetnRngChkInpSig7 "Input range check bits of all used functions components (Array 7)";
CM_ SG_ 2559835902 stChecksErrCod "NAME Checksum or error code depending on mode, see SAE J1939-81 chapter 4.6.2.2.1.";
CM_ SG_ 2559835902 flgMnfcCodQlfr "Manufacturer Code qualifier flag, see SAE J1939-81 chapter 4.6.2.2.2.";
CM_ SG_ 2559835902 flgEcuInstQlfr "ECU Instance qualifier flag, see SAE J1939-81 chapter 4.6.2.2.3.";
CM_ SG_ 2559835902 flgFctInstQlfr "Function Instance qualifier flag, see SAE J1939-81 chapter 4.6.2.2.4.";
CM_ SG_ 2559835902 flgFctQlfr "Function qualifier flag, see SAE J1939-81 chapter 4.6.2.2.5.";
CM_ SG_ 2559835902 flgVehSysQlfr "Vehicle system qualifier flag, see SAE J1939-81 chapter 4.6.2.2.6.";
CM_ SG_ 2559835902 flgVehSysInstQlfr "Vehicle system Instance qualifier flag, see SAE J1939-81 chapter 4.6.2.2.7.";
CM_ SG_ 2559835902 flgIndtryGroupQlfr "Industry group qualifier flag, see SAE J1939-81 chapter 4.6.2.2.8.";
CM_ SG_ 2559835902 flgArbitraryAdrCapableQlfr "Arbitrary Address Capable qualifier flag, see SAE J1939-81 chapter 4.6.2.2.9.";
CM_ SG_ 2559835902 stNameMngtCtrlModIndcr "This four bit parameter is used to define the purpose of the NM message. See SAE J1939-81 chapter 4.6.2.2.10.";
CM_ SG_ 2559835902 dataCmddMnfcCod "See SAE J1939-81 chapter 4.6.2.2.11.";
CM_ SG_ 2559835902 dataCmddEcuInst "See SAE J1939-81 chapter 4.6.2.2.12.";
CM_ SG_ 2559835902 dataCmddFctInst "See SAE J1939-81 chapter 4.6.2.2.13.";
CM_ SG_ 2559835902 dataCmddFct "See SAE J1939-81 chapter 4.6.2.2.14.";
CM_ SG_ 2559835902 dataCmddVehSys "See SAE J1939-81 chapter 4.6.2.2.15.";
CM_ SG_ 2559835902 dataCmddVehSysInst "See SAE J1939-81 chapter 4.6.2.2.16.";
CM_ SG_ 2559835902 dataCmddIndtryGroup "See SAE J1939-81 chapter 4.6.2.2.17.";
CM_ SG_ 2559835902 flgCmddArbitraryAdrCapable "See SAE J1939-81 chapter 4.6.2.2.18.";
CM_ SG_ 2630352638 dataPktizdByt "Packetized Data (7 bytes).";
CM_ SG_ 2630418174 stCtrlByt "Control Byte specifiying kind of connection management message. See SAE J1939-21.";
CM_ SG_ 2630418174 nrTotMsgSize "Number of bytes to be transmitted. See SAE J1939-21.";
CM_ SG_ 2630418174 nrPgn "Parameter Group Number of the packeted message. See SAE J1939-21.";
CM_ SG_ 2565865475 flgPwrOff "Error reaction - Emergency power off";
CM_ SG_ 2565865475 flgFw "Error reaction - Free wheeling";
CM_ SG_ 2565865475 flgRampStopNeutDmd "Error reaction - Ramp stop via neutral drive demand";
CM_ SG_ 2565865475 flgFrzPrmMod "Error reaction - Freeze drive mode";
CM_ SG_ 2565865475 flgPrmModChgLock "Error reaction - Drive mode change lock";
CM_ SG_ 2565865475 flgAppExeRelsInhb "Error reaction - Start lock that prevents vehicle movement during power on";
CM_ SG_ 2565865475 flgAppExeRelsErr "Error reaction - Inhibit first appl power on condition";
CM_ SG_ 2565865475 flgFltLampSlowFlash "Error reaction - No reaction executed, Fault Lamp slow flashing";
CM_ SG_ 2565865475 flgFltLampOn "Error reaction - No reaction executed, Fault Lamp on";
CM_ SG_ 2565865475 MsgCntr "The message counter is used to detect situations where the transmitting ECU repeats the same frame all the time. The receiver may use the counter parameter to detect this situation. The transmitting device will increase the message counter in every cycle.";
CM_ SG_ 2565865475 MsgChks "The message checksum is used to verify the signal path from the transmitting device to the receiving device.";
CM_ SG_ 2566768126 nrEcuPart "The part number of the physical ECU.";
CM_ SG_ 2566768126 nrEcuSerl "The serial number of the physical ECU.";
CM_ SG_ 2566768126 dataEcuLocn "The location of the ECU within a network.";
CM_ SG_ 2566768126 stEcuTyp "The type of ECU. One example of a use of the ECU type could be for classifying ECU capabilities, such as I/O.";
CM_ SG_ 2566835198 stProtLamp "This lamp is used to relay trouble code information that is reporting a problem with a vehicle system that is most probably not electronic subsystem related";
CM_ SG_ 2566835198 stAmberWarnLamp "This lamp is used to relay trouble code information that is reporting a problem with the vehicle system but the vehicle need not be immediately stopped";
CM_ SG_ 2566835198 stRedStopLamp "This lamp is used to relay trouble code information that is of a severe enought condition that it warrants stopping the vehicle";
CM_ SG_ 2566835198 stMalfctIndcrLamp "A lamp used to relay only emissions-related trouble code information";
CM_ SG_ 2566835198 stFlashProtLamp "This parameter provides the capability to flash the engine protect lamp (SPN 3041)";
CM_ SG_ 2566835198 stFlashAmberWarnLamp "This parameter provides the capability to flash the AWL (SPN 3040)";
CM_ SG_ 2566835198 stFlashRedStopLamp "This parameter provides the capability to flash the RSL (SPN 3039)";
CM_ SG_ 2566835198 stFlashMalfcIndcrLamp "This parameter provides the capability to flash the MIL (SPN 3038)";
CM_ SG_ 2566835198 DTC1 "Diagnostic Trouble Code";
CM_ SG_ 2566835198 DTC2 "Diagnostic Trouble Code";
CM_ SG_ 2566835198 DTC3 "Diagnostic Trouble Code";
CM_ SG_ 2566835198 DTC4 "Diagnostic Trouble Code";
CM_ SG_ 2566835198 DTC5 "Diagnostic Trouble Code";
CM_ SG_ 2564816638 stStopStrtCurDataLnk "Identifies the action to be performed on the communications port that this parameter was received on:01b = Stop Broadcast,10b = Start Broadcast";
CM_ SG_ 2564816638 stHldSig "Indicator to all nodes that the communication ports that have been acted upon by the “Stop Start Broadcast” PGN are remaining in the modified state.0000b = All Devices,0001b = Devices whose broadcast state has been modified";
CM_ SG_ 2566834942 stProtLamp "This lamp is used to relay trouble code information that is reporting a problem with a vehicle system that is most probably not electronic subsystem related";
CM_ SG_ 2566834942 stAmberWarnLamp "This lamp is used to relay trouble code information that is reporting a problem with the vehicle system but the vehicle need not be immediately stopped";
CM_ SG_ 2566834942 stRedStopLamp "This lamp is used to relay trouble code information that is of a severe enought condition that it warrants stopping the vehicle";
CM_ SG_ 2566834942 stMalfctIndcrLamp "A lamp used to relay only emissions-related trouble code information";
CM_ SG_ 2566834942 stFlashProtLamp "This parameter provides the capability to flash the engine protect lamp (SPN 3041)";
CM_ SG_ 2566834942 stFlashAmberWarnLamp "This parameter provides the capability to flash the AWL (SPN 3040)";
CM_ SG_ 2566834942 stFlashRedStopLamp "This parameter provides the capability to flash the RSL (SPN 3039)";
CM_ SG_ 2566834942 stFlashMalfcIndcrLamp "This parameter provides the capability to flash the MIL (SPN 3038)";
CM_ SG_ 2566834942 DTC1 "Diagnostic Trouble Code";
CM_ SG_ 2566834942 DTC2 "Diagnostic Trouble Code";
CM_ SG_ 2566834942 DTC3 "Diagnostic Trouble Code";
CM_ SG_ 2566834942 DTC4 "Diagnostic Trouble Code";
CM_ SG_ 2566834942 DTC5 "Diagnostic Trouble Code";
CM_ SG_ 2566838526 nrIdentity "Part of the NAME of Commanded Address Target";
CM_ SG_ 2566838526 dataMnfcCode "Part of the NAME of Commanded Address Target";
CM_ SG_ 2566838526 dataEcuInst "Part of the NAME of Commanded Address Target";
CM_ SG_ 2566838526 dataFctInst "Part of the NAME of Commanded Address Target";
CM_ SG_ 2566838526 dataFct "Part of the NAME of Commanded Address Target";
CM_ SG_ 2566838526 dataVehSys "Part of the NAME of Commanded Address Target";
CM_ SG_ 2566838526 dataVehSysInst "Part of the NAME of Commanded Address Target";
CM_ SG_ 2566838526 dataIndtryGroup "Part of the NAME of Commanded Address Target";
CM_ SG_ 2566838526 flgArbitraryAdrCapable "Part of the NAME of Commanded Address Target";
CM_ SG_ 2566838526 adrSrcNew "It contains the source address that is to be assigned to the CA matching the NAME conveyed in the first eight bytes of this Commanded Address message.";
CM_ SG_ 2565799678 nrIdentity "Part of the 8-byte Value which uniquely identifies the particular CA that is claiming the associated address.";
CM_ SG_ 2565799678 dataMnfcCode "Part of the 8-byte Value which uniquely identifies the particular CA that is claiming the associated address.";
CM_ SG_ 2565799678 dataEcuInst "Part of the 8-byte Value which uniquely identifies the particular CA that is claiming the associated address.";
CM_ SG_ 2565799678 dataFctInst "Part of the 8-byte Value which uniquely identifies the particular CA that is claiming the associated address.";
CM_ SG_ 2565799678 dataFct "Part of the 8-byte Value which uniquely identifies the particular CA that is claiming the associated address.";
CM_ SG_ 2565799678 dataVehSys "Part of the 8-byte Value which uniquely identifies the particular CA that is claiming the associated address.";
CM_ SG_ 2565799678 dataVehSysInst "Part of the 8-byte Value which uniquely identifies the particular CA that is claiming the associated address.";
CM_ SG_ 2565799678 dataIndtryGroup "Part of the 8-byte Value which uniquely identifies the particular CA that is claiming the associated address.";
CM_ SG_ 2565799678 flgArbitraryAdrCapable "Part of the 8-byte Value which uniquely identifies the particular CA that is claiming the associated address.";
CM_ SG_ 2565406462 stCtrlByt "Control byte = 0, Positive Acknowledgment (ACK);Control byte = 1, Negative Acknowledgment (NACK);Control byte = 2, Access Denied;Control byte = 3, Cannot Respond;See SAE J1939-21 chapter 5.4.4";
CM_ SG_ 2565406462 stGroupFctVal "Group Function Value, see SAE J1939-21 chapter 5.4.4.";
CM_ SG_ 2565406462 adrAckd "Address of acknowledgment depending on Control Byte.";
CM_ SG_ 2565406462 nrPgn "Parameter Group Number of the acknowledged message (depending on ControlByte). See SAE J1939-21.";

BA_DEF_ BO_ "GenMsgSendType" ENUM "cyclic","NotUsed","NotUsed","NotUsed","NotUsed","NotUsed","NotUsed","IfActive","noMsgSendType";
BA_DEF_ BO_ "VFrameFormat" ENUM "StandardCAN","ExtendedCAN","reserved","J1939PG";
BA_DEF_ BO_ "GenMsgRequestable" INT 0 1;
BA_DEF_ BO_ "MsgCntrChksSuprtd" INT 0 3;
BA_DEF_ SG_ "SPN" INT 0 524287;
BA_DEF_ SG_ "SigType" ENUM "Default","Range","RangeSigned","ASCII","Discrete","Control","ReferencePGN","DTC","StringDelimiter","StringLength","StringLengthControl";
BA_DEF_ "IsCANopen" INT 0 1;
BA_DEF_ "GeneratedBy" STRING;
BA_DEF_ "AUTOGENERATION" INT 0 1;
BA_DEF_ "ProtocolType" STRING;
BA_DEF_ "BusType" STRING;

BA_DEF_DEF_ "GenMsgSendType" "noMsgSendType";
BA_DEF_DEF_ "VFrameFormat" "StandardCAN";
BA_DEF_DEF_ "GenMsgRequestable" 1;
BA_DEF_DEF_ "MsgCntrChksSuprtd" 0;
BA_DEF_DEF_ "SPN" 0;
BA_DEF_DEF_ "SigType" "Default";
BA_DEF_DEF_ "IsCANopen" 0;
BA_DEF_DEF_ "GeneratedBy" "";
BA_DEF_DEF_ "AUTOGENERATION" 0;
BA_DEF_DEF_ "ProtocolType" "";
BA_DEF_DEF_ "BusType" "";

BA_ "IsCANopen" 1;
BA_ "GeneratedBy" "Vector ProCANopen";
BA_ "AUTOGENERATION" 1;
BA_ "ProtocolType" "J1939";
BA_ "BusType" "CAN";
BA_ "GenMsgSendType" BO_ 2632711934 7;
BA_ "VFrameFormat" BO_ 2632711934 3;
BA_ "SPN" SG_ 2632711934 nrSeq 2572;
BA_ "SPN" SG_ 2632711934 dataPktizdByt 2573;
BA_ "GenMsgSendType" BO_ 2632777470 7;
BA_ "VFrameFormat" BO_ 2632777470 3;
BA_ "SPN" SG_ 2632777470 stCtrlByt 2556;
BA_ "SigType" SG_ 2632777470 stCtrlByt 5;
BA_ "SPN" SG_ 2632777470 nrTotMsgSize 2557;
BA_ "SPN" SG_ 2632777470 nrTotPkts 2558;
BA_ "SPN" SG_ 2632777470 nrPgn 2560;
BA_ "SigType" SG_ 2632777470 nrPgn 6;
BA_ "VFrameFormat" BO_ 2566839038 3;
BA_ "SPN" SG_ 2566839038 nrSwIdnFields 965;
BA_ "SigType" SG_ 2566839038 nrSwIdnFields 1;
BA_ "SPN" SG_ 2566839038 dataSwIdn 234;
BA_ "SigType" SG_ 2566839038 dataSwIdn 8;
BA_ "GenMsgSendType" BO_ 2565537534 7;
BA_ "VFrameFormat" BO_ 2565537534 3;
BA_ "SPN" SG_ 2565537534 nrPgn 2560;
BA_ "SigType" SG_ 2565537534 nrPgn 6;
BA_ "VFrameFormat" BO_ 2565868035 3;
BA_ "VFrameFormat" BO_ 2565868291 3;
BA_ "GenMsgSendType" BO_ 2559835902 7;
BA_ "VFrameFormat" BO_ 2559835902 3;
BA_ "SPN" SG_ 2559835902 stChecksErrCod 5657;
BA_ "SigType" SG_ 2559835902 stChecksErrCod 1;
BA_ "SPN" SG_ 2559835902 flgMnfcCodQlfr 5658;
BA_ "SPN" SG_ 2559835902 flgEcuInstQlfr 5659;
BA_ "SPN" SG_ 2559835902 flgFctInstQlfr 5660;
BA_ "SPN" SG_ 2559835902 flgFctQlfr 5661;
BA_ "SPN" SG_ 2559835902 flgVehSysQlfr 5662;
BA_ "SPN" SG_ 2559835902 flgVehSysInstQlfr 5663;
BA_ "SPN" SG_ 2559835902 flgIndtryGroupQlfr 5664;
BA_ "SPN" SG_ 2559835902 flgArbitraryAdrCapableQlfr 5665;
BA_ "SPN" SG_ 2559835902 stNameMngtCtrlModIndcr 5666;
BA_ "SPN" SG_ 2559835902 dataCmddMnfcCod 5667;
BA_ "SPN" SG_ 2559835902 dataCmddEcuInst 5668;
BA_ "SPN" SG_ 2559835902 dataCmddFctInst 5669;
BA_ "SPN" SG_ 2559835902 dataCmddFct 5670;
BA_ "SPN" SG_ 2559835902 dataCmddVehSys 5671;
BA_ "SPN" SG_ 2559835902 dataCmddVehSysInst 5672;
BA_ "SPN" SG_ 2559835902 dataCmddIndtryGroup 5673;
BA_ "SPN" SG_ 2559835902 flgCmddArbitraryAdrCapable 5674;
BA_ "GenMsgSendType" BO_ 2630352638 7;
BA_ "VFrameFormat" BO_ 2630352638 3;
BA_ "SPN" SG_ 2630352638 nrSeq 2572;
BA_ "SPN" SG_ 2630352638 dataPktizdByt 2573;
BA_ "GenMsgSendType" BO_ 2630418174 7;
BA_ "VFrameFormat" BO_ 2630418174 3;
BA_ "SPN" SG_ 2630418174 stCtrlByt 2556;
BA_ "SigType" SG_ 2630418174 stCtrlByt 5;
BA_ "SPN" SG_ 2630418174 nrTotMsgSize 2557;
BA_ "SPN" SG_ 2630418174 nrPgn 2560;
BA_ "SigType" SG_ 2630418174 nrPgn 6;
BA_ "GenMsgSendType" BO_ 2565865475 7;
BA_ "VFrameFormat" BO_ 2565865475 3;
BA_ "MsgCntrChksSuprtd" BO_ 2565865475 1;
BA_ "SPN" SG_ 2565865475 MsgCntr 4206;
BA_ "SPN" SG_ 2565865475 MsgChks 4207;
BA_ "VFrameFormat" BO_ 2566768126 3;
BA_ "SPN" SG_ 2566768126 nrEcuPart 2901;
BA_ "SigType" SG_ 2566768126 nrEcuPart 8;
BA_ "SPN" SG_ 2566768126 nrEcuSerl 2902;
BA_ "SigType" SG_ 2566768126 nrEcuSerl 8;
BA_ "SPN" SG_ 2566768126 dataEcuLocn 2903;
BA_ "SigType" SG_ 2566768126 dataEcuLocn 8;
BA_ "SPN" SG_ 2566768126 stEcuTyp 2904;
BA_ "SigType" SG_ 2566768126 stEcuTyp 8;
BA_ "GenMsgSendType" BO_ 2566835198 7;
BA_ "VFrameFormat" BO_ 2566835198 3;
BA_ "SPN" SG_ 2566835198 stProtLamp 987;
BA_ "SigType" SG_ 2566835198 stProtLamp 4;
BA_ "SPN" SG_ 2566835198 stAmberWarnLamp 624;
BA_ "SigType" SG_ 2566835198 stAmberWarnLamp 4;
BA_ "SPN" SG_ 2566835198 stRedStopLamp 623;
BA_ "SigType" SG_ 2566835198 stRedStopLamp 4;
BA_ "SPN" SG_ 2566835198 stMalfctIndcrLamp 1213;
BA_ "SigType" SG_ 2566835198 stMalfctIndcrLamp 4;
BA_ "SPN" SG_ 2566835198 stFlashProtLamp 3041;
BA_ "SigType" SG_ 2566835198 stFlashProtLamp 4;
BA_ "SPN" SG_ 2566835198 stFlashAmberWarnLamp 3040;
BA_ "SigType" SG_ 2566835198 stFlashAmberWarnLamp 4;
BA_ "SPN" SG_ 2566835198 stFlashRedStopLamp 3039;
BA_ "SigType" SG_ 2566835198 stFlashRedStopLamp 4;
BA_ "SPN" SG_ 2566835198 stFlashMalfcIndcrLamp 3038;
BA_ "SigType" SG_ 2566835198 stFlashMalfcIndcrLamp 4;
BA_ "SigType" SG_ 2566835198 DTC1 7;
BA_ "SigType" SG_ 2566835198 DTC2 7;
BA_ "SigType" SG_ 2566835198 DTC3 7;
BA_ "SigType" SG_ 2566835198 DTC4 7;
BA_ "SigType" SG_ 2566835198 DTC5 7;
BA_ "GenMsgSendType" BO_ 2564816638 7;
BA_ "VFrameFormat" BO_ 2564816638 3;
BA_ "SPN" SG_ 2564816638 stStopStrtCurDataLnk 1230;
BA_ "SigType" SG_ 2564816638 stStopStrtCurDataLnk 5;
BA_ "SPN" SG_ 2564816638 stHldSig 1236;
BA_ "SigType" SG_ 2564816638 stHldSig 5;
BA_ "GenMsgSendType" BO_ 2566834942 7;
BA_ "VFrameFormat" BO_ 2566834942 3;
BA_ "SPN" SG_ 2566834942 stProtLamp 987;
BA_ "SigType" SG_ 2566834942 stProtLamp 4;
BA_ "SPN" SG_ 2566834942 stAmberWarnLamp 624;
BA_ "SigType" SG_ 2566834942 stAmberWarnLamp 4;
BA_ "SPN" SG_ 2566834942 stRedStopLamp 623;
BA_ "SigType" SG_ 2566834942 stRedStopLamp 4;
BA_ "SPN" SG_ 2566834942 stMalfctIndcrLamp 1213;
BA_ "SigType" SG_ 2566834942 stMalfctIndcrLamp 4;
BA_ "SPN" SG_ 2566834942 stFlashProtLamp 3041;
BA_ "SigType" SG_ 2566834942 stFlashProtLamp 4;
BA_ "SPN" SG_ 2566834942 stFlashAmberWarnLamp 3040;
BA_ "SigType" SG_ 2566834942 stFlashAmberWarnLamp 4;
BA_ "SPN" SG_ 2566834942 stFlashRedStopLamp 3039;
BA_ "SigType" SG_ 2566834942 stFlashRedStopLamp 4;
BA_ "SPN" SG_ 2566834942 stFlashMalfcIndcrLamp 3038;
BA_ "SigType" SG_ 2566834942 stFlashMalfcIndcrLamp 4;
BA_ "SigType" SG_ 2566834942 DTC1 7;
BA_ "SigType" SG_ 2566834942 DTC2 7;
BA_ "SigType" SG_ 2566834942 DTC3 7;
BA_ "SigType" SG_ 2566834942 DTC4 7;
BA_ "SigType" SG_ 2566834942 DTC5 7;
BA_ "GenMsgSendType" BO_ 2566838526 7;
BA_ "VFrameFormat" BO_ 2566838526 3;
BA_ "SPN" SG_ 2566838526 nrIdentity 2837;
BA_ "SPN" SG_ 2566838526 dataMnfcCode 2838;
BA_ "SPN" SG_ 2566838526 dataEcuInst 2840;
BA_ "SPN" SG_ 2566838526 dataFctInst 2839;
BA_ "SPN" SG_ 2566838526 dataFct 2841;
BA_ "SPN" SG_ 2566838526 dataVehSys 2842;
BA_ "SPN" SG_ 2566838526 dataVehSysInst 2843;
BA_ "SPN" SG_ 2566838526 dataIndtryGroup 2846;
BA_ "SPN" SG_ 2566838526 flgArbitraryAdrCapable 2844;
BA_ "SPN" SG_ 2566838526 adrSrcNew 2847;
BA_ "GenMsgSendType" BO_ 2565799678 7;
BA_ "VFrameFormat" BO_ 2565799678 3;
BA_ "SPN" SG_ 2565799678 nrIdentity 2837;
BA_ "SPN" SG_ 2565799678 dataMnfcCode 2838;
BA_ "SPN" SG_ 2565799678 dataEcuInst 2840;
BA_ "SPN" SG_ 2565799678 dataFctInst 2839;
BA_ "SPN" SG_ 2565799678 dataFct 2841;
BA_ "SPN" SG_ 2565799678 dataVehSys 2842;
BA_ "SPN" SG_ 2565799678 dataVehSysInst 2843;
BA_ "SPN" SG_ 2565799678 dataIndtryGroup 2846;
BA_ "SPN" SG_ 2565799678 flgArbitraryAdrCapable 2844;
BA_ "VFrameFormat" BO_ 2565406462 3;
BA_ "SPN" SG_ 2565406462 stCtrlByt 2541;
BA_ "SPN" SG_ 2565406462 stGroupFctVal 2542;
BA_ "SigType" SG_ 2565406462 stGroupFctVal 1;
BA_ "SPN" SG_ 2565406462 nrPgn 2543;
BA_ "SigType" SG_ 2565406462 nrPgn 6;

VAL_ 1919 State 127 "PreOperational" 5 "Operational" 4 "Stopped" 0 "Bootup" ;
VAL_ 1918 State 127 "PreOperational" 5 "Operational" 4 "Stopped" 0 "Bootup" ;
VAL_ 1917 State 127 "PreOperational" 5 "Operational" 4 "Stopped" 0 "Bootup" ;
VAL_ 1916 State 127 "PreOperational" 5 "Operational" 4 "Stopped" 0 "Bootup" ;
VAL_ 1915 State 127 "PreOperational" 5 "Operational" 4 "Stopped" 0 "Bootup" ;
VAL_ 1914 State 127 "PreOperational" 5 "Operational" 4 "Stopped" 0 "Bootup" ;
VAL_ 1913 State 127 "PreOperational" 5 "Operational" 4 "Stopped" 0 "Bootup" ;
VAL_ 1912 State 127 "PreOperational" 5 "Operational" 4 "Stopped" 0 "Bootup" ;
VAL_ 1911 State 127 "PreOperational" 5 "Operational" 4 "Stopped" 0 "Bootup" ;
VAL_ 1910 State 127 "PreOperational" 5 "Operational" 4 "Stopped" 0 "Bootup" ;
VAL_ 1909 State 127 "PreOperational" 5 "Operational" 4 "Stopped" 0 "Bootup" ;
VAL_ 1908 State 127 "PreOperational" 5 "Operational" 4 "Stopped" 0 "Bootup" ;
VAL_ 1907 State 127 "PreOperational" 5 "Operational" 4 "Stopped" 0 "Bootup" ;
VAL_ 1906 State 127 "PreOperational" 5 "Operational" 4 "Stopped" 0 "Bootup" ;
VAL_ 1905 State 127 "PreOperational" 5 "Operational" 4 "Stopped" 0 "Bootup" ;
VAL_ 1904 State 127 "PreOperational" 5 "Operational" 4 "Stopped" 0 "Bootup" ;
VAL_ 1903 State 127 "PreOperational" 5 "Operational" 4 "Stopped" 0 "Bootup" ;
VAL_ 1902 State 127 "PreOperational" 5 "Operational" 4 "Stopped" 0 "Bootup" ;
VAL_ 1901 State 127 "PreOperational" 5 "Operational" 4 "Stopped" 0 "Bootup" ;
VAL_ 1900 State 127 "PreOperational" 5 "Operational" 4 "Stopped" 0 "Bootup" ;
VAL_ 1899 State 127 "PreOperational" 5 "Operational" 4 "Stopped" 0 "Bootup" ;
VAL_ 1898 State 127 "PreOperational" 5 "Operational" 4 "Stopped" 0 "Bootup" ;
VAL_ 1897 State 127 "PreOperational" 5 "Operational" 4 "Stopped" 0 "Bootup" ;
VAL_ 1896 State 127 "PreOperational" 5 "Operational" 4 "Stopped" 0 "Bootup" ;
VAL_ 1895 State 127 "PreOperational" 5 "Operational" 4 "Stopped" 0 "Bootup" ;
VAL_ 1894 State 127 "PreOperational" 5 "Operational" 4 "Stopped" 0 "Bootup" ;
VAL_ 1893 State 127 "PreOperational" 5 "Operational" 4 "Stopped" 0 "Bootup" ;
VAL_ 1892 State 127 "PreOperational" 5 "Operational" 4 "Stopped" 0 "Bootup" ;
VAL_ 1891 State 127 "PreOperational" 5 "Operational" 4 "Stopped" 0 "Bootup" ;
VAL_ 1890 State 127 "PreOperational" 5 "Operational" 4 "Stopped" 0 "Bootup" ;
VAL_ 1889 State 127 "PreOperational" 5 "Operational" 4 "Stopped" 0 "Bootup" ;
VAL_ 1888 State 127 "PreOperational" 5 "Operational" 4 "Stopped" 0 "Bootup" ;
VAL_ 1887 State 127 "PreOperational" 5 "Operational" 4 "Stopped" 0 "Bootup" ;
VAL_ 1886 State 127 "PreOperational" 5 "Operational" 4 "Stopped" 0 "Bootup" ;
VAL_ 1885 State 127 "PreOperational" 5 "Operational" 4 "Stopped" 0 "Bootup" ;
VAL_ 1884 State 127 "PreOperational" 5 "Operational" 4 "Stopped" 0 "Bootup" ;
VAL_ 1883 State 127 "PreOperational" 5 "Operational" 4 "Stopped" 0 "Bootup" ;
VAL_ 1882 State 127 "PreOperational" 5 "Operational" 4 "Stopped" 0 "Bootup" ;
VAL_ 1881 State 127 "PreOperational" 5 "Operational" 4 "Stopped" 0 "Bootup" ;
VAL_ 1880 State 127 "PreOperational" 5 "Operational" 4 "Stopped" 0 "Bootup" ;
VAL_ 1879 State 127 "PreOperational" 5 "Operational" 4 "Stopped" 0 "Bootup" ;
VAL_ 1878 State 127 "PreOperational" 5 "Operational" 4 "Stopped" 0 "Bootup" ;
VAL_ 1877 State 127 "PreOperational" 5 "Operational" 4 "Stopped" 0 "Bootup" ;
VAL_ 1876 State 127 "PreOperational" 5 "Operational" 4 "Stopped" 0 "Bootup" ;
VAL_ 1875 State 127 "PreOperational" 5 "Operational" 4 "Stopped" 0 "Bootup" ;
VAL_ 1874 State 127 "PreOperational" 5 "Operational" 4 "Stopped" 0 "Bootup" ;
VAL_ 1873 State 127 "PreOperational" 5 "Operational" 4 "Stopped" 0 "Bootup" ;
VAL_ 1872 State 127 "PreOperational" 5 "Operational" 4 "Stopped" 0 "Bootup" ;
VAL_ 1871 State 127 "PreOperational" 5 "Operational" 4 "Stopped" 0 "Bootup" ;
VAL_ 1870 State 127 "PreOperational" 5 "Operational" 4 "Stopped" 0 "Bootup" ;
VAL_ 1869 State 127 "PreOperational" 5 "Operational" 4 "Stopped" 0 "Bootup" ;
VAL_ 1868 State 127 "PreOperational" 5 "Operational" 4 "Stopped" 0 "Bootup" ;
VAL_ 1867 State 127 "PreOperational" 5 "Operational" 4 "Stopped" 0 "Bootup" ;
VAL_ 1866 State 127 "PreOperational" 5 "Operational" 4 "Stopped" 0 "Bootup" ;
VAL_ 1865 State 127 "PreOperational" 5 "Operational" 4 "Stopped" 0 "Bootup" ;
VAL_ 1864 State 127 "PreOperational" 5 "Operational" 4 "Stopped" 0 "Bootup" ;
VAL_ 1863 State 127 "PreOperational" 5 "Operational" 4 "Stopped" 0 "Bootup" ;
VAL_ 1862 State 127 "PreOperational" 5 "Operational" 4 "Stopped" 0 "Bootup" ;
VAL_ 1861 State 127 "PreOperational" 5 "Operational" 4 "Stopped" 0 "Bootup" ;
VAL_ 1860 State 127 "PreOperational" 5 "Operational" 4 "Stopped" 0 "Bootup" ;
VAL_ 1859 State 127 "PreOperational" 5 "Operational" 4 "Stopped" 0 "Bootup" ;
VAL_ 1858 State 127 "PreOperational" 5 "Operational" 4 "Stopped" 0 "Bootup" ;
VAL_ 1857 State 127 "PreOperational" 5 "Operational" 4 "Stopped" 0 "Bootup" ;
VAL_ 1856 State 127 "PreOperational" 5 "Operational" 4 "Stopped" 0 "Bootup" ;
VAL_ 1855 State 127 "PreOperational" 5 "Operational" 4 "Stopped" 0 "Bootup" ;
VAL_ 1854 State 127 "PreOperational" 5 "Operational" 4 "Stopped" 0 "Bootup" ;
VAL_ 1853 State 127 "PreOperational" 5 "Operational" 4 "Stopped" 0 "Bootup" ;
VAL_ 1852 State 127 "PreOperational" 5 "Operational" 4 "Stopped" 0 "Bootup" ;
VAL_ 1851 State 127 "PreOperational" 5 "Operational" 4 "Stopped" 0 "Bootup" ;
VAL_ 1850 State 127 "PreOperational" 5 "Operational" 4 "Stopped" 0 "Bootup" ;
VAL_ 1849 State 127 "PreOperational" 5 "Operational" 4 "Stopped" 0 "Bootup" ;
VAL_ 1848 State 127 "PreOperational" 5 "Operational" 4 "Stopped" 0 "Bootup" ;
VAL_ 1847 State 127 "PreOperational" 5 "Operational" 4 "Stopped" 0 "Bootup" ;
VAL_ 1846 State 127 "PreOperational" 5 "Operational" 4 "Stopped" 0 "Bootup" ;
VAL_ 1845 State 127 "PreOperational" 5 "Operational" 4 "Stopped" 0 "Bootup" ;
VAL_ 1844 State 127 "PreOperational" 5 "Operational" 4 "Stopped" 0 "Bootup" ;
VAL_ 1843 State 127 "PreOperational" 5 "Operational" 4 "Stopped" 0 "Bootup" ;
VAL_ 1842 State 127 "PreOperational" 5 "Operational" 4 "Stopped" 0 "Bootup" ;
VAL_ 1841 State 127 "PreOperational" 5 "Operational" 4 "Stopped" 0 "Bootup" ;
VAL_ 1840 State 127 "PreOperational" 5 "Operational" 4 "Stopped" 0 "Bootup" ;
VAL_ 1839 State 127 "PreOperational" 5 "Operational" 4 "Stopped" 0 "Bootup" ;
VAL_ 1838 State 127 "PreOperational" 5 "Operational" 4 "Stopped" 0 "Bootup" ;
VAL_ 1837 State 127 "PreOperational" 5 "Operational" 4 "Stopped" 0 "Bootup" ;
VAL_ 1836 State 127 "PreOperational" 5 "Operational" 4 "Stopped" 0 "Bootup" ;
VAL_ 1835 State 127 "PreOperational" 5 "Operational" 4 "Stopped" 0 "Bootup" ;
VAL_ 1834 State 127 "PreOperational" 5 "Operational" 4 "Stopped" 0 "Bootup" ;
VAL_ 1833 State 127 "PreOperational" 5 "Operational" 4 "Stopped" 0 "Bootup" ;
VAL_ 1832 State 127 "PreOperational" 5 "Operational" 4 "Stopped" 0 "Bootup" ;
VAL_ 1831 State 127 "PreOperational" 5 "Operational" 4 "Stopped" 0 "Bootup" ;
VAL_ 1830 State 127 "PreOperational" 5 "Operational" 4 "Stopped" 0 "Bootup" ;
VAL_ 1829 State 127 "PreOperational" 5 "Operational" 4 "Stopped" 0 "Bootup" ;
VAL_ 1828 State 127 "PreOperational" 5 "Operational" 4 "Stopped" 0 "Bootup" ;
VAL_ 1827 State 127 "PreOperational" 5 "Operational" 4 "Stopped" 0 "Bootup" ;
VAL_ 1826 State 127 "PreOperational" 5 "Operational" 4 "Stopped" 0 "Bootup" ;
VAL_ 1825 State 127 "PreOperational" 5 "Operational" 4 "Stopped" 0 "Bootup" ;
VAL_ 1824 State 127 "PreOperational" 5 "Operational" 4 "Stopped" 0 "Bootup" ;
VAL_ 1823 State 127 "PreOperational" 5 "Operational" 4 "Stopped" 0 "Bootup" ;
VAL_ 1822 State 127 "PreOperational" 5 "Operational" 4 "Stopped" 0 "Bootup" ;
VAL_ 1821 State 127 "PreOperational" 5 "Operational" 4 "Stopped" 0 "Bootup" ;
VAL_ 1820 State 127 "PreOperational" 5 "Operational" 4 "Stopped" 0 "Bootup" ;
VAL_ 1819 State 127 "PreOperational" 5 "Operational" 4 "Stopped" 0 "Bootup" ;
VAL_ 1818 State 127 "PreOperational" 5 "Operational" 4 "Stopped" 0 "Bootup" ;
VAL_ 1817 State 127 "PreOperational" 5 "Operational" 4 "Stopped" 0 "Bootup" ;
VAL_ 1816 State 127 "PreOperational" 5 "Operational" 4 "Stopped" 0 "Bootup" ;
VAL_ 1815 State 127 "PreOperational" 5 "Operational" 4 "Stopped" 0 "Bootup" ;
VAL_ 1814 State 127 "PreOperational" 5 "Operational" 4 "Stopped" 0 "Bootup" ;
VAL_ 1813 State 127 "PreOperational" 5 "Operational" 4 "Stopped" 0 "Bootup" ;
VAL_ 1812 State 127 "PreOperational" 5 "Operational" 4 "Stopped" 0 "Bootup" ;
VAL_ 1811 State 127 "PreOperational" 5 "Operational" 4 "Stopped" 0 "Bootup" ;
VAL_ 1810 State 127 "PreOperational" 5 "Operational" 4 "Stopped" 0 "Bootup" ;
VAL_ 1809 State 127 "PreOperational" 5 "Operational" 4 "Stopped" 0 "Bootup" ;
VAL_ 1808 State 127 "PreOperational" 5 "Operational" 4 "Stopped" 0 "Bootup" ;
VAL_ 1807 State 127 "PreOperational" 5 "Operational" 4 "Stopped" 0 "Bootup" ;
VAL_ 1806 State 127 "PreOperational" 5 "Operational" 4 "Stopped" 0 "Bootup" ;
VAL_ 1805 State 127 "PreOperational" 5 "Operational" 4 "Stopped" 0 "Bootup" ;
VAL_ 1804 State 127 "PreOperational" 5 "Operational" 4 "Stopped" 0 "Bootup" ;
VAL_ 1803 State 127 "PreOperational" 5 "Operational" 4 "Stopped" 0 "Bootup" ;
VAL_ 1802 State 127 "PreOperational" 5 "Operational" 4 "Stopped" 0 "Bootup" ;
VAL_ 1801 State 127 "PreOperational" 5 "Operational" 4 "Stopped" 0 "Bootup" ;
VAL_ 1800 State 127 "PreOperational" 5 "Operational" 4 "Stopped" 0 "Bootup" ;
VAL_ 1799 State 127 "PreOperational" 5 "Operational" 4 "Stopped" 0 "Bootup" ;
VAL_ 1798 State 127 "PreOperational" 5 "Operational" 4 "Stopped" 0 "Bootup" ;
VAL_ 1797 State 127 "PreOperational" 5 "Operational" 4 "Stopped" 0 "Bootup" ;
VAL_ 1796 State 127 "PreOperational" 5 "Operational" 4 "Stopped" 0 "Bootup" ;
VAL_ 1795 State 127 "PreOperational" 5 "Operational" 4 "Stopped" 0 "Bootup" ;
VAL_ 1794 State 127 "PreOperational" 5 "Operational" 4 "Stopped" 0 "Bootup" ;
VAL_ 1793 State 127 "PreOperational" 5 "Operational" 4 "Stopped" 0 "Bootup" ;
VAL_ 0 Node_ID 0 "All" ;
VAL_ 0 CS 130 "Reset Communication" 129 "Reset Node" 128 "Enter Pre-Operational" 2 "Stop" 1 "Start" ;
VAL_ 2565865475 flgPwrOff 0 "Off" 1 "On" 2 "Error" 3 "Not available" ;
VAL_ 2565865475 flgFw 0 "Off" 1 "On" 2 "Error" 3 "Not available" ;
VAL_ 2565865475 flgRampStopNeutDmd 0 "Off" 1 "On" 2 "Error" 3 "Not available" ;
VAL_ 2565865475 flgFrzPrmMod 0 "Off" 1 "On" 2 "Error" 3 "Not available" ;
VAL_ 2565865475 flgPrmModChgLock 0 "Off" 1 "On" 2 "Error" 3 "Not available" ;
VAL_ 2565865475 flgAppExeRelsInhb 0 "Off" 1 "On" 2 "Error" 3 "Not available" ;
VAL_ 2565865475 flgAppExeRelsErr 0 "Off" 1 "On" 2 "Error" 3 "Not available" ;
VAL_ 2565865475 flgFltLampSlowFlash 0 "Off" 1 "On" 2 "Error" 3 "Not available" ;
VAL_ 2565865475 flgFltLampOn 0 "Off" 1 "On" 2 "Error" 3 "Not available" ;
VAL_ 2566835198 stProtLamp 0 "Lamp off" 1 "Lamp on" 2 "Reserved" 3 "Not available" ;
VAL_ 2566835198 stAmberWarnLamp 0 "Lamp off" 1 "Lamp on" 2 "Reserved" 3 "Not available" ;
VAL_ 2566835198 stRedStopLamp 0 "Lamp off" 1 "Lamp on" 2 "Reserved" 3 "Not available" ;
VAL_ 2566835198 stMalfctIndcrLamp 0 "Lamp off" 1 "Lamp on" 2 "Reserved" 3 "Not available" ;
VAL_ 2566835198 stFlashProtLamp 0 "Slow Flash" 1 "Fast Flash" 2 "Reserved" 3 "Unavailable" ;
VAL_ 2566835198 stFlashAmberWarnLamp 0 "Slow Flash" 1 "Fast Flash" 2 "Reserved" 3 "Unavailable" ;
VAL_ 2566835198 stFlashRedStopLamp 0 "Slow Flash" 1 "Fast Flash" 2 "Reserved" 3 "Unavailable" ;
VAL_ 2566835198 stFlashMalfcIndcrLamp 0 "Slow Flash" 1 "Fast Flash" 2 "Reserved" 3 "Unavailable" ;
VAL_ 2566834942 stProtLamp 0 "Lamp off" 1 "Lamp on" 2 "Reserved" 3 "Not available" ;
VAL_ 2566834942 stAmberWarnLamp 0 "Lamp off" 1 "Lamp on" 2 "Reserved" 3 "Not available" ;
VAL_ 2566834942 stRedStopLamp 0 "Lamp off" 1 "Lamp on" 2 "Reserved" 3 "Not available" ;
VAL_ 2566834942 stMalfctIndcrLamp 0 "Lamp off" 1 "Lamp on" 2 "Reserved" 3 "Not available" ;
VAL_ 2566834942 stFlashProtLamp 0 "Slow Flash" 1 "Fast Flash" 2 "Reserved" 3 "Unavailable" ;
VAL_ 2566834942 stFlashAmberWarnLamp 0 "Slow Flash" 1 "Fast Flash" 2 "Reserved" 3 "Unavailable" ;
VAL_ 2566834942 stFlashRedStopLamp 0 "Slow Flash" 1 "Fast Flash" 2 "Reserved" 3 "Unavailable" ;
VAL_ 2566834942 stFlashMalfcIndcrLamp 0 "Slow Flash" 1 "Fast Flash" 2 "Reserved" 3 "Unavailable" ;
